VERSION ""

NS_ :

BS_:

BU_: CVC_C EPS WCBS FCAM_C ADCU_C DUMMY_ECU

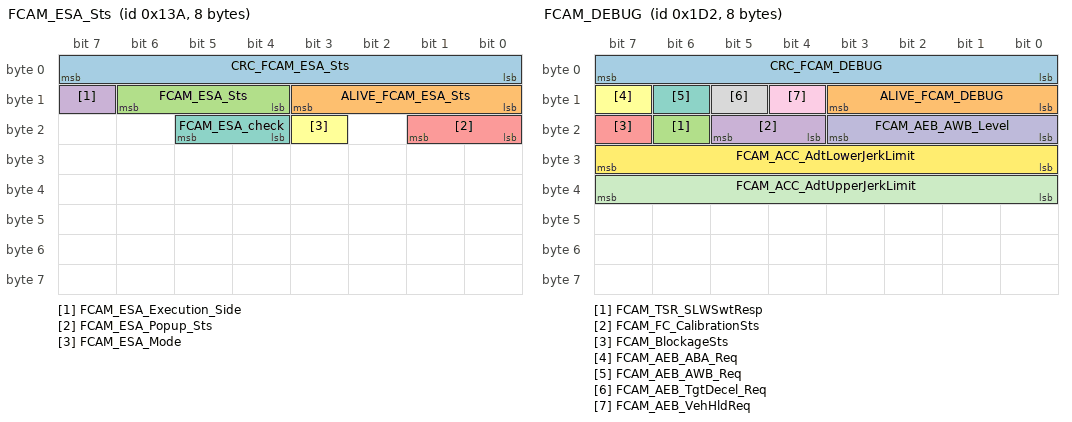
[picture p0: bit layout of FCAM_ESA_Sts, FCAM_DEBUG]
BO_ 314 FCAM_ESA_Sts: 8 FCAM_C
 SG_ CRC_FCAM_ESA_Sts : 7|8@0+ (1,0) [0|255] ""  CVC_C,EPS
 SG_ ALIVE_FCAM_ESA_Sts : 11|4@0+ (1,0) [0|15] ""  CVC_C,EPS
 SG_ FCAM_ESA_Sts : 14|3@0+ (1,0) [0|7] ""  CVC_C,EPS
 SG_ FCAM_ESA_Execution_Side : 15|1@0+ (1,0) [0|1] ""  CVC_C,EPS
 SG_ FCAM_ESA_Popup_Sts : 17|2@0+ (1,0) [0|3] ""  CVC_C,EPS
 SG_ FCAM_ESA_Mode : 19|1@0+ (1,0) [0|1] ""  CVC_C,EPS
 SG_ FCAM_ESA_check : 21|2@0+ (1,0) [0|3] ""  CVC_C,EPS

BO_ 466 FCAM_DEBUG: 8 FCAM_C
 SG_ CRC_FCAM_DEBUG : 7|8@0+ (1,0) [0|255] ""  CVC_C,WCBS,ADCU_C
 SG_ ALIVE_FCAM_DEBUG : 11|4@0+ (1,0) [0|15] ""  CVC_C,WCBS,ADCU_C
 SG_ FCAM_TSR_SLWSwtResp : 22|1@0+ (1,0) [0|1] ""  CVC_C,ADCU_C
 SG_ FCAM_FC_CalibrationSts : 21|2@0+ (1,0) [0|3] ""  CVC_C,ADCU_C
 SG_ FCAM_BlockageSts : 23|1@0+ (1,0) [0|1] ""  CVC_C,ADCU_C
 SG_ FCAM_AEB_ABA_Req : 15|1@0+ (1,0) [0|1] ""  CVC_C,WCBS,ADCU_C
 SG_ FCAM_AEB_AWB_Req : 14|1@0+ (1,0) [0|1] ""  CVC_C,WCBS,ADCU_C
 SG_ FCAM_AEB_TgtDecel_Req : 13|1@0+ (1,0) [0|1] ""  CVC_C,WCBS,ADCU_C
 SG_ FCAM_AEB_VehHldReq : 12|1@0+ (1,0) [0|1] ""  CVC_C,WCBS,ADCU_C
 SG_ FCAM_AEB_AWB_Level : 19|4@0+ (1,0) [0|15] ""  CVC_C,WCBS,ADCU_C
 SG_ FCAM_ACC_AdtUpperJerkLimit : 39|8@0+ (0.1,-12.7) [-12.7|12.7] "m/s3"  CVC_C,WCBS,ADCU_C
 SG_ FCAM_ACC_AdtLowerJerkLimit : 31|8@0+ (0.1,-12.7) [-12.7|12.7] "m/s3"  CVC_C,WCBS,ADCU_C

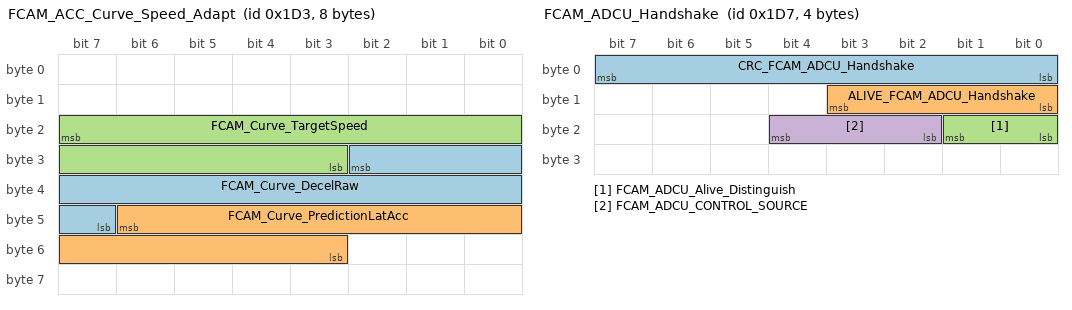
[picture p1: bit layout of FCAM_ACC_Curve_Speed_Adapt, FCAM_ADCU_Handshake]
BO_ 467 FCAM_ACC_Curve_Speed_Adapt: 8 FCAM_C
 SG_ FCAM_Curve_DecelRaw : 26|12@0+ (0.005,-6) [-6|6] "m/s2"  CVC_C
 SG_ FCAM_Curve_PredictionLatAcc : 46|12@0+ (0.005,-6) [-6|6] "m/s2"  CVC_C
 SG_ FCAM_Curve_TargetSpeed : 23|13@0+ (0.05625,0) [0|300] "km/h"  CVC_C

BO_ 471 FCAM_ADCU_Handshake: 4 FCAM_C
 SG_ CRC_FCAM_ADCU_Handshake : 7|8@0+ (1,0) [0|255] ""  ADCU_C
 SG_ ALIVE_FCAM_ADCU_Handshake : 11|4@0+ (1,0) [0|15] ""  ADCU_C
 SG_ FCAM_ADCU_Alive_Distinguish : 17|2@0+ (1,0) [0|2] ""  ADCU_C
 SG_ FCAM_ADCU_CONTROL_SOURCE : 20|3@0+ (1,0) [0|3] ""  ADCU_C

BO_ 813 FCAM_ACC_Status: 24 FCAM_C
 SG_ CRC_FCAM_ACC_Status : 7|8@0+ (1,0) [0|255] ""  CVC_C,WCBS
 SG_ ALIVE_FCAM_ACC_Status : 11|4@0+ (1,0) [0|15] ""  CVC_C,WCBS
 SG_ FCAM_ACC_Information : 14|2@0+ (1,0) [0|3] ""  WCBS
 SG_ FCAM_ACC_Main_Mode : 15|1@0+ (1,0) [0|1] ""  WCBS
 SG_ FCAM_ACC_AccelDecel_Cmd : 19|12@0+ (0.005,-6) [-6|6] "m/s2"  WCBS
 SG_ FCAM_ACC_StandstillReq : 20|1@0+ (1,0) [0|1] ""  WCBS
 SG_ FCAM_ACC_Mode : 23|3@0+ (1,0) [0|7] ""  CVC_C,WCBS
 SG_ FCAM_ACC_IDB_DecCmdAct : 39|3@0+ (1,0) [0|1] ""  WCBS
 SG_ Secure_ResetCnt_0x32D : 135|16@0+ (1,0) [0|65535] ""  CVC_C,WCBS
 SG_ Secure_MsgCnt_0x32D : 151|16@0+ (1,0) [0|65535] ""  CVC_C,WCBS
 SG_ Secure_MAC_0x32D : 167|32@0+ (1,0) [0|4294967295] ""  CVC_C,WCBS

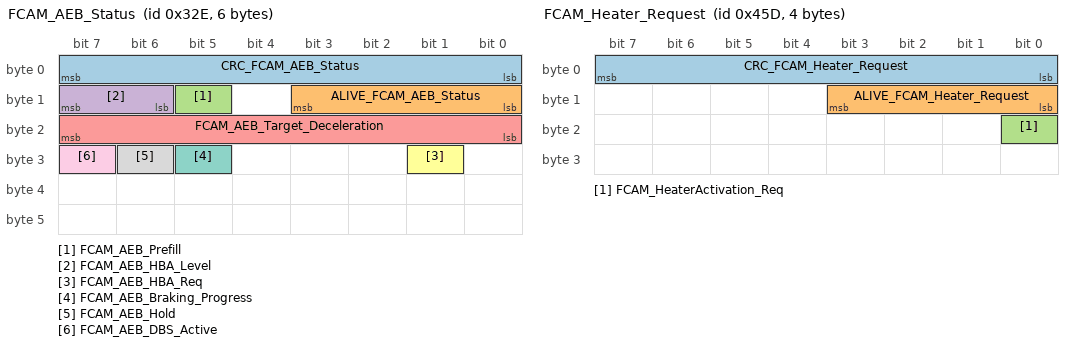
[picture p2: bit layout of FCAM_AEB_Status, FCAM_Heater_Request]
BO_ 814 FCAM_AEB_Status: 6 FCAM_C
 SG_ CRC_FCAM_AEB_Status : 7|8@0+ (1,0) [0|255] ""  CVC_C,WCBS
 SG_ ALIVE_FCAM_AEB_Status : 11|4@0+ (1,0) [0|15] ""  CVC_C,WCBS
 SG_ FCAM_AEB_Prefill : 13|1@0+ (1,0) [0|1] ""  CVC_C,WCBS
 SG_ FCAM_AEB_HBA_Level : 15|2@0+ (1,0) [0|3] ""  CVC_C,WCBS
 SG_ FCAM_AEB_Target_Deceleration : 23|8@0+ (0.1,-12.7) [-12.7|12.8] "m/s2"  CVC_C,WCBS
 SG_ FCAM_AEB_HBA_Req : 25|1@0+ (1,0) [0|1] ""  CVC_C,WCBS
 SG_ FCAM_AEB_Braking_Progress : 29|1@0+ (1,0) [0|1] ""  CVC_C,WCBS
 SG_ FCAM_AEB_Hold : 30|1@0+ (1,0) [0|1] ""  CVC_C,WCBS
 SG_ FCAM_AEB_DBS_Active : 31|1@0+ (1,0) [0|1] ""  CVC_C,WCBS

BO_ 851 FCAM_CMP_ACC: 8 FCAM_C
 SG_ CRC_FCAM_CMP_ACC : 7|8@0+ (1,0) [0|255] ""  WCBS
 SG_ ALIVE_FCAM_CMP_ACC : 11|4@0+ (1,0) [0|15] ""  WCBS
 SG_ FCAM_ACC_ObjDetec : 29|1@0+ (1,0) [0|1] ""  DUMMY_ECU
 SG_ FCAM_ISA_check : 13|2@0+ (1,0) [0|3] ""  DUMMY_ECU
 SG_ FCAM_ISA_Mode_SW_Feed : 15|2@0+ (1,0) [0|3] ""  DUMMY_ECU
 SG_ FCAM_TagSpeed_ICON_Feed : 18|3@0+ (1,0) [0|7] ""  WCBS
 SG_ FCAM_ISA_PopUp_Feed : 23|4@0+ (1,0) [0|15] ""  DUMMY_ECU
 SG_ FCAM_ISA_Btn_Feed : 24|1@0+ (1,0) [0|1] ""  DUMMY_ECU
 SG_ FCAM_ACC_DistSet_upper_Feed : 25|1@0+ (1,0) [0|1] ""  DUMMY_ECU
 SG_ FCAM_ACC_TimeGapSet : 28|3@0+ (1,0) [0|7] ""  DUMMY_ECU
 SG_ FCAM_ACC_State : 47|4@0+ (1,0) [0|15] ""  DUMMY_ECU
 SG_ FCAM_ACC_TagSpeed : 39|8@0+ (1,0) [0|255] "km/h"  WCBS
 SG_ FCAM_ACC_PopUp_Feed : 43|4@0+ (1,0) [0|15] ""  DUMMY_ECU
 SG_ FCAM_ACC_check : 31|2@0+ (1,0) [0|3] ""  DUMMY_ECU
 SG_ FCAM_ISA_ICON_Feed : 50|3@0+ (1,0) [0|7] ""  DUMMY_ECU
 SG_ FCAM_ACC_DistSet_lower_Feed : 51|1@0+ (1,0) [0|1] ""  DUMMY_ECU
 SG_ FCAM_ACC_SpdSet_upper_Feed : 52|1@0+ (1,0) [0|1] ""  DUMMY_ECU
 SG_ FCAM_ACC_SpdSet_lower_Feed : 53|1@0+ (1,0) [0|1] ""  DUMMY_ECU
 SG_ FCAM_ACC_On_Feed : 54|1@0+ (1,0) [0|1] ""  DUMMY_ECU
 SG_ FCAM_ACC_Set_Feed : 55|1@0+ (1,0) [0|1] ""  DUMMY_ECU
 SG_ FCAM_ACC_CnlBtn_Feed : 56|1@0+ (1,0) [0|1] ""  DUMMY_ECU
 SG_ FCAM_ACC_Res_Feed : 57|1@0+ (1,0) [0|1] ""  DUMMY_ECU
 SG_ FCAM_ACC_ICON_Feed : 60|3@0+ (1,0) [0|7] ""  WCBS
 SG_ FCAM_ISA_Status : 63|3@0+ (1,0) [0|7] ""  DUMMY_ECU
 SG_ FCAM_ACC_DriveOff : 19|1@0+ (1,0) [0|1] ""  DUMMY_ECU

BO_ 890 FCAM_EPS_LATE_CON: 24 FCAM_C
 SG_ CRC_FCAM_EPS_LATE_CON : 7|8@0+ (1,0) [0|255] ""  EPS
 SG_ ALIVE_FCAM_EPS_LATE_CON : 11|4@0+ (1,0) [0|15] ""  EPS
 SG_ FCAM_EPS_StrWhe_TOLAct : 25|2@0+ (1,0) [0|3] ""  EPS
 SG_ FCAM_EPS_StrWhe_AOLAct : 27|2@0+ (1,0) [0|3] ""  EPS
 SG_ FCAM_EPS_AOLReq : 39|16@0+ (0.0238,-780) [-780|779.7] "deg"  EPS
 SG_ FCAM_EPS_Torq_Fact_Req : 55|7@0+ (0.01,0) [0|1] ""  EPS
 SG_ FCAM_EPS_DrvTorq_SubFact_Req : 23|7@0+ (0.05,0) [0|1] ""  EPS
 SG_ Secure_ResetCnt_0x37A : 135|16@0+ (1,0) [0|65535] ""  EPS
 SG_ Secure_MsgCnt_0x37A : 151|16@0+ (1,0) [0|65535] ""  EPS
 SG_ Secure_MAC_0x37A : 167|32@0+ (1,0) [0|4294967295] ""  EPS

BO_ 1117 FCAM_Heater_Request: 4 FCAM_C
 SG_ CRC_FCAM_Heater_Request : 7|8@0+ (1,0) [0|255] ""  CVC_C
 SG_ ALIVE_FCAM_Heater_Request : 11|4@0+ (1,0) [0|15] ""  CVC_C
 SG_ FCAM_HeaterActivation_Req : 16|1@0+ (1,0) [0|1] ""  CVC_C

BO_ 853 FCAM_ADAS_CDSMaster: 12 FCAM_C
 SG_ FCAM_ADAS_CDSMaster_BasicCruise : 7|2@0+ (1,0) [0|3] ""  CVC_C
 SG_ FCAM_ADAS_CDSMaster_ALCA : 5|2@0+ (1,0) [0|3] ""  CVC_C,EPS
 SG_ FCAM_ADAS_CDSMaster_AESA : 3|2@0+ (1,0) [0|3] ""  CVC_C,EPS,WCBS
 SG_ FCAM_ADAS_CDSMaster_HWA : 1|2@0+ (1,0) [0|3] ""  CVC_C,EPS,WCBS
 SG_ FCAM_ADAS_CDSMaster_NOP : 15|2@0+ (1,0) [0|3] ""  CVC_C,EPS,WCBS
 SG_ FCAM_ADAS_CDSMaster_ISA : 13|2@0+ (1,0) [0|3] ""  CVC_C
 SG_ FCAM_ADAS_CDSMaster_TSR : 11|2@0+ (1,0) [0|3] ""  CVC_C
 SG_ FCAM_ADAS_CDSMaster_ACC : 9|2@0+ (1,0) [0|3] ""  CVC_C,WCBS
 SG_ FCAM_ADAS_CDSMaster_TLD : 23|2@0+ (1,0) [0|3] ""  CVC_C,EPS,WCBS
 SG_ FCAM_ADAS_CDSMaster_AACC : 21|2@0+ (1,0) [0|3] ""  CVC_C,EPS,WCBS
 SG_ FCAM_ADAS_CDSMaster_ALCM : 19|2@0+ (1,0) [0|3] ""  CVC_C,EPS,WCBS
 SG_ FCAM_ADAS_CDSMaster_AAESA : 17|2@0+ (1,0) [0|3] ""  CVC_C,EPS,WCBS
 SG_ FCAM_ADAS_CDSMaster_ELK : 31|2@0+ (1,0) [0|3] ""  CVC_C,EPS
 SG_ FCAM_ADAS_CDSMaster_LKA : 29|2@0+ (1,0) [0|3] ""  CVC_C,EPS
 SG_ FCAM_ADAS_CDSMaster_LDW : 27|2@0+ (1,0) [0|3] ""  CVC_C,WCBS
 SG_ FCAM_ADAS_CDSMaster_DNS : 25|2@0+ (1,0) [0|3] ""  CVC_C,EPS,WCBS
 SG_ FCAM_ADAS_CDSMaster_FCW : 39|2@0+ (1,0) [0|3] ""  CVC_C
 SG_ FCAM_ADAS_CDSMaster_RAEB : 37|2@0+ (1,0) [0|3] ""  CVC_C,WCBS
 SG_ FCAM_ADAS_CDSMaster_ESA : 35|2@0+ (1,0) [0|3] ""  CVC_C,EPS
 SG_ FCAM_ADAS_CDSMaster_FAEB : 33|2@0+ (1,0) [0|3] ""  CVC_C,WCBS
 SG_ FCAM_ADAS_CDSMaster_RPA : 47|2@0+ (1,0) [0|3] ""  CVC_C,EPS,WCBS
 SG_ FCAM_ADAS_CDSMaster_FPA : 45|2@0+ (1,0) [0|3] ""  CVC_C,EPS,WCBS
 SG_ FCAM_ADAS_CDSMaster_RVC : 43|2@0+ (1,0) [0|3] ""  CVC_C
 SG_ FCAM_ADAS_CDSMaster_SVM : 41|2@0+ (1,0) [0|3] ""  CVC_C
 SG_ FCAM_ADAS_CDSMaster_VParkingComf : 55|2@0+ (1,0) [0|3] ""  CVC_C,EPS,WCBS
 SG_ FCAM_ADAS_CDSMaster_VParkingSele : 53|2@0+ (1,0) [0|3] ""  CVC_C,EPS,WCBS
 SG_ FCAM_ADAS_CDSMaster_RP : 51|2@0+ (1,0) [0|3] ""  CVC_C,EPS,WCBS
 SG_ FCAM_ADAS_CDSMaster_SpaFAPA : 49|2@0+ (1,0) [0|3] ""  CVC_C,EPS,WCBS
 SG_ FCAM_ADAS_CDSMaster_ADB : 63|2@0+ (1,0) [0|3] ""  CVC_C
 SG_ FCAM_ADAS_CDSMaster_AHB : 61|2@0+ (1,0) [0|3] ""  CVC_C
 SG_ FCAM_ADAS_CDSMaster_VParkingAuto : 59|2@0+ (1,0) [0|3] ""  CVC_C,EPS,WCBS
 SG_ FCAM_ADAS_CDSMaster_VParkingSumm : 57|2@0+ (1,0) [0|3] ""  CVC_C,EPS,WCBS
 SG_ FCAM_ADAS_CDSMaster_AdasEDR : 71|2@0+ (1,0) [0|3] ""  CVC_C
 SG_ FCAM_ADAS_CDSMaster_DCM : 69|2@0+ (1,0) [0|3] ""  CVC_C
 SG_ FCAM_ADAS_CDSMaster_DMSFaceID : 67|2@0+ (1,0) [0|3] ""  CVC_C
 SG_ FCAM_ADAS_CDSMaster_DMS : 65|2@0+ (1,0) [0|3] ""  CVC_C
 SG_ FCAM_ADAS_CDSMaster_L2_L2PLUS : 77|2@0+ (1,0) [0|3] ""  CVC_C,EPS,WCBS
 SG_ FCAM_ADAS_CDSMaster_SentryMode : 75|2@0+ (1,0) [0|3] ""  CVC_C
 SG_ FCAM_ADAS_CDSMaster_ACPE : 73|2@0+ (1,0) [0|3] ""  CVC_C,WCBS

BO_ 1970 FCAM_Synchronization_Req: 8 FCAM_C
 SG_ FCAM_C_Req_RandomData : 7|24@0+ (1,0) [0|16777215] ""  CVC_C
 SG_ FCAM_C_Req_MAC : 31|40@0+ (1,0) [0|1099511627775] ""  CVC_C

BO_ 311 EAS_CDC_WorkState: 8 CVC_C
 SG_ CRC_EAS_CDC_WorkState : 7|8@0+ (1,0) [0|255] ""  FCAM_C,ADCU_C
 SG_ ALIVE_EAS_CDC_WorkState : 11|4@0+ (1,0) [0|15] ""  FCAM_C,ADCU_C
 SG_ EAS_StiffStsFL : 12|1@0+ (1,0) [0|1] "" Vector__XXX
 SG_ EAS_StiffStsFR : 13|1@0+ (1,0) [0|1] "" Vector__XXX
 SG_ EAS_StiffStsRL : 14|1@0+ (1,0) [0|1] "" Vector__XXX
 SG_ EAS_StiffStsRR : 15|1@0+ (1,0) [0|1] "" Vector__XXX
 SG_ EAS_WorkSts : 17|2@0+ (1,0) [0|3] ""  FCAM_C,ADCU_C
 SG_ CDC_WorkSts : 19|2@0+ (1,0) [0|3] ""  FCAM_C,ADCU_C
 SG_ EAS_CDC_SystemWorkMode : 21|2@0+ (1,0) [0|3] ""  FCAM_C,ADCU_C
 SG_ EAS_SuspensionMode : 23|2@0+ (1,0) [0|3] ""  FCAM_C,ADCU_C
 SG_ EAS_EasyAccessSts : 25|2@0+ (1,0) [0|3] ""  FCAM_C,ADCU_C
 SG_ CDC_DamperMode : 27|2@0+ (1,0) [0|3] ""  FCAM_C,ADCU_C
 SG_ EAS_ValveValue_FL : 30|3@0+ (1,0) [0|7] ""  FCAM_C,ADCU_C
 SG_ EAS_ValveValue_FR : 34|3@0+ (1,0) [0|7] ""  FCAM_C,ADCU_C
 SG_ EAS_ValveValue_RL : 38|3@0+ (1,0) [0|7] ""  FCAM_C,ADCU_C
 SG_ EAS_ValveValue_RR : 42|3@0+ (1,0) [0|7] ""  FCAM_C,ADCU_C
 SG_ EAS_EnableSts : 31|1@0+ (1,0) [0|1] ""  FCAM_C,ADCU_C
 SG_ CDC_ValveValue_FL : 35|1@0+ (1,0) [0|1] ""  FCAM_C,ADCU_C
 SG_ CDC_ValveValue_FR : 39|1@0+ (1,0) [0|1] ""  FCAM_C,ADCU_C
 SG_ CDC_ValveValue_RL : 43|1@0+ (1,0) [0|1] ""  FCAM_C,ADCU_C
 SG_ CDC_ValveValue_RR : 44|1@0+ (1,0) [0|1] ""  FCAM_C,ADCU_C
 SG_ EAS_MntnSts : 45|1@0+ (1,0) [0|1] ""  FCAM_C,ADCU_C
 SG_ EAS_EasyLoadingSetFb : 47|2@0+ (1,0) [0|3] ""  FCAM_C,ADCU_C
 SG_ EAS_LiftModFb : 49|2@0+ (1,0) [0|3] ""  FCAM_C,ADCU_C
 SG_ EAS_VehicleUpDownState : 51|2@0+ (1,0) [0|3] ""  FCAM_C,ADCU_C
 SG_ EAS_Overheat_Warning : 52|1@0+ (1,0) [0|1] ""  ADCU_C
 SG_ EAS_VehiclePositionState : 55|3@0+ (1,0) [0|7] ""  ADCU_C
 SG_ EAS_VehicleTargetPositionState : 58|3@0+ (1,0) [0|7] ""  ADCU_C

BO_ 555 ADCU_FCAM_ActuatorReq: 12 ADCU_C
 SG_ CRC_ADCU_FCAM_ActuatorReq : 7|8@0+ (1,0) [0|255] ""  FCAM_C
 SG_ ALIVE_ADCU_FCAM_ActuatorReq : 11|4@0+ (1,0) [0|15] ""  FCAM_C
 SG_ ADCU_ACC_AccelDecel_Cmd : 23|12@0+ (0.005,-6) [-6|6] "m/s2"  FCAM_C
 SG_ ADCU_ACC_IDB_DecCmdAct : 27|3@0+ (1,0) [0|1] ""  FCAM_C
 SG_ ADCU_ACC_StandstillReq : 24|1@0+ (1,0) [0|1] ""  FCAM_C
 SG_ ADCU_ACC_Information : 15|2@0+ (1,0) [0|3] ""  FCAM_C
 SG_ ADCU_ACC_DriveOff : 48|1@0+ (1,0) [0|1] ""  FCAM_C
 SG_ ADCU_EPS_AOLReq : 39|16@0+ (0.0238,-780) [-780|779.7] "deg"  FCAM_C
 SG_ ADCU_EPS_StrWhe_AOLAct : 13|2@0+ (1,0) [0|3] ""  FCAM_C
 SG_ ADCU_EPS_StrWhe_TOLAct : 63|2@0+ (1,0) [0|3] ""  FCAM_C
 SG_ ADCU_EPS_Torq_Fact_Req : 55|7@0+ (0.01,0) [0|1] ""  FCAM_C
 SG_ ADCU_LSS_Activation : 58|3@0+ (1,0) [0|7] ""  FCAM_C
 SG_ ADCU_LSS_Activation_2 : 61|3@0+ (1,0) [0|7] ""  FCAM_C
 SG_ ADCU_NOP_state : 71|4@0+ (1,0) [0|15] ""  FCAM_C

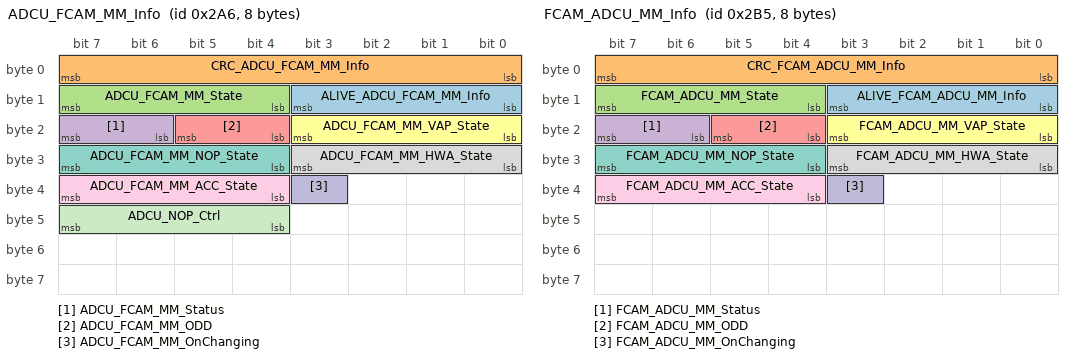
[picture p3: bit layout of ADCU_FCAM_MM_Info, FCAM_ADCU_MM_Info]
BO_ 678 ADCU_FCAM_MM_Info: 8 ADCU_C
 SG_ ALIVE_ADCU_FCAM_MM_Info : 11|4@0+ (1,0) [0|15] ""  FCAM_C
 SG_ CRC_ADCU_FCAM_MM_Info : 7|8@0+ (1,0) [0|255] ""  FCAM_C
 SG_ ADCU_FCAM_MM_State : 15|4@0+ (1,0) [0|15] ""  FCAM_C
 SG_ ADCU_FCAM_MM_Status : 23|2@0+ (1,0) [0|3] ""  FCAM_C
 SG_ ADCU_FCAM_MM_ODD : 21|2@0+ (1,0) [0|3] ""  FCAM_C
 SG_ ADCU_FCAM_MM_VAP_State : 19|4@0+ (1,0) [0|15] ""  FCAM_C
 SG_ ADCU_FCAM_MM_NOP_State : 31|4@0+ (1,0) [0|15] ""  FCAM_C
 SG_ ADCU_FCAM_MM_HWA_State : 27|4@0+ (1,0) [0|15] ""  FCAM_C
 SG_ ADCU_FCAM_MM_ACC_State : 39|4@0+ (1,0) [0|15] ""  FCAM_C
 SG_ ADCU_FCAM_MM_OnChanging : 35|1@0+ (1,0) [0|1] ""  FCAM_C
 SG_ ADCU_NOP_Ctrl : 47|4@0+ (1,0) [0|15] ""  FCAM_C

BO_ 693 FCAM_ADCU_MM_Info: 8 FCAM_C
 SG_ ALIVE_FCAM_ADCU_MM_Info : 11|4@0+ (1,0) [0|15] ""  ADCU_C
 SG_ CRC_FCAM_ADCU_MM_Info : 7|8@0+ (1,0) [0|255] ""  ADCU_C
 SG_ FCAM_ADCU_MM_State : 15|4@0+ (1,0) [0|15] ""  ADCU_C
 SG_ FCAM_ADCU_MM_Status : 23|2@0+ (1,0) [0|3] ""  ADCU_C
 SG_ FCAM_ADCU_MM_ODD : 21|2@0+ (1,0) [0|3] ""  ADCU_C
 SG_ FCAM_ADCU_MM_VAP_State : 19|4@0+ (1,0) [0|15] ""  ADCU_C
 SG_ FCAM_ADCU_MM_NOP_State : 31|4@0+ (1,0) [0|15] ""  ADCU_C
 SG_ FCAM_ADCU_MM_HWA_State : 27|4@0+ (1,0) [0|15] ""  ADCU_C
 SG_ FCAM_ADCU_MM_ACC_State : 39|4@0+ (1,0) [0|15] ""  ADCU_C
 SG_ FCAM_ADCU_MM_OnChanging : 35|1@0+ (1,0) [0|1] ""  ADCU_C

BO_ 821 ADCU_AEB_Status: 12 ADCU_C
 SG_ CRC_ADCU_AEB_Status : 7|8@0+ (1,0) [0|255] ""  WCBS
 SG_ ALIVE_ADCU_AEB_Status : 11|4@0+ (1,0) [0|15] ""  WCBS
 SG_ ADCU_AEB_Prefill : 13|1@0+ (1,0) [0|1] ""  WCBS
 SG_ ADCU_AEB_HBA_Level : 15|2@0+ (1,0) [0|3] ""  WCBS
 SG_ ADCU_AEB_Target_Deceleration : 23|8@0+ (0.1,-12.7) [-12.7|12.8] "m/s2"  WCBS
 SG_ ADCU_AEB_HBA_Req : 25|1@0+ (1,0) [0|1] ""  WCBS
 SG_ ADCU_AEB_Braking_Progress : 29|1@0+ (1,0) [0|1] ""  WCBS
 SG_ ADCU_AEB_Hold : 30|1@0+ (1,0) [0|1] ""  WCBS
 SG_ ADCU_AEB_DBS_Active : 31|1@0+ (1,0) [0|1] ""  WCBS

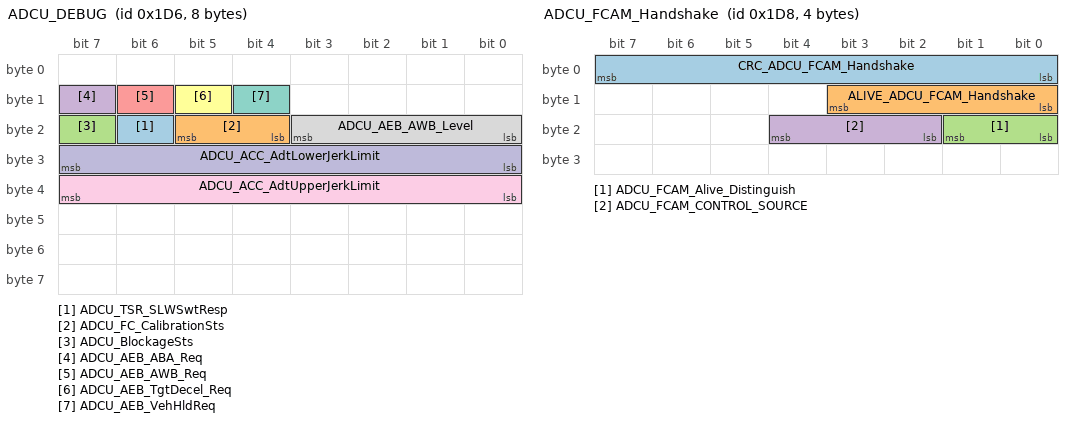
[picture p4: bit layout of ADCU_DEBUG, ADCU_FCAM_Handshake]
BO_ 470 ADCU_DEBUG: 8 ADCU_C
 SG_ ADCU_TSR_SLWSwtResp : 22|1@0+ (1,0) [0|1] ""  CVC_C,WCBS
 SG_ ADCU_FC_CalibrationSts : 21|2@0+ (1,0) [0|3] ""  CVC_C,WCBS
 SG_ ADCU_BlockageSts : 23|1@0+ (1,0) [0|1] ""  CVC_C,WCBS
 SG_ ADCU_AEB_ABA_Req : 15|1@0+ (1,0) [0|1] ""  CVC_C,WCBS
 SG_ ADCU_AEB_AWB_Req : 14|1@0+ (1,0) [0|1] ""  CVC_C,WCBS
 SG_ ADCU_AEB_TgtDecel_Req : 13|1@0+ (1,0) [0|1] ""  CVC_C,WCBS
 SG_ ADCU_AEB_VehHldReq : 12|1@0+ (1,0) [0|1] ""  CVC_C,WCBS
 SG_ ADCU_AEB_AWB_Level : 19|4@0+ (1,0) [0|15] ""  CVC_C,WCBS
 SG_ ADCU_ACC_AdtUpperJerkLimit : 39|8@0+ (0.1,-12.7) [-12.7|12.7] "m/s3"  CVC_C,WCBS
 SG_ ADCU_ACC_AdtLowerJerkLimit : 31|8@0+ (0.1,-12.7) [-12.7|12.7] "m/s3"  CVC_C,WCBS

BO_ 472 ADCU_FCAM_Handshake: 4 ADCU_C
 SG_ CRC_ADCU_FCAM_Handshake : 7|8@0+ (1,0) [0|255] ""  FCAM_C
 SG_ ALIVE_ADCU_FCAM_Handshake : 11|4@0+ (1,0) [0|15] ""  FCAM_C
 SG_ ADCU_FCAM_Alive_Distinguish : 17|2@0+ (1,0) [0|2] ""  FCAM_C
 SG_ ADCU_FCAM_CONTROL_SOURCE : 20|3@0+ (1,0) [0|3] ""  FCAM_C

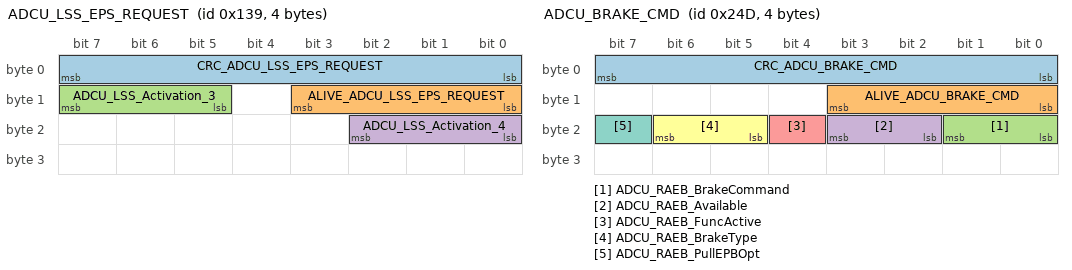
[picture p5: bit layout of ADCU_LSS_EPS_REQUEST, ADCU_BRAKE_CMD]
BO_ 313 ADCU_LSS_EPS_REQUEST: 4 ADCU_C
 SG_ CRC_ADCU_LSS_EPS_REQUEST : 7|8@0+ (1,0) [0|255] ""  EPS
 SG_ ALIVE_ADCU_LSS_EPS_REQUEST : 11|4@0+ (1,0) [0|15] ""  EPS
 SG_ ADCU_LSS_Activation_3 : 15|3@0+ (1,0) [0|7] ""  EPS
 SG_ ADCU_LSS_Activation_4 : 18|3@0+ (1,0) [0|7] ""  EPS

BO_ 589 ADCU_BRAKE_CMD: 4 ADCU_C
 SG_ CRC_ADCU_BRAKE_CMD : 7|8@0+ (1,0) [0|255] ""  WCBS
 SG_ ALIVE_ADCU_BRAKE_CMD : 11|4@0+ (1,0) [0|15] ""  WCBS
 SG_ ADCU_RAEB_BrakeCommand : 17|2@0+ (1,0) [0|3] ""  WCBS
 SG_ ADCU_RAEB_Available : 19|2@0+ (1,0) [0|3] ""  WCBS
 SG_ ADCU_RAEB_FuncActive : 20|1@0+ (1,0) [0|1] ""  WCBS
 SG_ ADCU_RAEB_BrakeType : 22|2@0+ (1,0) [0|3] ""  WCBS
 SG_ ADCU_RAEB_PullEPBOpt : 23|1@0+ (1,0) [0|1] ""  WCBS

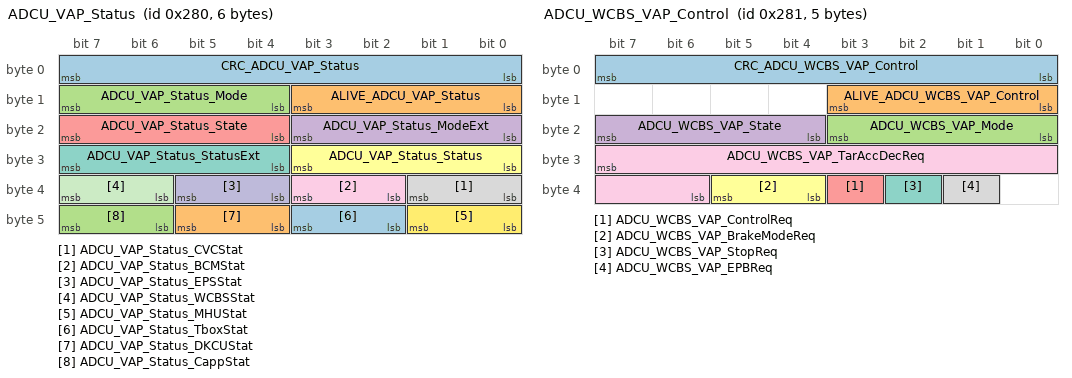
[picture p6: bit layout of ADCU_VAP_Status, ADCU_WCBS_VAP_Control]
BO_ 640 ADCU_VAP_Status: 6 ADCU_C
 SG_ CRC_ADCU_VAP_Status : 7|8@0+ (1,0) [0|255] ""  CVC_C,EPS,WCBS
 SG_ ALIVE_ADCU_VAP_Status : 11|4@0+ (1,0) [0|15] ""  CVC_C,EPS,WCBS
 SG_ ADCU_VAP_Status_Mode : 15|4@0+ (1,0) [0|15] ""  CVC_C,EPS,WCBS
 SG_ ADCU_VAP_Status_ModeExt : 19|4@0+ (1,0) [0|15] ""  CVC_C,EPS,WCBS
 SG_ ADCU_VAP_Status_State : 23|4@0+ (1,0) [0|15] ""  CVC_C,EPS,WCBS
 SG_ ADCU_VAP_Status_Status : 27|4@0+ (1,0) [0|15] ""  CVC_C,EPS,WCBS
 SG_ ADCU_VAP_Status_StatusExt : 31|4@0+ (1,0) [0|15] ""  CVC_C,EPS,WCBS
 SG_ ADCU_VAP_Status_CVCStat : 33|2@0+ (1,0) [0|3] ""  CVC_C,EPS,WCBS
 SG_ ADCU_VAP_Status_BCMStat : 35|2@0+ (1,0) [0|3] ""  CVC_C,EPS,WCBS
 SG_ ADCU_VAP_Status_EPSStat : 37|2@0+ (1,0) [0|3] ""  CVC_C,EPS,WCBS
 SG_ ADCU_VAP_Status_WCBSStat : 39|2@0+ (1,0) [0|3] ""  CVC_C,EPS,WCBS
 SG_ ADCU_VAP_Status_MHUStat : 41|2@0+ (1,0) [0|3] ""  CVC_C,EPS,WCBS
 SG_ ADCU_VAP_Status_TboxStat : 43|2@0+ (1,0) [0|3] ""  CVC_C,EPS,WCBS
 SG_ ADCU_VAP_Status_DKCUStat : 45|2@0+ (1,0) [0|3] ""  CVC_C,EPS,WCBS
 SG_ ADCU_VAP_Status_CappStat : 47|2@0+ (1,0) [0|3] ""  CVC_C,EPS,WCBS

BO_ 641 ADCU_WCBS_VAP_Control: 5 ADCU_C
 SG_ CRC_ADCU_WCBS_VAP_Control : 7|8@0+ (1,0) [0|255] ""  WCBS
 SG_ ALIVE_ADCU_WCBS_VAP_Control : 11|4@0+ (1,0) [0|15] ""  WCBS
 SG_ ADCU_WCBS_VAP_Mode : 19|4@0+ (1,0) [0|15] ""  WCBS
 SG_ ADCU_WCBS_VAP_State : 23|4@0+ (1,0) [0|15] ""  WCBS
 SG_ ADCU_WCBS_VAP_ControlReq : 35|1@0+ (1,0) [0|1] ""  WCBS
 SG_ ADCU_WCBS_VAP_BrakeModeReq : 37|2@0+ (1,0) [0|3] ""  WCBS
 SG_ ADCU_WCBS_VAP_StopReq : 34|1@0+ (1,0) [0|1] ""  WCBS
 SG_ ADCU_WCBS_VAP_EPBReq : 33|1@0+ (1,0) [0|1] ""  WCBS
 SG_ ADCU_WCBS_VAP_TarAccDecReq : 31|10@0+ (0.02,-10) [-10|3] "m/s2"  WCBS

BO_ 642 ADCU_CVC_VAP_Control: 6 ADCU_C
 SG_ CRC_ADCU_CVC_VAP_Control : 7|8@0+ (1,0) [0|255] ""  CVC_C
 SG_ ALIVE_ADCU_CVC_VAP_Control : 11|4@0+ (1,0) [0|15] ""  CVC_C
 SG_ ADCU_CVC_VAP_Mode : 19|4@0+ (1,0) [0|15] ""  CVC_C
 SG_ ADCU_CVC_VAP_State : 23|4@0+ (1,0) [0|15] ""  CVC_C
 SG_ ADCU_CVC_VAP_ControlReq : 24|1@0+ (1,0) [0|1] ""  CVC_C
 SG_ ADCU_CVC_VAP_GearReq : 25|1@0+ (1,0) [0|1] ""  CVC_C
 SG_ ADCU_BCM_VAP_ControlReq : 26|1@0+ (1,0) [0|1] ""  CVC_C
 SG_ ADCU_BCM_VAP_LightReq : 27|1@0+ (1,0) [0|1] ""  CVC_C
 SG_ ADCU_BCM_VAP_Lights : 29|2@0+ (1,0) [0|1] ""  CVC_C
 SG_ ADCU_BCM_VAP_IndicatorLightReq : 32|1@0+ (1,0) [0|1] ""  CVC_C
 SG_ ADCU_BCM_VAP_IndicatorLights : 31|2@0+ (1,0) [0|3] ""  CVC_C
 SG_ ADCU_BCM_VAP_MirrorReq : 33|1@0+ (1,0) [0|1] ""  CVC_C
 SG_ ADCU_BCM_VAP_Mirrors : 37|2@0+ (1,0) [0|3] ""  CVC_C
 SG_ ADCU_BCM_VAP_WindowReq : 34|1@0+ (1,0) [0|1] ""  CVC_C
 SG_ ADCU_BCM_VAP_Windows : 39|2@0+ (1,0) [0|3] ""  CVC_C
 SG_ ADCU_BCM_VAP_DoorReq : 35|1@0+ (1,0) [0|1] ""  CVC_C
 SG_ ADCU_BCM_VAP_Doors : 15|2@0+ (1,0) [0|3] ""  CVC_C
 SG_ ADCU_BCM_VAP_TrunkReq : 13|1@0+ (1,0) [0|1] ""  CVC_C
 SG_ ADCU_BCM_VAP_HornReq : 12|1@0+ (1,0) [0|1] ""  CVC_C
 SG_ ADCU_CVC_VAP_GearPosReq : 47|3@0+ (1,0) [0|7] ""  CVC_C

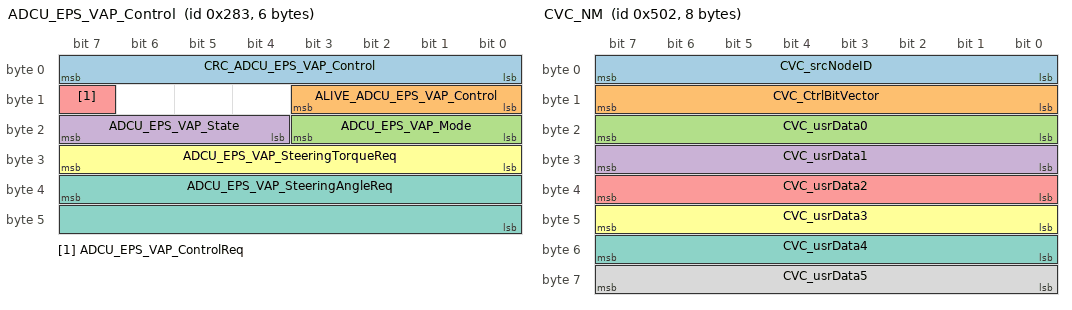
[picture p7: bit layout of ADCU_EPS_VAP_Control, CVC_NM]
BO_ 643 ADCU_EPS_VAP_Control: 6 ADCU_C
 SG_ CRC_ADCU_EPS_VAP_Control : 7|8@0+ (1,0) [0|255] ""  EPS
 SG_ ALIVE_ADCU_EPS_VAP_Control : 11|4@0+ (1,0) [0|15] ""  EPS
 SG_ ADCU_EPS_VAP_Mode : 19|4@0+ (1,0) [0|15] ""  EPS
 SG_ ADCU_EPS_VAP_State : 23|4@0+ (1,0) [0|15] ""  EPS
 SG_ ADCU_EPS_VAP_ControlReq : 15|1@0+ (1,0) [0|1] ""  EPS
 SG_ ADCU_EPS_VAP_SteeringTorqueReq : 31|8@0+ (0.1,-10) [-10|10] "Nm"  EPS
 SG_ ADCU_EPS_VAP_SteeringAngleReq : 39|16@0+ (0.0238,-780) [-780|779.7] "deg"  EPS

BO_ 1282 CVC_NM: 8 CVC_C
 SG_ CVC_srcNodeID : 7|8@0+ (1,0) [0|255] ""  EPS,WCBS,FCAM_C,ADCU_C
 SG_ CVC_CtrlBitVector : 15|8@0+ (1,0) [0|255] ""  EPS,WCBS,FCAM_C,ADCU_C
 SG_ CVC_usrData0 : 23|8@0+ (1,0) [0|255] ""  EPS,WCBS,FCAM_C,ADCU_C
 SG_ CVC_usrData1 : 31|8@0+ (1,0) [0|255] ""  EPS,WCBS,FCAM_C,ADCU_C
 SG_ CVC_usrData2 : 39|8@0+ (1,0) [0|255] ""  EPS,WCBS,FCAM_C,ADCU_C
 SG_ CVC_usrData3 : 47|8@0+ (1,0) [0|255] ""  EPS,WCBS,FCAM_C,ADCU_C
 SG_ CVC_usrData4 : 55|8@0+ (1,0) [0|255] ""  EPS,WCBS,FCAM_C,ADCU_C
 SG_ CVC_usrData5 : 63|8@0+ (1,0) [0|255] ""  EPS,WCBS,FCAM_C,ADCU_C

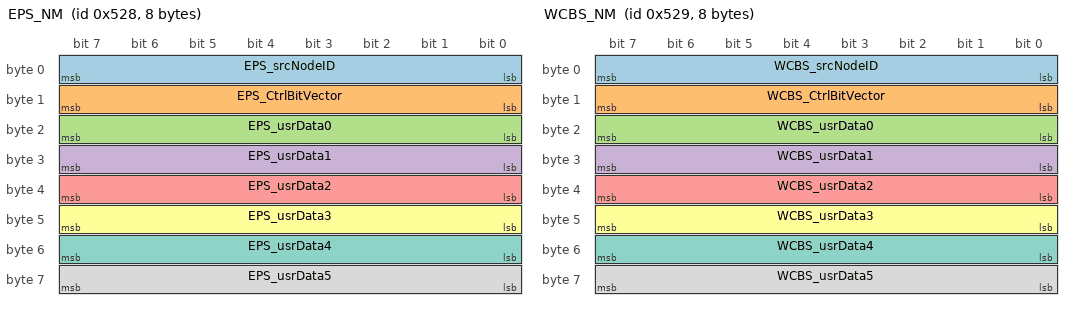
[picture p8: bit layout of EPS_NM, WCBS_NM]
BO_ 1320 EPS_NM: 8 EPS
 SG_ EPS_srcNodeID : 7|8@0+ (1,0) [0|255] ""  CVC_C,WCBS,FCAM_C,ADCU_C
 SG_ EPS_CtrlBitVector : 15|8@0+ (1,0) [0|255] ""  CVC_C,WCBS,FCAM_C,ADCU_C
 SG_ EPS_usrData0 : 23|8@0+ (1,0) [0|255] ""  CVC_C,WCBS,FCAM_C,ADCU_C
 SG_ EPS_usrData1 : 31|8@0+ (1,0) [0|255] ""  CVC_C,WCBS,FCAM_C,ADCU_C
 SG_ EPS_usrData2 : 39|8@0+ (1,0) [0|255] ""  CVC_C,WCBS,FCAM_C,ADCU_C
 SG_ EPS_usrData3 : 47|8@0+ (1,0) [0|255] ""  CVC_C,WCBS,FCAM_C,ADCU_C
 SG_ EPS_usrData4 : 55|8@0+ (1,0) [0|255] ""  CVC_C,WCBS,FCAM_C,ADCU_C
 SG_ EPS_usrData5 : 63|8@0+ (1,0) [0|255] ""  CVC_C,WCBS,FCAM_C,ADCU_C

BO_ 1321 WCBS_NM: 8 WCBS
 SG_ WCBS_srcNodeID : 7|8@0+ (1,0) [0|255] ""  CVC_C,EPS,FCAM_C,ADCU_C
 SG_ WCBS_CtrlBitVector : 15|8@0+ (1,0) [0|255] ""  CVC_C,EPS,FCAM_C,ADCU_C
 SG_ WCBS_usrData0 : 23|8@0+ (1,0) [0|255] ""  CVC_C,EPS,FCAM_C,ADCU_C
 SG_ WCBS_usrData1 : 31|8@0+ (1,0) [0|255] ""  CVC_C,EPS,FCAM_C,ADCU_C
 SG_ WCBS_usrData2 : 39|8@0+ (1,0) [0|255] ""  CVC_C,EPS,FCAM_C,ADCU_C
 SG_ WCBS_usrData3 : 47|8@0+ (1,0) [0|255] ""  CVC_C,EPS,FCAM_C,ADCU_C
 SG_ WCBS_usrData4 : 55|8@0+ (1,0) [0|255] ""  CVC_C,EPS,FCAM_C,ADCU_C
 SG_ WCBS_usrData5 : 63|8@0+ (1,0) [0|255] ""  CVC_C,EPS,FCAM_C,ADCU_C

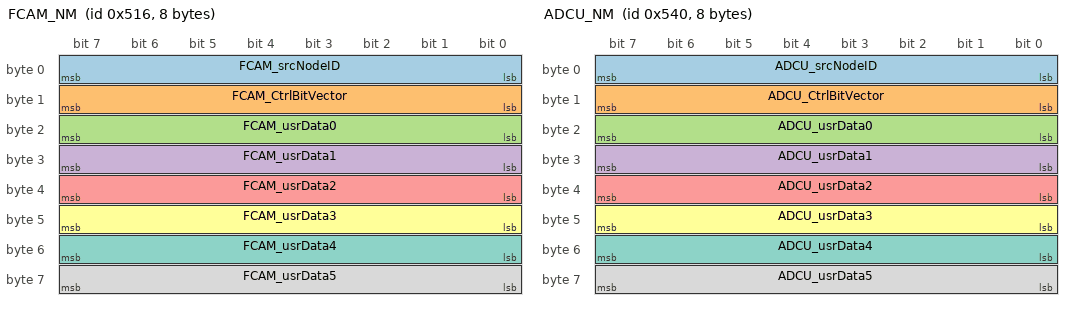
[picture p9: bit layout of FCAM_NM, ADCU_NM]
BO_ 1302 FCAM_NM: 8 FCAM_C
 SG_ FCAM_srcNodeID : 7|8@0+ (1,0) [0|255] ""  CVC_C,EPS,WCBS,ADCU_C
 SG_ FCAM_CtrlBitVector : 15|8@0+ (1,0) [0|255] ""  CVC_C,EPS,WCBS,ADCU_C
 SG_ FCAM_usrData0 : 23|8@0+ (1,0) [0|255] ""  CVC_C,EPS,WCBS,ADCU_C
 SG_ FCAM_usrData1 : 31|8@0+ (1,0) [0|255] ""  CVC_C,EPS,WCBS,ADCU_C
 SG_ FCAM_usrData2 : 39|8@0+ (1,0) [0|255] ""  CVC_C,EPS,WCBS,ADCU_C
 SG_ FCAM_usrData3 : 47|8@0+ (1,0) [0|255] ""  CVC_C,EPS,WCBS,ADCU_C
 SG_ FCAM_usrData4 : 55|8@0+ (1,0) [0|255] ""  CVC_C,EPS,WCBS,ADCU_C
 SG_ FCAM_usrData5 : 63|8@0+ (1,0) [0|255] ""  CVC_C,EPS,WCBS,ADCU_C

BO_ 1344 ADCU_NM: 8 ADCU_C
 SG_ ADCU_srcNodeID : 7|8@0+ (1,0) [0|255] ""  CVC_C,EPS,WCBS,FCAM_C
 SG_ ADCU_CtrlBitVector : 15|8@0+ (1,0) [0|255] ""  CVC_C,EPS,WCBS,FCAM_C
 SG_ ADCU_usrData0 : 23|8@0+ (1,0) [0|255] ""  CVC_C,EPS,WCBS,FCAM_C
 SG_ ADCU_usrData1 : 31|8@0+ (1,0) [0|255] ""  CVC_C,EPS,WCBS,FCAM_C
 SG_ ADCU_usrData2 : 39|8@0+ (1,0) [0|255] ""  CVC_C,EPS,WCBS,FCAM_C
 SG_ ADCU_usrData3 : 47|8@0+ (1,0) [0|255] ""  CVC_C,EPS,WCBS,FCAM_C
 SG_ ADCU_usrData4 : 55|8@0+ (1,0) [0|255] ""  CVC_C,EPS,WCBS,FCAM_C
 SG_ ADCU_usrData5 : 63|8@0+ (1,0) [0|255] ""  CVC_C,EPS,WCBS,FCAM_C

BO_ 1704 EPS_DiagReq: 64 CVC_C
 SG_ EPS_DiagReqData0 : 7|8@0+ (1,0) [0|255] ""  EPS
 SG_ EPS_DiagReqData1 : 15|8@0+ (1,0) [0|255] ""  EPS
 SG_ EPS_DiagReqData2 : 23|8@0+ (1,0) [0|255] ""  EPS
 SG_ EPS_DiagReqData3 : 31|8@0+ (1,0) [0|255] ""  EPS
 SG_ EPS_DiagReqData4 : 39|8@0+ (1,0) [0|255] ""  EPS
 SG_ EPS_DiagReqData5 : 47|8@0+ (1,0) [0|255] ""  EPS
 SG_ EPS_DiagReqData6 : 55|8@0+ (1,0) [0|255] ""  EPS
 SG_ EPS_DiagReqData7 : 63|8@0+ (1,0) [0|255] ""  EPS
 SG_ EPS_DiagReqData8 : 71|8@0+ (1,0) [0|255] ""  EPS
 SG_ EPS_DiagReqData9 : 79|8@0+ (1,0) [0|255] ""  EPS
 SG_ EPS_DiagReqData10 : 87|8@0+ (1,0) [0|255] ""  EPS
 SG_ EPS_DiagReqData11 : 95|8@0+ (1,0) [0|255] ""  EPS
 SG_ EPS_DiagReqData12 : 103|8@0+ (1,0) [0|255] ""  EPS
 SG_ EPS_DiagReqData13 : 111|8@0+ (1,0) [0|255] ""  EPS
 SG_ EPS_DiagReqData14 : 119|8@0+ (1,0) [0|255] ""  EPS
 SG_ EPS_DiagReqData15 : 127|8@0+ (1,0) [0|255] ""  EPS
 SG_ EPS_DiagReqData16 : 135|8@0+ (1,0) [0|255] ""  EPS
 SG_ EPS_DiagReqData17 : 143|8@0+ (1,0) [0|255] ""  EPS
 SG_ EPS_DiagReqData18 : 151|8@0+ (1,0) [0|255] ""  EPS
 SG_ EPS_DiagReqData19 : 159|8@0+ (1,0) [0|255] ""  EPS
 SG_ EPS_DiagReqData20 : 167|8@0+ (1,0) [0|255] ""  EPS
 SG_ EPS_DiagReqData21 : 175|8@0+ (1,0) [0|255] ""  EPS
 SG_ EPS_DiagReqData22 : 183|8@0+ (1,0) [0|255] ""  EPS
 SG_ EPS_DiagReqData23 : 191|8@0+ (1,0) [0|255] ""  EPS
 SG_ EPS_DiagReqData24 : 199|8@0+ (1,0) [0|255] ""  EPS
 SG_ EPS_DiagReqData25 : 207|8@0+ (1,0) [0|255] ""  EPS
 SG_ EPS_DiagReqData26 : 215|8@0+ (1,0) [0|255] ""  EPS
 SG_ EPS_DiagReqData27 : 223|8@0+ (1,0) [0|255] ""  EPS
 SG_ EPS_DiagReqData28 : 231|8@0+ (1,0) [0|255] ""  EPS
 SG_ EPS_DiagReqData29 : 239|8@0+ (1,0) [0|255] ""  EPS
 SG_ EPS_DiagReqData30 : 247|8@0+ (1,0) [0|255] ""  EPS
 SG_ EPS_DiagReqData31 : 255|8@0+ (1,0) [0|255] ""  EPS
 SG_ EPS_DiagReqData32 : 263|8@0+ (1,0) [0|255] ""  EPS
 SG_ EPS_DiagReqData33 : 271|8@0+ (1,0) [0|255] ""  EPS
 SG_ EPS_DiagReqData34 : 279|8@0+ (1,0) [0|255] ""  EPS
 SG_ EPS_DiagReqData35 : 287|8@0+ (1,0) [0|255] ""  EPS
 SG_ EPS_DiagReqData36 : 295|8@0+ (1,0) [0|255] ""  EPS
 SG_ EPS_DiagReqData37 : 303|8@0+ (1,0) [0|255] ""  EPS
 SG_ EPS_DiagReqData38 : 311|8@0+ (1,0) [0|255] ""  EPS
 SG_ EPS_DiagReqData39 : 319|8@0+ (1,0) [0|255] ""  EPS
 SG_ EPS_DiagReqData40 : 327|8@0+ (1,0) [0|255] ""  EPS
 SG_ EPS_DiagReqData41 : 335|8@0+ (1,0) [0|255] ""  EPS
 SG_ EPS_DiagReqData42 : 343|8@0+ (1,0) [0|255] ""  EPS
 SG_ EPS_DiagReqData43 : 351|8@0+ (1,0) [0|255] ""  EPS
 SG_ EPS_DiagReqData44 : 359|8@0+ (1,0) [0|255] ""  EPS
 SG_ EPS_DiagReqData45 : 367|8@0+ (1,0) [0|255] ""  EPS
 SG_ EPS_DiagReqData46 : 375|8@0+ (1,0) [0|255] ""  EPS
 SG_ EPS_DiagReqData47 : 383|8@0+ (1,0) [0|255] ""  EPS
 SG_ EPS_DiagReqData48 : 391|8@0+ (1,0) [0|255] ""  EPS
 SG_ EPS_DiagReqData49 : 399|8@0+ (1,0) [0|255] ""  EPS
 SG_ EPS_DiagReqData50 : 407|8@0+ (1,0) [0|255] ""  EPS
 SG_ EPS_DiagReqData51 : 415|8@0+ (1,0) [0|255] ""  EPS
 SG_ EPS_DiagReqData52 : 423|8@0+ (1,0) [0|255] ""  EPS
 SG_ EPS_DiagReqData53 : 431|8@0+ (1,0) [0|255] ""  EPS
 SG_ EPS_DiagReqData54 : 439|8@0+ (1,0) [0|255] ""  EPS
 SG_ EPS_DiagReqData55 : 447|8@0+ (1,0) [0|255] ""  EPS
 SG_ EPS_DiagReqData56 : 455|8@0+ (1,0) [0|255] ""  EPS
 SG_ EPS_DiagReqData57 : 463|8@0+ (1,0) [0|255] ""  EPS
 SG_ EPS_DiagReqData58 : 471|8@0+ (1,0) [0|255] ""  EPS
 SG_ EPS_DiagReqData59 : 479|8@0+ (1,0) [0|255] ""  EPS
 SG_ EPS_DiagReqData60 : 487|8@0+ (1,0) [0|255] ""  EPS
 SG_ EPS_DiagReqData61 : 495|8@0+ (1,0) [0|255] ""  EPS
 SG_ EPS_DiagReqData62 : 503|8@0+ (1,0) [0|255] ""  EPS
 SG_ EPS_DiagReqData63 : 511|8@0+ (1,0) [0|255] ""  EPS

BO_ 1576 EPS_DiagResp: 64 EPS
 SG_ EPS_DiagRespData0 : 7|8@0+ (1,0) [0|255] ""  CVC_C
 SG_ EPS_DiagRespData1 : 15|8@0+ (1,0) [0|255] ""  CVC_C
 SG_ EPS_DiagRespData2 : 23|8@0+ (1,0) [0|255] ""  CVC_C
 SG_ EPS_DiagRespData3 : 31|8@0+ (1,0) [0|255] ""  CVC_C
 SG_ EPS_DiagRespData4 : 39|8@0+ (1,0) [0|255] ""  CVC_C
 SG_ EPS_DiagRespData5 : 47|8@0+ (1,0) [0|255] ""  CVC_C
 SG_ EPS_DiagRespData6 : 55|8@0+ (1,0) [0|255] ""  CVC_C
 SG_ EPS_DiagRespData7 : 63|8@0+ (1,0) [0|255] ""  CVC_C
 SG_ EPS_DiagRespData8 : 71|8@0+ (1,0) [0|255] ""  CVC_C
 SG_ EPS_DiagRespData9 : 79|8@0+ (1,0) [0|255] ""  CVC_C
 SG_ EPS_DiagRespData10 : 87|8@0+ (1,0) [0|255] ""  CVC_C
 SG_ EPS_DiagRespData11 : 95|8@0+ (1,0) [0|255] ""  CVC_C
 SG_ EPS_DiagRespData12 : 103|8@0+ (1,0) [0|255] ""  CVC_C
 SG_ EPS_DiagRespData13 : 111|8@0+ (1,0) [0|255] ""  CVC_C
 SG_ EPS_DiagRespData14 : 119|8@0+ (1,0) [0|255] ""  CVC_C
 SG_ EPS_DiagRespData15 : 127|8@0+ (1,0) [0|255] ""  CVC_C
 SG_ EPS_DiagRespData16 : 135|8@0+ (1,0) [0|255] ""  CVC_C
 SG_ EPS_DiagRespData17 : 143|8@0+ (1,0) [0|255] ""  CVC_C
 SG_ EPS_DiagRespData18 : 151|8@0+ (1,0) [0|255] ""  CVC_C
 SG_ EPS_DiagRespData19 : 159|8@0+ (1,0) [0|255] ""  CVC_C
 SG_ EPS_DiagRespData20 : 167|8@0+ (1,0) [0|255] ""  CVC_C
 SG_ EPS_DiagRespData21 : 175|8@0+ (1,0) [0|255] ""  CVC_C
 SG_ EPS_DiagRespData22 : 183|8@0+ (1,0) [0|255] ""  CVC_C
 SG_ EPS_DiagRespData23 : 191|8@0+ (1,0) [0|255] ""  CVC_C
 SG_ EPS_DiagRespData24 : 199|8@0+ (1,0) [0|255] ""  CVC_C
 SG_ EPS_DiagRespData25 : 207|8@0+ (1,0) [0|255] ""  CVC_C
 SG_ EPS_DiagRespData26 : 215|8@0+ (1,0) [0|255] ""  CVC_C
 SG_ EPS_DiagRespData27 : 223|8@0+ (1,0) [0|255] ""  CVC_C
 SG_ EPS_DiagRespData28 : 231|8@0+ (1,0) [0|255] ""  CVC_C
 SG_ EPS_DiagRespData29 : 239|8@0+ (1,0) [0|255] ""  CVC_C
 SG_ EPS_DiagRespData30 : 247|8@0+ (1,0) [0|255] ""  CVC_C
 SG_ EPS_DiagRespData31 : 255|8@0+ (1,0) [0|255] ""  CVC_C
 SG_ EPS_DiagRespData32 : 263|8@0+ (1,0) [0|255] ""  CVC_C
 SG_ EPS_DiagRespData33 : 271|8@0+ (1,0) [0|255] ""  CVC_C
 SG_ EPS_DiagRespData34 : 279|8@0+ (1,0) [0|255] ""  CVC_C
 SG_ EPS_DiagRespData35 : 287|8@0+ (1,0) [0|255] ""  CVC_C
 SG_ EPS_DiagRespData36 : 295|8@0+ (1,0) [0|255] ""  CVC_C
 SG_ EPS_DiagRespData37 : 303|8@0+ (1,0) [0|255] ""  CVC_C
 SG_ EPS_DiagRespData38 : 311|8@0+ (1,0) [0|255] ""  CVC_C
 SG_ EPS_DiagRespData39 : 319|8@0+ (1,0) [0|255] ""  CVC_C
 SG_ EPS_DiagRespData40 : 327|8@0+ (1,0) [0|255] ""  CVC_C
 SG_ EPS_DiagRespData41 : 335|8@0+ (1,0) [0|255] ""  CVC_C
 SG_ EPS_DiagRespData42 : 343|8@0+ (1,0) [0|255] ""  CVC_C
 SG_ EPS_DiagRespData43 : 351|8@0+ (1,0) [0|255] ""  CVC_C
 SG_ EPS_DiagRespData44 : 359|8@0+ (1,0) [0|255] ""  CVC_C
 SG_ EPS_DiagRespData45 : 367|8@0+ (1,0) [0|255] ""  CVC_C
 SG_ EPS_DiagRespData46 : 375|8@0+ (1,0) [0|255] ""  CVC_C
 SG_ EPS_DiagRespData47 : 383|8@0+ (1,0) [0|255] ""  CVC_C
 SG_ EPS_DiagRespData48 : 391|8@0+ (1,0) [0|255] ""  CVC_C
 SG_ EPS_DiagRespData49 : 399|8@0+ (1,0) [0|255] ""  CVC_C
 SG_ EPS_DiagRespData50 : 407|8@0+ (1,0) [0|255] ""  CVC_C
 SG_ EPS_DiagRespData51 : 415|8@0+ (1,0) [0|255] ""  CVC_C
 SG_ EPS_DiagRespData52 : 423|8@0+ (1,0) [0|255] ""  CVC_C
 SG_ EPS_DiagRespData53 : 431|8@0+ (1,0) [0|255] ""  CVC_C
 SG_ EPS_DiagRespData54 : 439|8@0+ (1,0) [0|255] ""  CVC_C
 SG_ EPS_DiagRespData55 : 447|8@0+ (1,0) [0|255] ""  CVC_C
 SG_ EPS_DiagRespData56 : 455|8@0+ (1,0) [0|255] ""  CVC_C
 SG_ EPS_DiagRespData57 : 463|8@0+ (1,0) [0|255] ""  CVC_C
 SG_ EPS_DiagRespData58 : 471|8@0+ (1,0) [0|255] ""  CVC_C
 SG_ EPS_DiagRespData59 : 479|8@0+ (1,0) [0|255] ""  CVC_C
 SG_ EPS_DiagRespData60 : 487|8@0+ (1,0) [0|255] ""  CVC_C
 SG_ EPS_DiagRespData61 : 495|8@0+ (1,0) [0|255] ""  CVC_C
 SG_ EPS_DiagRespData62 : 503|8@0+ (1,0) [0|255] ""  CVC_C
 SG_ EPS_DiagRespData63 : 511|8@0+ (1,0) [0|255] ""  CVC_C

BO_ 1705 WCBS_DiagReq: 64 CVC_C
 SG_ WCBS_DiagReqData0 : 7|8@0+ (1,0) [0|255] ""  WCBS
 SG_ WCBS_DiagReqData1 : 15|8@0+ (1,0) [0|255] ""  WCBS
 SG_ WCBS_DiagReqData2 : 23|8@0+ (1,0) [0|255] ""  WCBS
 SG_ WCBS_DiagReqData3 : 31|8@0+ (1,0) [0|255] ""  WCBS
 SG_ WCBS_DiagReqData4 : 39|8@0+ (1,0) [0|255] ""  WCBS
 SG_ WCBS_DiagReqData5 : 47|8@0+ (1,0) [0|255] ""  WCBS
 SG_ WCBS_DiagReqData6 : 55|8@0+ (1,0) [0|255] ""  WCBS
 SG_ WCBS_DiagReqData7 : 63|8@0+ (1,0) [0|255] ""  WCBS
 SG_ WCBS_DiagReqData8 : 71|8@0+ (1,0) [0|255] ""  WCBS
 SG_ WCBS_DiagReqData9 : 79|8@0+ (1,0) [0|255] ""  WCBS
 SG_ WCBS_DiagReqData10 : 87|8@0+ (1,0) [0|255] ""  WCBS
 SG_ WCBS_DiagReqData11 : 95|8@0+ (1,0) [0|255] ""  WCBS
 SG_ WCBS_DiagReqData12 : 103|8@0+ (1,0) [0|255] ""  WCBS
 SG_ WCBS_DiagReqData13 : 111|8@0+ (1,0) [0|255] ""  WCBS
 SG_ WCBS_DiagReqData14 : 119|8@0+ (1,0) [0|255] ""  WCBS
 SG_ WCBS_DiagReqData15 : 127|8@0+ (1,0) [0|255] ""  WCBS
 SG_ WCBS_DiagReqData16 : 135|8@0+ (1,0) [0|255] ""  WCBS
 SG_ WCBS_DiagReqData17 : 143|8@0+ (1,0) [0|255] ""  WCBS
 SG_ WCBS_DiagReqData18 : 151|8@0+ (1,0) [0|255] ""  WCBS
 SG_ WCBS_DiagReqData19 : 159|8@0+ (1,0) [0|255] ""  WCBS
 SG_ WCBS_DiagReqData20 : 167|8@0+ (1,0) [0|255] ""  WCBS
 SG_ WCBS_DiagReqData21 : 175|8@0+ (1,0) [0|255] ""  WCBS
 SG_ WCBS_DiagReqData22 : 183|8@0+ (1,0) [0|255] ""  WCBS
 SG_ WCBS_DiagReqData23 : 191|8@0+ (1,0) [0|255] ""  WCBS
 SG_ WCBS_DiagReqData24 : 199|8@0+ (1,0) [0|255] ""  WCBS
 SG_ WCBS_DiagReqData25 : 207|8@0+ (1,0) [0|255] ""  WCBS
 SG_ WCBS_DiagReqData26 : 215|8@0+ (1,0) [0|255] ""  WCBS
 SG_ WCBS_DiagReqData27 : 223|8@0+ (1,0) [0|255] ""  WCBS
 SG_ WCBS_DiagReqData28 : 231|8@0+ (1,0) [0|255] ""  WCBS
 SG_ WCBS_DiagReqData29 : 239|8@0+ (1,0) [0|255] ""  WCBS
 SG_ WCBS_DiagReqData30 : 247|8@0+ (1,0) [0|255] ""  WCBS
 SG_ WCBS_DiagReqData31 : 255|8@0+ (1,0) [0|255] ""  WCBS
 SG_ WCBS_DiagReqData32 : 263|8@0+ (1,0) [0|255] ""  WCBS
 SG_ WCBS_DiagReqData33 : 271|8@0+ (1,0) [0|255] ""  WCBS
 SG_ WCBS_DiagReqData34 : 279|8@0+ (1,0) [0|255] ""  WCBS
 SG_ WCBS_DiagReqData35 : 287|8@0+ (1,0) [0|255] ""  WCBS
 SG_ WCBS_DiagReqData36 : 295|8@0+ (1,0) [0|255] ""  WCBS
 SG_ WCBS_DiagReqData37 : 303|8@0+ (1,0) [0|255] ""  WCBS
 SG_ WCBS_DiagReqData38 : 311|8@0+ (1,0) [0|255] ""  WCBS
 SG_ WCBS_DiagReqData39 : 319|8@0+ (1,0) [0|255] ""  WCBS
 SG_ WCBS_DiagReqData40 : 327|8@0+ (1,0) [0|255] ""  WCBS
 SG_ WCBS_DiagReqData41 : 335|8@0+ (1,0) [0|255] ""  WCBS
 SG_ WCBS_DiagReqData42 : 343|8@0+ (1,0) [0|255] ""  WCBS
 SG_ WCBS_DiagReqData43 : 351|8@0+ (1,0) [0|255] ""  WCBS
 SG_ WCBS_DiagReqData44 : 359|8@0+ (1,0) [0|255] ""  WCBS
 SG_ WCBS_DiagReqData45 : 367|8@0+ (1,0) [0|255] ""  WCBS
 SG_ WCBS_DiagReqData46 : 375|8@0+ (1,0) [0|255] ""  WCBS
 SG_ WCBS_DiagReqData47 : 383|8@0+ (1,0) [0|255] ""  WCBS
 SG_ WCBS_DiagReqData48 : 391|8@0+ (1,0) [0|255] ""  WCBS
 SG_ WCBS_DiagReqData49 : 399|8@0+ (1,0) [0|255] ""  WCBS
 SG_ WCBS_DiagReqData50 : 407|8@0+ (1,0) [0|255] ""  WCBS
 SG_ WCBS_DiagReqData51 : 415|8@0+ (1,0) [0|255] ""  WCBS
 SG_ WCBS_DiagReqData52 : 423|8@0+ (1,0) [0|255] ""  WCBS
 SG_ WCBS_DiagReqData53 : 431|8@0+ (1,0) [0|255] ""  WCBS
 SG_ WCBS_DiagReqData54 : 439|8@0+ (1,0) [0|255] ""  WCBS
 SG_ WCBS_DiagReqData55 : 447|8@0+ (1,0) [0|255] ""  WCBS
 SG_ WCBS_DiagReqData56 : 455|8@0+ (1,0) [0|255] ""  WCBS
 SG_ WCBS_DiagReqData57 : 463|8@0+ (1,0) [0|255] ""  WCBS
 SG_ WCBS_DiagReqData58 : 471|8@0+ (1,0) [0|255] ""  WCBS
 SG_ WCBS_DiagReqData59 : 479|8@0+ (1,0) [0|255] ""  WCBS
 SG_ WCBS_DiagReqData60 : 487|8@0+ (1,0) [0|255] ""  WCBS
 SG_ WCBS_DiagReqData61 : 495|8@0+ (1,0) [0|255] ""  WCBS
 SG_ WCBS_DiagReqData62 : 503|8@0+ (1,0) [0|255] ""  WCBS
 SG_ WCBS_DiagReqData63 : 511|8@0+ (1,0) [0|255] ""  WCBS

BO_ 1577 WCBS_DiagResp: 64 WCBS
 SG_ WCBS_DiagRespData0 : 7|8@0+ (1,0) [0|255] ""  CVC_C
 SG_ WCBS_DiagRespData1 : 15|8@0+ (1,0) [0|255] ""  CVC_C
 SG_ WCBS_DiagRespData2 : 23|8@0+ (1,0) [0|255] ""  CVC_C
 SG_ WCBS_DiagRespData3 : 31|8@0+ (1,0) [0|255] ""  CVC_C
 SG_ WCBS_DiagRespData4 : 39|8@0+ (1,0) [0|255] ""  CVC_C
 SG_ WCBS_DiagRespData5 : 47|8@0+ (1,0) [0|255] ""  CVC_C
 SG_ WCBS_DiagRespData6 : 55|8@0+ (1,0) [0|255] ""  CVC_C
 SG_ WCBS_DiagRespData7 : 63|8@0+ (1,0) [0|255] ""  CVC_C
 SG_ WCBS_DiagRespData8 : 71|8@0+ (1,0) [0|255] ""  CVC_C
 SG_ WCBS_DiagRespData9 : 79|8@0+ (1,0) [0|255] ""  CVC_C
 SG_ WCBS_DiagRespData10 : 87|8@0+ (1,0) [0|255] ""  CVC_C
 SG_ WCBS_DiagRespData11 : 95|8@0+ (1,0) [0|255] ""  CVC_C
 SG_ WCBS_DiagRespData12 : 103|8@0+ (1,0) [0|255] ""  CVC_C
 SG_ WCBS_DiagRespData13 : 111|8@0+ (1,0) [0|255] ""  CVC_C
 SG_ WCBS_DiagRespData14 : 119|8@0+ (1,0) [0|255] ""  CVC_C
 SG_ WCBS_DiagRespData15 : 127|8@0+ (1,0) [0|255] ""  CVC_C
 SG_ WCBS_DiagRespData16 : 135|8@0+ (1,0) [0|255] ""  CVC_C
 SG_ WCBS_DiagRespData17 : 143|8@0+ (1,0) [0|255] ""  CVC_C
 SG_ WCBS_DiagRespData18 : 151|8@0+ (1,0) [0|255] ""  CVC_C
 SG_ WCBS_DiagRespData19 : 159|8@0+ (1,0) [0|255] ""  CVC_C
 SG_ WCBS_DiagRespData20 : 167|8@0+ (1,0) [0|255] ""  CVC_C
 SG_ WCBS_DiagRespData21 : 175|8@0+ (1,0) [0|255] ""  CVC_C
 SG_ WCBS_DiagRespData22 : 183|8@0+ (1,0) [0|255] ""  CVC_C
 SG_ WCBS_DiagRespData23 : 191|8@0+ (1,0) [0|255] ""  CVC_C
 SG_ WCBS_DiagRespData24 : 199|8@0+ (1,0) [0|255] ""  CVC_C
 SG_ WCBS_DiagRespData25 : 207|8@0+ (1,0) [0|255] ""  CVC_C
 SG_ WCBS_DiagRespData26 : 215|8@0+ (1,0) [0|255] ""  CVC_C
 SG_ WCBS_DiagRespData27 : 223|8@0+ (1,0) [0|255] ""  CVC_C
 SG_ WCBS_DiagRespData28 : 231|8@0+ (1,0) [0|255] ""  CVC_C
 SG_ WCBS_DiagRespData29 : 239|8@0+ (1,0) [0|255] ""  CVC_C
 SG_ WCBS_DiagRespData30 : 247|8@0+ (1,0) [0|255] ""  CVC_C
 SG_ WCBS_DiagRespData31 : 255|8@0+ (1,0) [0|255] ""  CVC_C
 SG_ WCBS_DiagRespData32 : 263|8@0+ (1,0) [0|255] ""  CVC_C
 SG_ WCBS_DiagRespData33 : 271|8@0+ (1,0) [0|255] ""  CVC_C
 SG_ WCBS_DiagRespData34 : 279|8@0+ (1,0) [0|255] ""  CVC_C
 SG_ WCBS_DiagRespData35 : 287|8@0+ (1,0) [0|255] ""  CVC_C
 SG_ WCBS_DiagRespData36 : 295|8@0+ (1,0) [0|255] ""  CVC_C
 SG_ WCBS_DiagRespData37 : 303|8@0+ (1,0) [0|255] ""  CVC_C
 SG_ WCBS_DiagRespData38 : 311|8@0+ (1,0) [0|255] ""  CVC_C
 SG_ WCBS_DiagRespData39 : 319|8@0+ (1,0) [0|255] ""  CVC_C
 SG_ WCBS_DiagRespData40 : 327|8@0+ (1,0) [0|255] ""  CVC_C
 SG_ WCBS_DiagRespData41 : 335|8@0+ (1,0) [0|255] ""  CVC_C
 SG_ WCBS_DiagRespData42 : 343|8@0+ (1,0) [0|255] ""  CVC_C
 SG_ WCBS_DiagRespData43 : 351|8@0+ (1,0) [0|255] ""  CVC_C
 SG_ WCBS_DiagRespData44 : 359|8@0+ (1,0) [0|255] ""  CVC_C
 SG_ WCBS_DiagRespData45 : 367|8@0+ (1,0) [0|255] ""  CVC_C
 SG_ WCBS_DiagRespData46 : 375|8@0+ (1,0) [0|255] ""  CVC_C
 SG_ WCBS_DiagRespData47 : 383|8@0+ (1,0) [0|255] ""  CVC_C
 SG_ WCBS_DiagRespData48 : 391|8@0+ (1,0) [0|255] ""  CVC_C
 SG_ WCBS_DiagRespData49 : 399|8@0+ (1,0) [0|255] ""  CVC_C
 SG_ WCBS_DiagRespData50 : 407|8@0+ (1,0) [0|255] ""  CVC_C
 SG_ WCBS_DiagRespData51 : 415|8@0+ (1,0) [0|255] ""  CVC_C
 SG_ WCBS_DiagRespData52 : 423|8@0+ (1,0) [0|255] ""  CVC_C
 SG_ WCBS_DiagRespData53 : 431|8@0+ (1,0) [0|255] ""  CVC_C
 SG_ WCBS_DiagRespData54 : 439|8@0+ (1,0) [0|255] ""  CVC_C
 SG_ WCBS_DiagRespData55 : 447|8@0+ (1,0) [0|255] ""  CVC_C
 SG_ WCBS_DiagRespData56 : 455|8@0+ (1,0) [0|255] ""  CVC_C
 SG_ WCBS_DiagRespData57 : 463|8@0+ (1,0) [0|255] ""  CVC_C
 SG_ WCBS_DiagRespData58 : 471|8@0+ (1,0) [0|255] ""  CVC_C
 SG_ WCBS_DiagRespData59 : 479|8@0+ (1,0) [0|255] ""  CVC_C
 SG_ WCBS_DiagRespData60 : 487|8@0+ (1,0) [0|255] ""  CVC_C
 SG_ WCBS_DiagRespData61 : 495|8@0+ (1,0) [0|255] ""  CVC_C
 SG_ WCBS_DiagRespData62 : 503|8@0+ (1,0) [0|255] ""  CVC_C
 SG_ WCBS_DiagRespData63 : 511|8@0+ (1,0) [0|255] ""  CVC_C

BO_ 1686 FCAM_DiagReq: 64 CVC_C
 SG_ FCAM_DiagReqData0 : 7|8@0+ (1,0) [0|255] ""  FCAM_C
 SG_ FCAM_DiagReqData1 : 15|8@0+ (1,0) [0|255] ""  FCAM_C
 SG_ FCAM_DiagReqData2 : 23|8@0+ (1,0) [0|255] ""  FCAM_C
 SG_ FCAM_DiagReqData3 : 31|8@0+ (1,0) [0|255] ""  FCAM_C
 SG_ FCAM_DiagReqData4 : 39|8@0+ (1,0) [0|255] ""  FCAM_C
 SG_ FCAM_DiagReqData5 : 47|8@0+ (1,0) [0|255] ""  FCAM_C
 SG_ FCAM_DiagReqData6 : 55|8@0+ (1,0) [0|255] ""  FCAM_C
 SG_ FCAM_DiagReqData7 : 63|8@0+ (1,0) [0|255] ""  FCAM_C
 SG_ FCAM_DiagReqData8 : 71|8@0+ (1,0) [0|255] ""  FCAM_C
 SG_ FCAM_DiagReqData9 : 79|8@0+ (1,0) [0|255] ""  FCAM_C
 SG_ FCAM_DiagReqData10 : 87|8@0+ (1,0) [0|255] ""  FCAM_C
 SG_ FCAM_DiagReqData11 : 95|8@0+ (1,0) [0|255] ""  FCAM_C
 SG_ FCAM_DiagReqData12 : 103|8@0+ (1,0) [0|255] ""  FCAM_C
 SG_ FCAM_DiagReqData13 : 111|8@0+ (1,0) [0|255] ""  FCAM_C
 SG_ FCAM_DiagReqData14 : 119|8@0+ (1,0) [0|255] ""  FCAM_C
 SG_ FCAM_DiagReqData15 : 127|8@0+ (1,0) [0|255] ""  FCAM_C
 SG_ FCAM_DiagReqData16 : 135|8@0+ (1,0) [0|255] ""  FCAM_C
 SG_ FCAM_DiagReqData17 : 143|8@0+ (1,0) [0|255] ""  FCAM_C
 SG_ FCAM_DiagReqData18 : 151|8@0+ (1,0) [0|255] ""  FCAM_C
 SG_ FCAM_DiagReqData19 : 159|8@0+ (1,0) [0|255] ""  FCAM_C
 SG_ FCAM_DiagReqData20 : 167|8@0+ (1,0) [0|255] ""  FCAM_C
 SG_ FCAM_DiagReqData21 : 175|8@0+ (1,0) [0|255] ""  FCAM_C
 SG_ FCAM_DiagReqData22 : 183|8@0+ (1,0) [0|255] ""  FCAM_C
 SG_ FCAM_DiagReqData23 : 191|8@0+ (1,0) [0|255] ""  FCAM_C
 SG_ FCAM_DiagReqData24 : 199|8@0+ (1,0) [0|255] ""  FCAM_C
 SG_ FCAM_DiagReqData25 : 207|8@0+ (1,0) [0|255] ""  FCAM_C
 SG_ FCAM_DiagReqData26 : 215|8@0+ (1,0) [0|255] ""  FCAM_C
 SG_ FCAM_DiagReqData27 : 223|8@0+ (1,0) [0|255] ""  FCAM_C
 SG_ FCAM_DiagReqData28 : 231|8@0+ (1,0) [0|255] ""  FCAM_C
 SG_ FCAM_DiagReqData29 : 239|8@0+ (1,0) [0|255] ""  FCAM_C
 SG_ FCAM_DiagReqData30 : 247|8@0+ (1,0) [0|255] ""  FCAM_C
 SG_ FCAM_DiagReqData31 : 255|8@0+ (1,0) [0|255] ""  FCAM_C
 SG_ FCAM_DiagReqData32 : 263|8@0+ (1,0) [0|255] ""  FCAM_C
 SG_ FCAM_DiagReqData33 : 271|8@0+ (1,0) [0|255] ""  FCAM_C
 SG_ FCAM_DiagReqData34 : 279|8@0+ (1,0) [0|255] ""  FCAM_C
 SG_ FCAM_DiagReqData35 : 287|8@0+ (1,0) [0|255] ""  FCAM_C
 SG_ FCAM_DiagReqData36 : 295|8@0+ (1,0) [0|255] ""  FCAM_C
 SG_ FCAM_DiagReqData37 : 303|8@0+ (1,0) [0|255] ""  FCAM_C
 SG_ FCAM_DiagReqData38 : 311|8@0+ (1,0) [0|255] ""  FCAM_C
 SG_ FCAM_DiagReqData39 : 319|8@0+ (1,0) [0|255] ""  FCAM_C
 SG_ FCAM_DiagReqData40 : 327|8@0+ (1,0) [0|255] ""  FCAM_C
 SG_ FCAM_DiagReqData41 : 335|8@0+ (1,0) [0|255] ""  FCAM_C
 SG_ FCAM_DiagReqData42 : 343|8@0+ (1,0) [0|255] ""  FCAM_C
 SG_ FCAM_DiagReqData43 : 351|8@0+ (1,0) [0|255] ""  FCAM_C
 SG_ FCAM_DiagReqData44 : 359|8@0+ (1,0) [0|255] ""  FCAM_C
 SG_ FCAM_DiagReqData45 : 367|8@0+ (1,0) [0|255] ""  FCAM_C
 SG_ FCAM_DiagReqData46 : 375|8@0+ (1,0) [0|255] ""  FCAM_C
 SG_ FCAM_DiagReqData47 : 383|8@0+ (1,0) [0|255] ""  FCAM_C
 SG_ FCAM_DiagReqData48 : 391|8@0+ (1,0) [0|255] ""  FCAM_C
 SG_ FCAM_DiagReqData49 : 399|8@0+ (1,0) [0|255] ""  FCAM_C
 SG_ FCAM_DiagReqData50 : 407|8@0+ (1,0) [0|255] ""  FCAM_C
 SG_ FCAM_DiagReqData51 : 415|8@0+ (1,0) [0|255] ""  FCAM_C
 SG_ FCAM_DiagReqData52 : 423|8@0+ (1,0) [0|255] ""  FCAM_C
 SG_ FCAM_DiagReqData53 : 431|8@0+ (1,0) [0|255] ""  FCAM_C
 SG_ FCAM_DiagReqData54 : 439|8@0+ (1,0) [0|255] ""  FCAM_C
 SG_ FCAM_DiagReqData55 : 447|8@0+ (1,0) [0|255] ""  FCAM_C
 SG_ FCAM_DiagReqData56 : 455|8@0+ (1,0) [0|255] ""  FCAM_C
 SG_ FCAM_DiagReqData57 : 463|8@0+ (1,0) [0|255] ""  FCAM_C
 SG_ FCAM_DiagReqData58 : 471|8@0+ (1,0) [0|255] ""  FCAM_C
 SG_ FCAM_DiagReqData59 : 479|8@0+ (1,0) [0|255] ""  FCAM_C
 SG_ FCAM_DiagReqData60 : 487|8@0+ (1,0) [0|255] ""  FCAM_C
 SG_ FCAM_DiagReqData61 : 495|8@0+ (1,0) [0|255] ""  FCAM_C
 SG_ FCAM_DiagReqData62 : 503|8@0+ (1,0) [0|255] ""  FCAM_C
 SG_ FCAM_DiagReqData63 : 511|8@0+ (1,0) [0|255] ""  FCAM_C

BO_ 1558 FCAM_DiagResp: 64 FCAM_C
 SG_ FCAM_DiagRespData0 : 7|8@0+ (1,0) [0|255] ""  CVC_C
 SG_ FCAM_DiagRespData1 : 15|8@0+ (1,0) [0|255] ""  CVC_C
 SG_ FCAM_DiagRespData2 : 23|8@0+ (1,0) [0|255] ""  CVC_C
 SG_ FCAM_DiagRespData3 : 31|8@0+ (1,0) [0|255] ""  CVC_C
 SG_ FCAM_DiagRespData4 : 39|8@0+ (1,0) [0|255] ""  CVC_C
 SG_ FCAM_DiagRespData5 : 47|8@0+ (1,0) [0|255] ""  CVC_C
 SG_ FCAM_DiagRespData6 : 55|8@0+ (1,0) [0|255] ""  CVC_C
 SG_ FCAM_DiagRespData7 : 63|8@0+ (1,0) [0|255] ""  CVC_C
 SG_ FCAM_DiagRespData8 : 71|8@0+ (1,0) [0|255] ""  CVC_C
 SG_ FCAM_DiagRespData9 : 79|8@0+ (1,0) [0|255] ""  CVC_C
 SG_ FCAM_DiagRespData10 : 87|8@0+ (1,0) [0|255] ""  CVC_C
 SG_ FCAM_DiagRespData11 : 95|8@0+ (1,0) [0|255] ""  CVC_C
 SG_ FCAM_DiagRespData12 : 103|8@0+ (1,0) [0|255] ""  CVC_C
 SG_ FCAM_DiagRespData13 : 111|8@0+ (1,0) [0|255] ""  CVC_C
 SG_ FCAM_DiagRespData14 : 119|8@0+ (1,0) [0|255] ""  CVC_C
 SG_ FCAM_DiagRespData15 : 127|8@0+ (1,0) [0|255] ""  CVC_C
 SG_ FCAM_DiagRespData16 : 135|8@0+ (1,0) [0|255] ""  CVC_C
 SG_ FCAM_DiagRespData17 : 143|8@0+ (1,0) [0|255] ""  CVC_C
 SG_ FCAM_DiagRespData18 : 151|8@0+ (1,0) [0|255] ""  CVC_C
 SG_ FCAM_DiagRespData19 : 159|8@0+ (1,0) [0|255] ""  CVC_C
 SG_ FCAM_DiagRespData20 : 167|8@0+ (1,0) [0|255] ""  CVC_C
 SG_ FCAM_DiagRespData21 : 175|8@0+ (1,0) [0|255] ""  CVC_C
 SG_ FCAM_DiagRespData22 : 183|8@0+ (1,0) [0|255] ""  CVC_C
 SG_ FCAM_DiagRespData23 : 191|8@0+ (1,0) [0|255] ""  CVC_C
 SG_ FCAM_DiagRespData24 : 199|8@0+ (1,0) [0|255] ""  CVC_C
 SG_ FCAM_DiagRespData25 : 207|8@0+ (1,0) [0|255] ""  CVC_C
 SG_ FCAM_DiagRespData26 : 215|8@0+ (1,0) [0|255] ""  CVC_C
 SG_ FCAM_DiagRespData27 : 223|8@0+ (1,0) [0|255] ""  CVC_C
 SG_ FCAM_DiagRespData28 : 231|8@0+ (1,0) [0|255] ""  CVC_C
 SG_ FCAM_DiagRespData29 : 239|8@0+ (1,0) [0|255] ""  CVC_C
 SG_ FCAM_DiagRespData30 : 247|8@0+ (1,0) [0|255] ""  CVC_C
 SG_ FCAM_DiagRespData31 : 255|8@0+ (1,0) [0|255] ""  CVC_C
 SG_ FCAM_DiagRespData32 : 263|8@0+ (1,0) [0|255] ""  CVC_C
 SG_ FCAM_DiagRespData33 : 271|8@0+ (1,0) [0|255] ""  CVC_C
 SG_ FCAM_DiagRespData34 : 279|8@0+ (1,0) [0|255] ""  CVC_C
 SG_ FCAM_DiagRespData35 : 287|8@0+ (1,0) [0|255] ""  CVC_C
 SG_ FCAM_DiagRespData36 : 295|8@0+ (1,0) [0|255] ""  CVC_C
 SG_ FCAM_DiagRespData37 : 303|8@0+ (1,0) [0|255] ""  CVC_C
 SG_ FCAM_DiagRespData38 : 311|8@0+ (1,0) [0|255] ""  CVC_C
 SG_ FCAM_DiagRespData39 : 319|8@0+ (1,0) [0|255] ""  CVC_C
 SG_ FCAM_DiagRespData40 : 327|8@0+ (1,0) [0|255] ""  CVC_C
 SG_ FCAM_DiagRespData41 : 335|8@0+ (1,0) [0|255] ""  CVC_C
 SG_ FCAM_DiagRespData42 : 343|8@0+ (1,0) [0|255] ""  CVC_C
 SG_ FCAM_DiagRespData43 : 351|8@0+ (1,0) [0|255] ""  CVC_C
 SG_ FCAM_DiagRespData44 : 359|8@0+ (1,0) [0|255] ""  CVC_C
 SG_ FCAM_DiagRespData45 : 367|8@0+ (1,0) [0|255] ""  CVC_C
 SG_ FCAM_DiagRespData46 : 375|8@0+ (1,0) [0|255] ""  CVC_C
 SG_ FCAM_DiagRespData47 : 383|8@0+ (1,0) [0|255] ""  CVC_C
 SG_ FCAM_DiagRespData48 : 391|8@0+ (1,0) [0|255] ""  CVC_C
 SG_ FCAM_DiagRespData49 : 399|8@0+ (1,0) [0|255] ""  CVC_C
 SG_ FCAM_DiagRespData50 : 407|8@0+ (1,0) [0|255] ""  CVC_C
 SG_ FCAM_DiagRespData51 : 415|8@0+ (1,0) [0|255] ""  CVC_C
 SG_ FCAM_DiagRespData52 : 423|8@0+ (1,0) [0|255] ""  CVC_C
 SG_ FCAM_DiagRespData53 : 431|8@0+ (1,0) [0|255] ""  CVC_C
 SG_ FCAM_DiagRespData54 : 439|8@0+ (1,0) [0|255] ""  CVC_C
 SG_ FCAM_DiagRespData55 : 447|8@0+ (1,0) [0|255] ""  CVC_C
 SG_ FCAM_DiagRespData56 : 455|8@0+ (1,0) [0|255] ""  CVC_C
 SG_ FCAM_DiagRespData57 : 463|8@0+ (1,0) [0|255] ""  CVC_C
 SG_ FCAM_DiagRespData58 : 471|8@0+ (1,0) [0|255] ""  CVC_C
 SG_ FCAM_DiagRespData59 : 479|8@0+ (1,0) [0|255] ""  CVC_C
 SG_ FCAM_DiagRespData60 : 487|8@0+ (1,0) [0|255] ""  CVC_C
 SG_ FCAM_DiagRespData61 : 495|8@0+ (1,0) [0|255] ""  CVC_C
 SG_ FCAM_DiagRespData62 : 503|8@0+ (1,0) [0|255] ""  CVC_C
 SG_ FCAM_DiagRespData63 : 511|8@0+ (1,0) [0|255] ""  CVC_C

BO_ 1728 ADCU_DiagReq: 64 CVC_C
 SG_ ADCU_DiagReqData0 : 7|8@0+ (1,0) [0|255] ""  ADCU_C
 SG_ ADCU_DiagReqData1 : 15|8@0+ (1,0) [0|255] ""  ADCU_C
 SG_ ADCU_DiagReqData2 : 23|8@0+ (1,0) [0|255] ""  ADCU_C
 SG_ ADCU_DiagReqData3 : 31|8@0+ (1,0) [0|255] ""  ADCU_C
 SG_ ADCU_DiagReqData4 : 39|8@0+ (1,0) [0|255] ""  ADCU_C
 SG_ ADCU_DiagReqData5 : 47|8@0+ (1,0) [0|255] ""  ADCU_C
 SG_ ADCU_DiagReqData6 : 55|8@0+ (1,0) [0|255] ""  ADCU_C
 SG_ ADCU_DiagReqData7 : 63|8@0+ (1,0) [0|255] ""  ADCU_C
 SG_ ADCU_DiagReqData8 : 71|8@0+ (1,0) [0|255] ""  ADCU_C
 SG_ ADCU_DiagReqData9 : 79|8@0+ (1,0) [0|255] ""  ADCU_C
 SG_ ADCU_DiagReqData10 : 87|8@0+ (1,0) [0|255] ""  ADCU_C
 SG_ ADCU_DiagReqData11 : 95|8@0+ (1,0) [0|255] ""  ADCU_C
 SG_ ADCU_DiagReqData12 : 103|8@0+ (1,0) [0|255] ""  ADCU_C
 SG_ ADCU_DiagReqData13 : 111|8@0+ (1,0) [0|255] ""  ADCU_C
 SG_ ADCU_DiagReqData14 : 119|8@0+ (1,0) [0|255] ""  ADCU_C
 SG_ ADCU_DiagReqData15 : 127|8@0+ (1,0) [0|255] ""  ADCU_C
 SG_ ADCU_DiagReqData16 : 135|8@0+ (1,0) [0|255] ""  ADCU_C
 SG_ ADCU_DiagReqData17 : 143|8@0+ (1,0) [0|255] ""  ADCU_C
 SG_ ADCU_DiagReqData18 : 151|8@0+ (1,0) [0|255] ""  ADCU_C
 SG_ ADCU_DiagReqData19 : 159|8@0+ (1,0) [0|255] ""  ADCU_C
 SG_ ADCU_DiagReqData20 : 167|8@0+ (1,0) [0|255] ""  ADCU_C
 SG_ ADCU_DiagReqData21 : 175|8@0+ (1,0) [0|255] ""  ADCU_C
 SG_ ADCU_DiagReqData22 : 183|8@0+ (1,0) [0|255] ""  ADCU_C
 SG_ ADCU_DiagReqData23 : 191|8@0+ (1,0) [0|255] ""  ADCU_C
 SG_ ADCU_DiagReqData24 : 199|8@0+ (1,0) [0|255] ""  ADCU_C
 SG_ ADCU_DiagReqData25 : 207|8@0+ (1,0) [0|255] ""  ADCU_C
 SG_ ADCU_DiagReqData26 : 215|8@0+ (1,0) [0|255] ""  ADCU_C
 SG_ ADCU_DiagReqData27 : 223|8@0+ (1,0) [0|255] ""  ADCU_C
 SG_ ADCU_DiagReqData28 : 231|8@0+ (1,0) [0|255] ""  ADCU_C
 SG_ ADCU_DiagReqData29 : 239|8@0+ (1,0) [0|255] ""  ADCU_C
 SG_ ADCU_DiagReqData30 : 247|8@0+ (1,0) [0|255] ""  ADCU_C
 SG_ ADCU_DiagReqData31 : 255|8@0+ (1,0) [0|255] ""  ADCU_C
 SG_ ADCU_DiagReqData32 : 263|8@0+ (1,0) [0|255] ""  ADCU_C
 SG_ ADCU_DiagReqData33 : 271|8@0+ (1,0) [0|255] ""  ADCU_C
 SG_ ADCU_DiagReqData34 : 279|8@0+ (1,0) [0|255] ""  ADCU_C
 SG_ ADCU_DiagReqData35 : 287|8@0+ (1,0) [0|255] ""  ADCU_C
 SG_ ADCU_DiagReqData36 : 295|8@0+ (1,0) [0|255] ""  ADCU_C
 SG_ ADCU_DiagReqData37 : 303|8@0+ (1,0) [0|255] ""  ADCU_C
 SG_ ADCU_DiagReqData38 : 311|8@0+ (1,0) [0|255] ""  ADCU_C
 SG_ ADCU_DiagReqData39 : 319|8@0+ (1,0) [0|255] ""  ADCU_C
 SG_ ADCU_DiagReqData40 : 327|8@0+ (1,0) [0|255] ""  ADCU_C
 SG_ ADCU_DiagReqData41 : 335|8@0+ (1,0) [0|255] ""  ADCU_C
 SG_ ADCU_DiagReqData42 : 343|8@0+ (1,0) [0|255] ""  ADCU_C
 SG_ ADCU_DiagReqData43 : 351|8@0+ (1,0) [0|255] ""  ADCU_C
 SG_ ADCU_DiagReqData44 : 359|8@0+ (1,0) [0|255] ""  ADCU_C
 SG_ ADCU_DiagReqData45 : 367|8@0+ (1,0) [0|255] ""  ADCU_C
 SG_ ADCU_DiagReqData46 : 375|8@0+ (1,0) [0|255] ""  ADCU_C
 SG_ ADCU_DiagReqData47 : 383|8@0+ (1,0) [0|255] ""  ADCU_C
 SG_ ADCU_DiagReqData48 : 391|8@0+ (1,0) [0|255] ""  ADCU_C
 SG_ ADCU_DiagReqData49 : 399|8@0+ (1,0) [0|255] ""  ADCU_C
 SG_ ADCU_DiagReqData50 : 407|8@0+ (1,0) [0|255] ""  ADCU_C
 SG_ ADCU_DiagReqData51 : 415|8@0+ (1,0) [0|255] ""  ADCU_C
 SG_ ADCU_DiagReqData52 : 423|8@0+ (1,0) [0|255] ""  ADCU_C
 SG_ ADCU_DiagReqData53 : 431|8@0+ (1,0) [0|255] ""  ADCU_C
 SG_ ADCU_DiagReqData54 : 439|8@0+ (1,0) [0|255] ""  ADCU_C
 SG_ ADCU_DiagReqData55 : 447|8@0+ (1,0) [0|255] ""  ADCU_C
 SG_ ADCU_DiagReqData56 : 455|8@0+ (1,0) [0|255] ""  ADCU_C
 SG_ ADCU_DiagReqData57 : 463|8@0+ (1,0) [0|255] ""  ADCU_C
 SG_ ADCU_DiagReqData58 : 471|8@0+ (1,0) [0|255] ""  ADCU_C
 SG_ ADCU_DiagReqData59 : 479|8@0+ (1,0) [0|255] ""  ADCU_C
 SG_ ADCU_DiagReqData60 : 487|8@0+ (1,0) [0|255] ""  ADCU_C
 SG_ ADCU_DiagReqData61 : 495|8@0+ (1,0) [0|255] ""  ADCU_C
 SG_ ADCU_DiagReqData62 : 503|8@0+ (1,0) [0|255] ""  ADCU_C
 SG_ ADCU_DiagReqData63 : 511|8@0+ (1,0) [0|255] ""  ADCU_C

BO_ 1600 ADCU_DiagResp: 64 ADCU_C
 SG_ ADCU_DiagRespData0 : 7|8@0+ (1,0) [0|255] ""  CVC_C
 SG_ ADCU_DiagRespData1 : 15|8@0+ (1,0) [0|255] ""  CVC_C
 SG_ ADCU_DiagRespData2 : 23|8@0+ (1,0) [0|255] ""  CVC_C
 SG_ ADCU_DiagRespData3 : 31|8@0+ (1,0) [0|255] ""  CVC_C
 SG_ ADCU_DiagRespData4 : 39|8@0+ (1,0) [0|255] ""  CVC_C
 SG_ ADCU_DiagRespData5 : 47|8@0+ (1,0) [0|255] ""  CVC_C
 SG_ ADCU_DiagRespData6 : 55|8@0+ (1,0) [0|255] ""  CVC_C
 SG_ ADCU_DiagRespData7 : 63|8@0+ (1,0) [0|255] ""  CVC_C
 SG_ ADCU_DiagRespData8 : 71|8@0+ (1,0) [0|255] ""  CVC_C
 SG_ ADCU_DiagRespData9 : 79|8@0+ (1,0) [0|255] ""  CVC_C
 SG_ ADCU_DiagRespData10 : 87|8@0+ (1,0) [0|255] ""  CVC_C
 SG_ ADCU_DiagRespData11 : 95|8@0+ (1,0) [0|255] ""  CVC_C
 SG_ ADCU_DiagRespData12 : 103|8@0+ (1,0) [0|255] ""  CVC_C
 SG_ ADCU_DiagRespData13 : 111|8@0+ (1,0) [0|255] ""  CVC_C
 SG_ ADCU_DiagRespData14 : 119|8@0+ (1,0) [0|255] ""  CVC_C
 SG_ ADCU_DiagRespData15 : 127|8@0+ (1,0) [0|255] ""  CVC_C
 SG_ ADCU_DiagRespData16 : 135|8@0+ (1,0) [0|255] ""  CVC_C
 SG_ ADCU_DiagRespData17 : 143|8@0+ (1,0) [0|255] ""  CVC_C
 SG_ ADCU_DiagRespData18 : 151|8@0+ (1,0) [0|255] ""  CVC_C
 SG_ ADCU_DiagRespData19 : 159|8@0+ (1,0) [0|255] ""  CVC_C
 SG_ ADCU_DiagRespData20 : 167|8@0+ (1,0) [0|255] ""  CVC_C
 SG_ ADCU_DiagRespData21 : 175|8@0+ (1,0) [0|255] ""  CVC_C
 SG_ ADCU_DiagRespData22 : 183|8@0+ (1,0) [0|255] ""  CVC_C
 SG_ ADCU_DiagRespData23 : 191|8@0+ (1,0) [0|255] ""  CVC_C
 SG_ ADCU_DiagRespData24 : 199|8@0+ (1,0) [0|255] ""  CVC_C
 SG_ ADCU_DiagRespData25 : 207|8@0+ (1,0) [0|255] ""  CVC_C
 SG_ ADCU_DiagRespData26 : 215|8@0+ (1,0) [0|255] ""  CVC_C
 SG_ ADCU_DiagRespData27 : 223|8@0+ (1,0) [0|255] ""  CVC_C
 SG_ ADCU_DiagRespData28 : 231|8@0+ (1,0) [0|255] ""  CVC_C
 SG_ ADCU_DiagRespData29 : 239|8@0+ (1,0) [0|255] ""  CVC_C
 SG_ ADCU_DiagRespData30 : 247|8@0+ (1,0) [0|255] ""  CVC_C
 SG_ ADCU_DiagRespData31 : 255|8@0+ (1,0) [0|255] ""  CVC_C
 SG_ ADCU_DiagRespData32 : 263|8@0+ (1,0) [0|255] ""  CVC_C
 SG_ ADCU_DiagRespData33 : 271|8@0+ (1,0) [0|255] ""  CVC_C
 SG_ ADCU_DiagRespData34 : 279|8@0+ (1,0) [0|255] ""  CVC_C
 SG_ ADCU_DiagRespData35 : 287|8@0+ (1,0) [0|255] ""  CVC_C
 SG_ ADCU_DiagRespData36 : 295|8@0+ (1,0) [0|255] ""  CVC_C
 SG_ ADCU_DiagRespData37 : 303|8@0+ (1,0) [0|255] ""  CVC_C
 SG_ ADCU_DiagRespData38 : 311|8@0+ (1,0) [0|255] ""  CVC_C
 SG_ ADCU_DiagRespData39 : 319|8@0+ (1,0) [0|255] ""  CVC_C
 SG_ ADCU_DiagRespData40 : 327|8@0+ (1,0) [0|255] ""  CVC_C
 SG_ ADCU_DiagRespData41 : 335|8@0+ (1,0) [0|255] ""  CVC_C
 SG_ ADCU_DiagRespData42 : 343|8@0+ (1,0) [0|255] ""  CVC_C
 SG_ ADCU_DiagRespData43 : 351|8@0+ (1,0) [0|255] ""  CVC_C
 SG_ ADCU_DiagRespData44 : 359|8@0+ (1,0) [0|255] ""  CVC_C
 SG_ ADCU_DiagRespData45 : 367|8@0+ (1,0) [0|255] ""  CVC_C
 SG_ ADCU_DiagRespData46 : 375|8@0+ (1,0) [0|255] ""  CVC_C
 SG_ ADCU_DiagRespData47 : 383|8@0+ (1,0) [0|255] ""  CVC_C
 SG_ ADCU_DiagRespData48 : 391|8@0+ (1,0) [0|255] ""  CVC_C
 SG_ ADCU_DiagRespData49 : 399|8@0+ (1,0) [0|255] ""  CVC_C
 SG_ ADCU_DiagRespData50 : 407|8@0+ (1,0) [0|255] ""  CVC_C
 SG_ ADCU_DiagRespData51 : 415|8@0+ (1,0) [0|255] ""  CVC_C
 SG_ ADCU_DiagRespData52 : 423|8@0+ (1,0) [0|255] ""  CVC_C
 SG_ ADCU_DiagRespData53 : 431|8@0+ (1,0) [0|255] ""  CVC_C
 SG_ ADCU_DiagRespData54 : 439|8@0+ (1,0) [0|255] ""  CVC_C
 SG_ ADCU_DiagRespData55 : 447|8@0+ (1,0) [0|255] ""  CVC_C
 SG_ ADCU_DiagRespData56 : 455|8@0+ (1,0) [0|255] ""  CVC_C
 SG_ ADCU_DiagRespData57 : 463|8@0+ (1,0) [0|255] ""  CVC_C
 SG_ ADCU_DiagRespData58 : 471|8@0+ (1,0) [0|255] ""  CVC_C
 SG_ ADCU_DiagRespData59 : 479|8@0+ (1,0) [0|255] ""  CVC_C
 SG_ ADCU_DiagRespData60 : 487|8@0+ (1,0) [0|255] ""  CVC_C
 SG_ ADCU_DiagRespData61 : 495|8@0+ (1,0) [0|255] ""  CVC_C
 SG_ ADCU_DiagRespData62 : 503|8@0+ (1,0) [0|255] ""  CVC_C
 SG_ ADCU_DiagRespData63 : 511|8@0+ (1,0) [0|255] ""  CVC_C

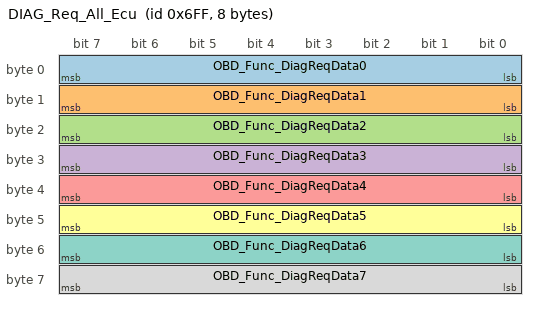
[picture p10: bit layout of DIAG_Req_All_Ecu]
BO_ 1791 DIAG_Req_All_Ecu: 8 CVC_C
 SG_ OBD_Func_DiagReqData0 : 7|8@0+ (1,0) [0|255] ""  EPS,WCBS,FCAM_C,ADCU_C
 SG_ OBD_Func_DiagReqData1 : 15|8@0+ (1,0) [0|255] ""  EPS,WCBS,FCAM_C,ADCU_C
 SG_ OBD_Func_DiagReqData2 : 23|8@0+ (1,0) [0|255] ""  EPS,WCBS,FCAM_C,ADCU_C
 SG_ OBD_Func_DiagReqData3 : 31|8@0+ (1,0) [0|255] ""  EPS,WCBS,FCAM_C,ADCU_C
 SG_ OBD_Func_DiagReqData4 : 39|8@0+ (1,0) [0|255] ""  EPS,WCBS,FCAM_C,ADCU_C
 SG_ OBD_Func_DiagReqData5 : 47|8@0+ (1,0) [0|255] ""  EPS,WCBS,FCAM_C,ADCU_C
 SG_ OBD_Func_DiagReqData6 : 55|8@0+ (1,0) [0|255] ""  EPS,WCBS,FCAM_C,ADCU_C
 SG_ OBD_Func_DiagReqData7 : 63|8@0+ (1,0) [0|255] ""  EPS,WCBS,FCAM_C,ADCU_C

BO_ 1872 WCBS_Calibration_Req_M: 64 DUMMY_ECU
 SG_ WCBS_Calibration_Req_M0 : 7|8@0+ (1,0) [0|255] ""  WCBS
 SG_ WCBS_Calibration_Req_M1 : 15|8@0+ (1,0) [0|255] ""  WCBS
 SG_ WCBS_Calibration_Req_M2 : 23|8@0+ (1,0) [0|255] ""  WCBS
 SG_ WCBS_Calibration_Req_M3 : 31|8@0+ (1,0) [0|255] ""  WCBS
 SG_ WCBS_Calibration_Req_M4 : 39|8@0+ (1,0) [0|255] ""  WCBS
 SG_ WCBS_Calibration_Req_M5 : 47|8@0+ (1,0) [0|255] ""  WCBS
 SG_ WCBS_Calibration_Req_M6 : 55|8@0+ (1,0) [0|255] ""  WCBS
 SG_ WCBS_Calibration_Req_M7 : 63|8@0+ (1,0) [0|255] ""  WCBS
 SG_ WCBS_Calibration_Req_M8 : 71|8@0+ (1,0) [0|255] ""  WCBS
 SG_ WCBS_Calibration_Req_M9 : 79|8@0+ (1,0) [0|255] ""  WCBS
 SG_ WCBS_Calibration_Req_M10 : 87|8@0+ (1,0) [0|255] ""  WCBS
 SG_ WCBS_Calibration_Req_M11 : 95|8@0+ (1,0) [0|255] ""  WCBS
 SG_ WCBS_Calibration_Req_M12 : 103|8@0+ (1,0) [0|255] ""  WCBS
 SG_ WCBS_Calibration_Req_M13 : 111|8@0+ (1,0) [0|255] ""  WCBS
 SG_ WCBS_Calibration_Req_M14 : 119|8@0+ (1,0) [0|255] ""  WCBS
 SG_ WCBS_Calibration_Req_M15 : 127|8@0+ (1,0) [0|255] ""  WCBS
 SG_ WCBS_Calibration_Req_M16 : 135|8@0+ (1,0) [0|255] ""  WCBS
 SG_ WCBS_Calibration_Req_M17 : 143|8@0+ (1,0) [0|255] ""  WCBS
 SG_ WCBS_Calibration_Req_M18 : 151|8@0+ (1,0) [0|255] ""  WCBS
 SG_ WCBS_Calibration_Req_M19 : 159|8@0+ (1,0) [0|255] ""  WCBS
 SG_ WCBS_Calibration_Req_M20 : 167|8@0+ (1,0) [0|255] ""  WCBS
 SG_ WCBS_Calibration_Req_M21 : 175|8@0+ (1,0) [0|255] ""  WCBS
 SG_ WCBS_Calibration_Req_M22 : 183|8@0+ (1,0) [0|255] ""  WCBS
 SG_ WCBS_Calibration_Req_M23 : 191|8@0+ (1,0) [0|255] ""  WCBS
 SG_ WCBS_Calibration_Req_M24 : 199|8@0+ (1,0) [0|255] ""  WCBS
 SG_ WCBS_Calibration_Req_M25 : 207|8@0+ (1,0) [0|255] ""  WCBS
 SG_ WCBS_Calibration_Req_M26 : 215|8@0+ (1,0) [0|255] ""  WCBS
 SG_ WCBS_Calibration_Req_M27 : 223|8@0+ (1,0) [0|255] ""  WCBS
 SG_ WCBS_Calibration_Req_M28 : 231|8@0+ (1,0) [0|255] ""  WCBS
 SG_ WCBS_Calibration_Req_M29 : 239|8@0+ (1,0) [0|255] ""  WCBS
 SG_ WCBS_Calibration_Req_M30 : 247|8@0+ (1,0) [0|255] ""  WCBS
 SG_ WCBS_Calibration_Req_M31 : 255|8@0+ (1,0) [0|255] ""  WCBS
 SG_ WCBS_Calibration_Req_M32 : 263|8@0+ (1,0) [0|255] ""  WCBS
 SG_ WCBS_Calibration_Req_M33 : 271|8@0+ (1,0) [0|255] ""  WCBS
 SG_ WCBS_Calibration_Req_M34 : 279|8@0+ (1,0) [0|255] ""  WCBS
 SG_ WCBS_Calibration_Req_M35 : 287|8@0+ (1,0) [0|255] ""  WCBS
 SG_ WCBS_Calibration_Req_M36 : 295|8@0+ (1,0) [0|255] ""  WCBS
 SG_ WCBS_Calibration_Req_M37 : 303|8@0+ (1,0) [0|255] ""  WCBS
 SG_ WCBS_Calibration_Req_M38 : 311|8@0+ (1,0) [0|255] ""  WCBS
 SG_ WCBS_Calibration_Req_M39 : 319|8@0+ (1,0) [0|255] ""  WCBS
 SG_ WCBS_Calibration_Req_M40 : 327|8@0+ (1,0) [0|255] ""  WCBS
 SG_ WCBS_Calibration_Req_M41 : 335|8@0+ (1,0) [0|255] ""  WCBS
 SG_ WCBS_Calibration_Req_M42 : 343|8@0+ (1,0) [0|255] ""  WCBS
 SG_ WCBS_Calibration_Req_M43 : 351|8@0+ (1,0) [0|255] ""  WCBS
 SG_ WCBS_Calibration_Req_M44 : 359|8@0+ (1,0) [0|255] ""  WCBS
 SG_ WCBS_Calibration_Req_M45 : 367|8@0+ (1,0) [0|255] ""  WCBS
 SG_ WCBS_Calibration_Req_M46 : 375|8@0+ (1,0) [0|255] ""  WCBS
 SG_ WCBS_Calibration_Req_M47 : 383|8@0+ (1,0) [0|255] ""  WCBS
 SG_ WCBS_Calibration_Req_M48 : 391|8@0+ (1,0) [0|255] ""  WCBS
 SG_ WCBS_Calibration_Req_M49 : 399|8@0+ (1,0) [0|255] ""  WCBS
 SG_ WCBS_Calibration_Req_M50 : 407|8@0+ (1,0) [0|255] ""  WCBS
 SG_ WCBS_Calibration_Req_M51 : 415|8@0+ (1,0) [0|255] ""  WCBS
 SG_ WCBS_Calibration_Req_M52 : 423|8@0+ (1,0) [0|255] ""  WCBS
 SG_ WCBS_Calibration_Req_M53 : 431|8@0+ (1,0) [0|255] ""  WCBS
 SG_ WCBS_Calibration_Req_M54 : 439|8@0+ (1,0) [0|255] ""  WCBS
 SG_ WCBS_Calibration_Req_M55 : 447|8@0+ (1,0) [0|255] ""  WCBS
 SG_ WCBS_Calibration_Req_M56 : 455|8@0+ (1,0) [0|255] ""  WCBS
 SG_ WCBS_Calibration_Req_M57 : 463|8@0+ (1,0) [0|255] ""  WCBS
 SG_ WCBS_Calibration_Req_M58 : 471|8@0+ (1,0) [0|255] ""  WCBS
 SG_ WCBS_Calibration_Req_M59 : 479|8@0+ (1,0) [0|255] ""  WCBS
 SG_ WCBS_Calibration_Req_M60 : 487|8@0+ (1,0) [0|255] ""  WCBS
 SG_ WCBS_Calibration_Req_M61 : 495|8@0+ (1,0) [0|255] ""  WCBS
 SG_ WCBS_Calibration_Req_M62 : 503|8@0+ (1,0) [0|255] ""  WCBS
 SG_ WCBS_Calibration_Req_M63 : 511|8@0+ (1,0) [0|255] ""  WCBS

BO_ 1888 WCBS_Calibration_Resp_M: 64 WCBS
 SG_ WCBS_Calibration_Resp_M0 : 7|8@0+ (1,0) [0|255] ""  DUMMY_ECU
 SG_ WCBS_Calibration_Resp_M1 : 15|8@0+ (1,0) [0|255] ""  DUMMY_ECU
 SG_ WCBS_Calibration_Resp_M2 : 23|8@0+ (1,0) [0|255] ""  DUMMY_ECU
 SG_ WCBS_Calibration_Resp_M3 : 31|8@0+ (1,0) [0|255] ""  DUMMY_ECU
 SG_ WCBS_Calibration_Resp_M4 : 39|8@0+ (1,0) [0|255] ""  DUMMY_ECU
 SG_ WCBS_Calibration_Resp_M5 : 47|8@0+ (1,0) [0|255] ""  DUMMY_ECU
 SG_ WCBS_Calibration_Resp_M6 : 55|8@0+ (1,0) [0|255] ""  DUMMY_ECU
 SG_ WCBS_Calibration_Resp_M7 : 63|8@0+ (1,0) [0|255] ""  DUMMY_ECU
 SG_ WCBS_Calibration_Resp_M8 : 71|8@0+ (1,0) [0|255] ""  DUMMY_ECU
 SG_ WCBS_Calibration_Resp_M9 : 79|8@0+ (1,0) [0|255] ""  DUMMY_ECU
 SG_ WCBS_Calibration_Resp_M10 : 87|8@0+ (1,0) [0|255] ""  DUMMY_ECU
 SG_ WCBS_Calibration_Resp_M11 : 95|8@0+ (1,0) [0|255] ""  DUMMY_ECU
 SG_ WCBS_Calibration_Resp_M12 : 103|8@0+ (1,0) [0|255] ""  DUMMY_ECU
 SG_ WCBS_Calibration_Resp_M13 : 111|8@0+ (1,0) [0|255] ""  DUMMY_ECU
 SG_ WCBS_Calibration_Resp_M14 : 119|8@0+ (1,0) [0|255] ""  DUMMY_ECU
 SG_ WCBS_Calibration_Resp_M15 : 127|8@0+ (1,0) [0|255] ""  DUMMY_ECU
 SG_ WCBS_Calibration_Resp_M16 : 135|8@0+ (1,0) [0|255] ""  DUMMY_ECU
 SG_ WCBS_Calibration_Resp_M17 : 143|8@0+ (1,0) [0|255] ""  DUMMY_ECU
 SG_ WCBS_Calibration_Resp_M18 : 151|8@0+ (1,0) [0|255] ""  DUMMY_ECU
 SG_ WCBS_Calibration_Resp_M19 : 159|8@0+ (1,0) [0|255] ""  DUMMY_ECU
 SG_ WCBS_Calibration_Resp_M20 : 167|8@0+ (1,0) [0|255] ""  DUMMY_ECU
 SG_ WCBS_Calibration_Resp_M21 : 175|8@0+ (1,0) [0|255] ""  DUMMY_ECU
 SG_ WCBS_Calibration_Resp_M22 : 183|8@0+ (1,0) [0|255] ""  DUMMY_ECU
 SG_ WCBS_Calibration_Resp_M23 : 191|8@0+ (1,0) [0|255] ""  DUMMY_ECU
 SG_ WCBS_Calibration_Resp_M24 : 199|8@0+ (1,0) [0|255] ""  DUMMY_ECU
 SG_ WCBS_Calibration_Resp_M25 : 207|8@0+ (1,0) [0|255] ""  DUMMY_ECU
 SG_ WCBS_Calibration_Resp_M26 : 215|8@0+ (1,0) [0|255] ""  DUMMY_ECU
 SG_ WCBS_Calibration_Resp_M27 : 223|8@0+ (1,0) [0|255] ""  DUMMY_ECU
 SG_ WCBS_Calibration_Resp_M28 : 231|8@0+ (1,0) [0|255] ""  DUMMY_ECU
 SG_ WCBS_Calibration_Resp_M29 : 239|8@0+ (1,0) [0|255] ""  DUMMY_ECU
 SG_ WCBS_Calibration_Resp_M30 : 247|8@0+ (1,0) [0|255] ""  DUMMY_ECU
 SG_ WCBS_Calibration_Resp_M31 : 255|8@0+ (1,0) [0|255] ""  DUMMY_ECU
 SG_ WCBS_Calibration_Resp_M32 : 263|8@0+ (1,0) [0|255] ""  DUMMY_ECU
 SG_ WCBS_Calibration_Resp_M33 : 271|8@0+ (1,0) [0|255] ""  DUMMY_ECU
 SG_ WCBS_Calibration_Resp_M34 : 279|8@0+ (1,0) [0|255] ""  DUMMY_ECU
 SG_ WCBS_Calibration_Resp_M35 : 287|8@0+ (1,0) [0|255] ""  DUMMY_ECU
 SG_ WCBS_Calibration_Resp_M36 : 295|8@0+ (1,0) [0|255] ""  DUMMY_ECU
 SG_ WCBS_Calibration_Resp_M37 : 303|8@0+ (1,0) [0|255] ""  DUMMY_ECU
 SG_ WCBS_Calibration_Resp_M38 : 311|8@0+ (1,0) [0|255] ""  DUMMY_ECU
 SG_ WCBS_Calibration_Resp_M39 : 319|8@0+ (1,0) [0|255] ""  DUMMY_ECU
 SG_ WCBS_Calibration_Resp_M40 : 327|8@0+ (1,0) [0|255] ""  DUMMY_ECU
 SG_ WCBS_Calibration_Resp_M41 : 335|8@0+ (1,0) [0|255] ""  DUMMY_ECU
 SG_ WCBS_Calibration_Resp_M42 : 343|8@0+ (1,0) [0|255] ""  DUMMY_ECU
 SG_ WCBS_Calibration_Resp_M43 : 351|8@0+ (1,0) [0|255] ""  DUMMY_ECU
 SG_ WCBS_Calibration_Resp_M44 : 359|8@0+ (1,0) [0|255] ""  DUMMY_ECU
 SG_ WCBS_Calibration_Resp_M45 : 367|8@0+ (1,0) [0|255] ""  DUMMY_ECU
 SG_ WCBS_Calibration_Resp_M46 : 375|8@0+ (1,0) [0|255] ""  DUMMY_ECU
 SG_ WCBS_Calibration_Resp_M47 : 383|8@0+ (1,0) [0|255] ""  DUMMY_ECU
 SG_ WCBS_Calibration_Resp_M48 : 391|8@0+ (1,0) [0|255] ""  DUMMY_ECU
 SG_ WCBS_Calibration_Resp_M49 : 399|8@0+ (1,0) [0|255] ""  DUMMY_ECU
 SG_ WCBS_Calibration_Resp_M50 : 407|8@0+ (1,0) [0|255] ""  DUMMY_ECU
 SG_ WCBS_Calibration_Resp_M51 : 415|8@0+ (1,0) [0|255] ""  DUMMY_ECU
 SG_ WCBS_Calibration_Resp_M52 : 423|8@0+ (1,0) [0|255] ""  DUMMY_ECU
 SG_ WCBS_Calibration_Resp_M53 : 431|8@0+ (1,0) [0|255] ""  DUMMY_ECU
 SG_ WCBS_Calibration_Resp_M54 : 439|8@0+ (1,0) [0|255] ""  DUMMY_ECU
 SG_ WCBS_Calibration_Resp_M55 : 447|8@0+ (1,0) [0|255] ""  DUMMY_ECU
 SG_ WCBS_Calibration_Resp_M56 : 455|8@0+ (1,0) [0|255] ""  DUMMY_ECU
 SG_ WCBS_Calibration_Resp_M57 : 463|8@0+ (1,0) [0|255] ""  DUMMY_ECU
 SG_ WCBS_Calibration_Resp_M58 : 471|8@0+ (1,0) [0|255] ""  DUMMY_ECU
 SG_ WCBS_Calibration_Resp_M59 : 479|8@0+ (1,0) [0|255] ""  DUMMY_ECU
 SG_ WCBS_Calibration_Resp_M60 : 487|8@0+ (1,0) [0|255] ""  DUMMY_ECU
 SG_ WCBS_Calibration_Resp_M61 : 495|8@0+ (1,0) [0|255] ""  DUMMY_ECU
 SG_ WCBS_Calibration_Resp_M62 : 503|8@0+ (1,0) [0|255] ""  DUMMY_ECU
 SG_ WCBS_Calibration_Resp_M63 : 511|8@0+ (1,0) [0|255] ""  DUMMY_ECU

BO_ 1873 WCBS_Calibration_Req_A: 64 DUMMY_ECU
 SG_ WCBS_Calibration_Req_A0 : 7|8@0+ (1,0) [0|255] ""  WCBS
 SG_ WCBS_Calibration_Req_A1 : 15|8@0+ (1,0) [0|255] ""  WCBS
 SG_ WCBS_Calibration_Req_A2 : 23|8@0+ (1,0) [0|255] ""  WCBS
 SG_ WCBS_Calibration_Req_A3 : 31|8@0+ (1,0) [0|255] ""  WCBS
 SG_ WCBS_Calibration_Req_A4 : 39|8@0+ (1,0) [0|255] ""  WCBS
 SG_ WCBS_Calibration_Req_A5 : 47|8@0+ (1,0) [0|255] ""  WCBS
 SG_ WCBS_Calibration_Req_A6 : 55|8@0+ (1,0) [0|255] ""  WCBS
 SG_ WCBS_Calibration_Req_A7 : 63|8@0+ (1,0) [0|255] ""  WCBS
 SG_ WCBS_Calibration_Req_A8 : 71|8@0+ (1,0) [0|255] ""  WCBS
 SG_ WCBS_Calibration_Req_A9 : 79|8@0+ (1,0) [0|255] ""  WCBS
 SG_ WCBS_Calibration_Req_A10 : 87|8@0+ (1,0) [0|255] ""  WCBS
 SG_ WCBS_Calibration_Req_A11 : 95|8@0+ (1,0) [0|255] ""  WCBS
 SG_ WCBS_Calibration_Req_A12 : 103|8@0+ (1,0) [0|255] ""  WCBS
 SG_ WCBS_Calibration_Req_A13 : 111|8@0+ (1,0) [0|255] ""  WCBS
 SG_ WCBS_Calibration_Req_A14 : 119|8@0+ (1,0) [0|255] ""  WCBS
 SG_ WCBS_Calibration_Req_A15 : 127|8@0+ (1,0) [0|255] ""  WCBS
 SG_ WCBS_Calibration_Req_A16 : 135|8@0+ (1,0) [0|255] ""  WCBS
 SG_ WCBS_Calibration_Req_A17 : 143|8@0+ (1,0) [0|255] ""  WCBS
 SG_ WCBS_Calibration_Req_A18 : 151|8@0+ (1,0) [0|255] ""  WCBS
 SG_ WCBS_Calibration_Req_A19 : 159|8@0+ (1,0) [0|255] ""  WCBS
 SG_ WCBS_Calibration_Req_A20 : 167|8@0+ (1,0) [0|255] ""  WCBS
 SG_ WCBS_Calibration_Req_A21 : 175|8@0+ (1,0) [0|255] ""  WCBS
 SG_ WCBS_Calibration_Req_A22 : 183|8@0+ (1,0) [0|255] ""  WCBS
 SG_ WCBS_Calibration_Req_A23 : 191|8@0+ (1,0) [0|255] ""  WCBS
 SG_ WCBS_Calibration_Req_A24 : 199|8@0+ (1,0) [0|255] ""  WCBS
 SG_ WCBS_Calibration_Req_A25 : 207|8@0+ (1,0) [0|255] ""  WCBS
 SG_ WCBS_Calibration_Req_A26 : 215|8@0+ (1,0) [0|255] ""  WCBS
 SG_ WCBS_Calibration_Req_A27 : 223|8@0+ (1,0) [0|255] ""  WCBS
 SG_ WCBS_Calibration_Req_A28 : 231|8@0+ (1,0) [0|255] ""  WCBS
 SG_ WCBS_Calibration_Req_A29 : 239|8@0+ (1,0) [0|255] ""  WCBS
 SG_ WCBS_Calibration_Req_A30 : 247|8@0+ (1,0) [0|255] ""  WCBS
 SG_ WCBS_Calibration_Req_A31 : 255|8@0+ (1,0) [0|255] ""  WCBS
 SG_ WCBS_Calibration_Req_A32 : 263|8@0+ (1,0) [0|255] ""  WCBS
 SG_ WCBS_Calibration_Req_A33 : 271|8@0+ (1,0) [0|255] ""  WCBS
 SG_ WCBS_Calibration_Req_A34 : 279|8@0+ (1,0) [0|255] ""  WCBS
 SG_ WCBS_Calibration_Req_A35 : 287|8@0+ (1,0) [0|255] ""  WCBS
 SG_ WCBS_Calibration_Req_A36 : 295|8@0+ (1,0) [0|255] ""  WCBS
 SG_ WCBS_Calibration_Req_A37 : 303|8@0+ (1,0) [0|255] ""  WCBS
 SG_ WCBS_Calibration_Req_A38 : 311|8@0+ (1,0) [0|255] ""  WCBS
 SG_ WCBS_Calibration_Req_A39 : 319|8@0+ (1,0) [0|255] ""  WCBS
 SG_ WCBS_Calibration_Req_A40 : 327|8@0+ (1,0) [0|255] ""  WCBS
 SG_ WCBS_Calibration_Req_A41 : 335|8@0+ (1,0) [0|255] ""  WCBS
 SG_ WCBS_Calibration_Req_A42 : 343|8@0+ (1,0) [0|255] ""  WCBS
 SG_ WCBS_Calibration_Req_A43 : 351|8@0+ (1,0) [0|255] ""  WCBS
 SG_ WCBS_Calibration_Req_A44 : 359|8@0+ (1,0) [0|255] ""  WCBS
 SG_ WCBS_Calibration_Req_A45 : 367|8@0+ (1,0) [0|255] ""  WCBS
 SG_ WCBS_Calibration_Req_A46 : 375|8@0+ (1,0) [0|255] ""  WCBS
 SG_ WCBS_Calibration_Req_A47 : 383|8@0+ (1,0) [0|255] ""  WCBS
 SG_ WCBS_Calibration_Req_A48 : 391|8@0+ (1,0) [0|255] ""  WCBS
 SG_ WCBS_Calibration_Req_A49 : 399|8@0+ (1,0) [0|255] ""  WCBS
 SG_ WCBS_Calibration_Req_A50 : 407|8@0+ (1,0) [0|255] ""  WCBS
 SG_ WCBS_Calibration_Req_A51 : 415|8@0+ (1,0) [0|255] ""  WCBS
 SG_ WCBS_Calibration_Req_A52 : 423|8@0+ (1,0) [0|255] ""  WCBS
 SG_ WCBS_Calibration_Req_A53 : 431|8@0+ (1,0) [0|255] ""  WCBS
 SG_ WCBS_Calibration_Req_A54 : 439|8@0+ (1,0) [0|255] ""  WCBS
 SG_ WCBS_Calibration_Req_A55 : 447|8@0+ (1,0) [0|255] ""  WCBS
 SG_ WCBS_Calibration_Req_A56 : 455|8@0+ (1,0) [0|255] ""  WCBS
 SG_ WCBS_Calibration_Req_A57 : 463|8@0+ (1,0) [0|255] ""  WCBS
 SG_ WCBS_Calibration_Req_A58 : 471|8@0+ (1,0) [0|255] ""  WCBS
 SG_ WCBS_Calibration_Req_A59 : 479|8@0+ (1,0) [0|255] ""  WCBS
 SG_ WCBS_Calibration_Req_A60 : 487|8@0+ (1,0) [0|255] ""  WCBS
 SG_ WCBS_Calibration_Req_A61 : 495|8@0+ (1,0) [0|255] ""  WCBS
 SG_ WCBS_Calibration_Req_A62 : 503|8@0+ (1,0) [0|255] ""  WCBS
 SG_ WCBS_Calibration_Req_A63 : 511|8@0+ (1,0) [0|255] ""  WCBS

BO_ 1889 WCBS_Calibration_Resp_A: 64 WCBS
 SG_ WCBS_Calibration_Resp_A0 : 7|8@0+ (1,0) [0|255] ""  DUMMY_ECU
 SG_ WCBS_Calibration_Resp_A1 : 15|8@0+ (1,0) [0|255] ""  DUMMY_ECU
 SG_ WCBS_Calibration_Resp_A2 : 23|8@0+ (1,0) [0|255] ""  DUMMY_ECU
 SG_ WCBS_Calibration_Resp_A3 : 31|8@0+ (1,0) [0|255] ""  DUMMY_ECU
 SG_ WCBS_Calibration_Resp_A4 : 39|8@0+ (1,0) [0|255] ""  DUMMY_ECU
 SG_ WCBS_Calibration_Resp_A5 : 47|8@0+ (1,0) [0|255] ""  DUMMY_ECU
 SG_ WCBS_Calibration_Resp_A6 : 55|8@0+ (1,0) [0|255] ""  DUMMY_ECU
 SG_ WCBS_Calibration_Resp_A7 : 63|8@0+ (1,0) [0|255] ""  DUMMY_ECU
 SG_ WCBS_Calibration_Resp_A8 : 71|8@0+ (1,0) [0|255] ""  DUMMY_ECU
 SG_ WCBS_Calibration_Resp_A9 : 79|8@0+ (1,0) [0|255] ""  DUMMY_ECU
 SG_ WCBS_Calibration_Resp_A10 : 87|8@0+ (1,0) [0|255] ""  DUMMY_ECU
 SG_ WCBS_Calibration_Resp_A11 : 95|8@0+ (1,0) [0|255] ""  DUMMY_ECU
 SG_ WCBS_Calibration_Resp_A12 : 103|8@0+ (1,0) [0|255] ""  DUMMY_ECU
 SG_ WCBS_Calibration_Resp_A13 : 111|8@0+ (1,0) [0|255] ""  DUMMY_ECU
 SG_ WCBS_Calibration_Resp_A14 : 119|8@0+ (1,0) [0|255] ""  DUMMY_ECU
 SG_ WCBS_Calibration_Resp_A15 : 127|8@0+ (1,0) [0|255] ""  DUMMY_ECU
 SG_ WCBS_Calibration_Resp_A16 : 135|8@0+ (1,0) [0|255] ""  DUMMY_ECU
 SG_ WCBS_Calibration_Resp_A17 : 143|8@0+ (1,0) [0|255] ""  DUMMY_ECU
 SG_ WCBS_Calibration_Resp_A18 : 151|8@0+ (1,0) [0|255] ""  DUMMY_ECU
 SG_ WCBS_Calibration_Resp_A19 : 159|8@0+ (1,0) [0|255] ""  DUMMY_ECU
 SG_ WCBS_Calibration_Resp_A20 : 167|8@0+ (1,0) [0|255] ""  DUMMY_ECU
 SG_ WCBS_Calibration_Resp_A21 : 175|8@0+ (1,0) [0|255] ""  DUMMY_ECU
 SG_ WCBS_Calibration_Resp_A22 : 183|8@0+ (1,0) [0|255] ""  DUMMY_ECU
 SG_ WCBS_Calibration_Resp_A23 : 191|8@0+ (1,0) [0|255] ""  DUMMY_ECU
 SG_ WCBS_Calibration_Resp_A24 : 199|8@0+ (1,0) [0|255] ""  DUMMY_ECU
 SG_ WCBS_Calibration_Resp_A25 : 207|8@0+ (1,0) [0|255] ""  DUMMY_ECU
 SG_ WCBS_Calibration_Resp_A26 : 215|8@0+ (1,0) [0|255] ""  DUMMY_ECU
 SG_ WCBS_Calibration_Resp_A27 : 223|8@0+ (1,0) [0|255] ""  DUMMY_ECU
 SG_ WCBS_Calibration_Resp_A28 : 231|8@0+ (1,0) [0|255] ""  DUMMY_ECU
 SG_ WCBS_Calibration_Resp_A29 : 239|8@0+ (1,0) [0|255] ""  DUMMY_ECU
 SG_ WCBS_Calibration_Resp_A30 : 247|8@0+ (1,0) [0|255] ""  DUMMY_ECU
 SG_ WCBS_Calibration_Resp_A31 : 255|8@0+ (1,0) [0|255] ""  DUMMY_ECU
 SG_ WCBS_Calibration_Resp_A32 : 263|8@0+ (1,0) [0|255] ""  DUMMY_ECU
 SG_ WCBS_Calibration_Resp_A33 : 271|8@0+ (1,0) [0|255] ""  DUMMY_ECU
 SG_ WCBS_Calibration_Resp_A34 : 279|8@0+ (1,0) [0|255] ""  DUMMY_ECU
 SG_ WCBS_Calibration_Resp_A35 : 287|8@0+ (1,0) [0|255] ""  DUMMY_ECU
 SG_ WCBS_Calibration_Resp_A36 : 295|8@0+ (1,0) [0|255] ""  DUMMY_ECU
 SG_ WCBS_Calibration_Resp_A37 : 303|8@0+ (1,0) [0|255] ""  DUMMY_ECU
 SG_ WCBS_Calibration_Resp_A38 : 311|8@0+ (1,0) [0|255] ""  DUMMY_ECU
 SG_ WCBS_Calibration_Resp_A39 : 319|8@0+ (1,0) [0|255] ""  DUMMY_ECU
 SG_ WCBS_Calibration_Resp_A40 : 327|8@0+ (1,0) [0|255] ""  DUMMY_ECU
 SG_ WCBS_Calibration_Resp_A41 : 335|8@0+ (1,0) [0|255] ""  DUMMY_ECU
 SG_ WCBS_Calibration_Resp_A42 : 343|8@0+ (1,0) [0|255] ""  DUMMY_ECU
 SG_ WCBS_Calibration_Resp_A43 : 351|8@0+ (1,0) [0|255] ""  DUMMY_ECU
 SG_ WCBS_Calibration_Resp_A44 : 359|8@0+ (1,0) [0|255] ""  DUMMY_ECU
 SG_ WCBS_Calibration_Resp_A45 : 367|8@0+ (1,0) [0|255] ""  DUMMY_ECU
 SG_ WCBS_Calibration_Resp_A46 : 375|8@0+ (1,0) [0|255] ""  DUMMY_ECU
 SG_ WCBS_Calibration_Resp_A47 : 383|8@0+ (1,0) [0|255] ""  DUMMY_ECU
 SG_ WCBS_Calibration_Resp_A48 : 391|8@0+ (1,0) [0|255] ""  DUMMY_ECU
 SG_ WCBS_Calibration_Resp_A49 : 399|8@0+ (1,0) [0|255] ""  DUMMY_ECU
 SG_ WCBS_Calibration_Resp_A50 : 407|8@0+ (1,0) [0|255] ""  DUMMY_ECU
 SG_ WCBS_Calibration_Resp_A51 : 415|8@0+ (1,0) [0|255] ""  DUMMY_ECU
 SG_ WCBS_Calibration_Resp_A52 : 423|8@0+ (1,0) [0|255] ""  DUMMY_ECU
 SG_ WCBS_Calibration_Resp_A53 : 431|8@0+ (1,0) [0|255] ""  DUMMY_ECU
 SG_ WCBS_Calibration_Resp_A54 : 439|8@0+ (1,0) [0|255] ""  DUMMY_ECU
 SG_ WCBS_Calibration_Resp_A55 : 447|8@0+ (1,0) [0|255] ""  DUMMY_ECU
 SG_ WCBS_Calibration_Resp_A56 : 455|8@0+ (1,0) [0|255] ""  DUMMY_ECU
 SG_ WCBS_Calibration_Resp_A57 : 463|8@0+ (1,0) [0|255] ""  DUMMY_ECU
 SG_ WCBS_Calibration_Resp_A58 : 471|8@0+ (1,0) [0|255] ""  DUMMY_ECU
 SG_ WCBS_Calibration_Resp_A59 : 479|8@0+ (1,0) [0|255] ""  DUMMY_ECU
 SG_ WCBS_Calibration_Resp_A60 : 487|8@0+ (1,0) [0|255] ""  DUMMY_ECU
 SG_ WCBS_Calibration_Resp_A61 : 495|8@0+ (1,0) [0|255] ""  DUMMY_ECU
 SG_ WCBS_Calibration_Resp_A62 : 503|8@0+ (1,0) [0|255] ""  DUMMY_ECU
 SG_ WCBS_Calibration_Resp_A63 : 511|8@0+ (1,0) [0|255] ""  DUMMY_ECU

CM_ SG_ 314 FCAM_ESA_Sts "The signal indicates the status of ESA function Off  passive, standby,active etc.";
CM_ SG_ 314 FCAM_ESA_Mode "ESA Setting";
CM_ SG_ 314 FCAM_ESA_check "ESA check";
CM_ SG_ 466 CRC_FCAM_DEBUG "Checksum";
CM_ SG_ 466 ALIVE_FCAM_DEBUG "Alive Counter";
CM_ SG_ 466 FCAM_TSR_SLWSwtResp "TSR alarm function switch feedback";
CM_ SG_ 466 FCAM_FC_CalibrationSts "Front camera calibration status";
CM_ SG_ 466 FCAM_BlockageSts "Front camera occlusion status";
CM_ SG_ 466 FCAM_AEB_ABA_Req "ADAS requests ABA";
CM_ SG_ 466 FCAM_AEB_AWB_Req "Request short brake warning from WCBS";
CM_ SG_ 466 FCAM_AEB_TgtDecel_Req "AEB deceleration request";
CM_ SG_ 466 FCAM_AEB_VehHldReq "AEB requests WCBS to hold the vehicle";
CM_ SG_ 466 FCAM_AEB_AWB_Level "Requirements for different levels of braking";
CM_ SG_ 466 FCAM_ACC_AdtUpperJerkLimit "Upper jerk limit of acceleration";
CM_ SG_ 466 FCAM_ACC_AdtLowerJerkLimit "Lower jerk limit of acceleration";
CM_ SG_ 467 FCAM_Curve_DecelRaw "Raw deceleration requested in  curvature before limiter";
CM_ SG_ 467 FCAM_Curve_PredictionLatAcc "Predicted lateral acceleration under curvature";
CM_ SG_ 467 FCAM_Curve_TargetSpeed "Required target speed in curve";
CM_ SG_ 471 CRC_FCAM_ADCU_Handshake "Checksum";
CM_ SG_ 471 ALIVE_FCAM_ADCU_Handshake "Alive Counter";
CM_ SG_ 471 FCAM_ADCU_Alive_Distinguish "FCAM acknowledge to ADCU that FCAM is Alive";
CM_ SG_ 471 FCAM_ADCU_CONTROL_SOURCE "FCAM to ADCU handshake to know if FCAM is controlling or ADCU";
CM_ BO_ 813 "FCAM_ACC_Status";
CM_ SG_ 813 CRC_FCAM_ACC_Status "Checksum";
CM_ SG_ 813 ALIVE_FCAM_ACC_Status "Alive Counter";
CM_ SG_ 813 FCAM_ACC_Information "ACC Fail Information in FCAM side";
CM_ SG_ 813 FCAM_ACC_Main_Mode "Main switch status of ACC";
CM_ SG_ 813 FCAM_ACC_AccelDecel_Cmd "Target Acceleration/Deceleration of ACC";
CM_ SG_ 813 FCAM_ACC_StandstillReq "Standstill request flag (it is only for ACC)";
CM_ SG_ 813 FCAM_ACC_Mode "ACC control state";
CM_ SG_ 813 FCAM_ACC_IDB_DecCmdAct "Flag which indicates that the deceleration command from FCAM is valid or not";
CM_ BO_ 814 "FCAM_AEB_Status";
CM_ SG_ 814 CRC_FCAM_AEB_Status "Checksum";
CM_ SG_ 814 ALIVE_FCAM_AEB_Status "Alive Counter";
CM_ SG_ 814 FCAM_AEB_Prefill "Request to activate Pre-fill function";
CM_ SG_ 814 FCAM_AEB_HBA_Level "Request to activate HBA (Hydraulic Boost Assist) function.";
CM_ SG_ 814 FCAM_AEB_Target_Deceleration "Deceleration command value of Pre, Full-Brake function";
CM_ SG_ 814 FCAM_AEB_HBA_Req "Request to activate HBA (Hydraulic Boost Assist) function.";
CM_ SG_ 814 FCAM_AEB_Braking_Progress "Request to activate Brake";
CM_ SG_ 814 FCAM_AEB_Hold "Request flag for vehicle stop";
CM_ SG_ 814 FCAM_AEB_DBS_Active "Indicate the DBS function activation";
CM_ BO_ 851 "ADAS Adaptive Cruise Control";
CM_ SG_ 851 CRC_FCAM_CMP_ACC "Checksum";
CM_ SG_ 851 ALIVE_FCAM_CMP_ACC "Alive Counter";
CM_ SG_ 851 FCAM_ACC_ObjDetec "Lead Object Detected or not";
CM_ SG_ 851 FCAM_ISA_check "Inteligent Speed adaptation Check";
CM_ SG_ 851 FCAM_ISA_Mode_SW_Feed "Feedback of ISA On off(From Steering wheel button)";
CM_ SG_ 851 FCAM_TagSpeed_ICON_Feed "ICON Feedback Request for Target Speed Feedback Display";
CM_ SG_ 851 FCAM_ISA_PopUp_Feed "PopUP Messaging for ISA function";
CM_ SG_ 851 FCAM_ISA_Btn_Feed "Feedback of ISA On Off Button";
CM_ SG_ 851 FCAM_ACC_DistSet_upper_Feed "Feedback of Object Vehicle Gap Distance Adjustment (Increase Button)";
CM_ SG_ 851 FCAM_ACC_TimeGapSet "Adaptive Cruise Control time gap setting";
CM_ SG_ 851 FCAM_ACC_State "The signal indicates the status of the Adaptive Cruise Control function";
CM_ SG_ 851 FCAM_ACC_TagSpeed "Adaptive Cruise Control speed setting";
CM_ SG_ 851 FCAM_ACC_PopUp_Feed "PopUP Messaging for ACC function";
CM_ SG_ 851 FCAM_ACC_check "Adaptive Cruise Control Check";
CM_ SG_ 851 FCAM_ISA_ICON_Feed "ICON Feedback Request for ISA function";
CM_ SG_ 851 FCAM_ACC_DistSet_lower_Feed "Feedback of Object Vehicle Gap Distance Adjustment ( Reduction Button)";
CM_ SG_ 851 FCAM_ACC_SpdSet_upper_Feed "Feedback of Subject Vehicle Speed Setting (Increase Button)";
CM_ SG_ 851 FCAM_ACC_SpdSet_lower_Feed "Feedback of Subject Vehicle Speed Setting ( Reduction Button)";
CM_ SG_ 851 FCAM_ACC_On_Feed "Feedback of ACC On Off Button";
CM_ SG_ 851 FCAM_ACC_Set_Feed "Feedback of ACC Set Button";
CM_ SG_ 851 FCAM_ACC_CnlBtn_Feed "Feedback of ACC Cancel Button";
CM_ SG_ 851 FCAM_ACC_Res_Feed "Feedback of ACC Resume Button";
CM_ SG_ 851 FCAM_ACC_ICON_Feed "ICON Feedback Request for ACC function";
CM_ SG_ 851 FCAM_ISA_Status "The signal indicates the status of the ISA function";
CM_ SG_ 851 FCAM_ACC_DriveOff "DriveOff request flag";
CM_ BO_ 890 "Steering Angle Request for FCAM lateral control features";
CM_ SG_ 890 CRC_FCAM_EPS_LATE_CON "Checksum";
CM_ SG_ 890 ALIVE_FCAM_EPS_LATE_CON "Alive Counter";
CM_ SG_ 890 FCAM_EPS_StrWhe_TOLAct "Active TOL request for torque overlay control";
CM_ SG_ 890 FCAM_EPS_StrWhe_AOLAct "Active AOL request for Angle overlay control";
CM_ SG_ 890 FCAM_EPS_AOLReq "Steering Angle Request for FCAM lateral control features";
CM_ SG_ 890 FCAM_EPS_Torq_Fact_Req "Adjust the torque factor of the power steering assist";
CM_ SG_ 890 FCAM_EPS_DrvTorq_SubFact_Req "Driver torque coefficient request.";
CM_ SG_ 1117 CRC_FCAM_Heater_Request "Checksum";
CM_ SG_ 1117 ALIVE_FCAM_Heater_Request "Alive Counter";
CM_ SG_ 1117 FCAM_HeaterActivation_Req "FCAM Request Windshield Heating";
CM_ SG_ 853 FCAM_ADAS_CDSMaster_BasicCruise "Basic Cruise Control & Speed limiter (L0) CDS";
CM_ SG_ 853 FCAM_ADAS_CDSMaster_ALCA "ALCA - Auto Lane Changing Assist   (L2) CDS";
CM_ SG_ 853 FCAM_ADAS_CDSMaster_AESA "AESA - Automatic Emergency Stop Assist  (L2) CDS";
CM_ SG_ 853 FCAM_ADAS_CDSMaster_HWA "HWA / TJA - Highway Driving Assist  / Traffic Jam Assist CDS";
CM_ SG_ 853 FCAM_ADAS_CDSMaster_NOP "NOP - Navigation on Pilot (Highway) (L2+) CDS";
CM_ SG_ 853 FCAM_ADAS_CDSMaster_ISA "ISA - Intelligent Speed Adjustment (L1) CDS";
CM_ SG_ 853 FCAM_ADAS_CDSMaster_TSR "TSR - Traffic Sign Recognition  (L0) CDS";
CM_ SG_ 853 FCAM_ADAS_CDSMaster_ACC "ACC - Adaptive Cruise Control  (L1) CDS";
CM_ SG_ 853 FCAM_ADAS_CDSMaster_TLD "TLD - Traffic Light Detection (L0) CDS";
CM_ SG_ 853 FCAM_ADAS_CDSMaster_AACC "AACC - Advaced Adaptive Cruise Control  (L1) CDS";
CM_ SG_ 853 FCAM_ADAS_CDSMaster_ALCM "ALCM - Advanced Lane Change Maneuver  (L2+) CDS";
CM_ SG_ 853 FCAM_ADAS_CDSMaster_AAESA "AAESA - Advaced Automatic Emergency Stop Assist  (L2+)  CDS";
CM_ SG_ 853 FCAM_ADAS_CDSMaster_ELK "ELK - Emergency Lane Keep Assist (L1) CDS";
CM_ SG_ 853 FCAM_ADAS_CDSMaster_LKA "LKA - Lane Keep Assist  (L0) CDS";
CM_ SG_ 853 FCAM_ADAS_CDSMaster_LDW "LDW - Lane Departure Warning  (L0) CDS";
CM_ SG_ 853 FCAM_ADAS_CDSMaster_DNS "DNS - Departure Notification System (L0) CDS";
CM_ SG_ 853 FCAM_ADAS_CDSMaster_FCW "FCW - Forward Collision Warning (L0) CDS";
CM_ SG_ 853 FCAM_ADAS_CDSMaster_RAEB "RAEB - Rear Automatic Emergency Brake  (L0) CDS";
CM_ SG_ 853 FCAM_ADAS_CDSMaster_ESA "ESA - Evasive Steering Assist  (L0) CDS";
CM_ SG_ 853 FCAM_ADAS_CDSMaster_FAEB "FAEB - Front Automatic Emergency Brake  (L0) CDS";
CM_ SG_ 853 FCAM_ADAS_CDSMaster_RPA "RPA - Rear Parking Assist  (L0) CDS";
CM_ SG_ 853 FCAM_ADAS_CDSMaster_FPA "FPA - Front Parking Assist (L0) CDS";
CM_ SG_ 853 FCAM_ADAS_CDSMaster_RVC "RVC - Rear View Camera (L0) CDS";
CM_ SG_ 853 FCAM_ADAS_CDSMaster_SVM "SVM - Surround View Monitoring (L0)  CDS";
CM_ SG_ 853 FCAM_ADAS_CDSMaster_VParkingComf "V-Parking Comfort (L2++)  CDS";
CM_ SG_ 853 FCAM_ADAS_CDSMaster_VParkingSele "V-Parking Select (L2+)  CDS";
CM_ SG_ 853 FCAM_ADAS_CDSMaster_RP "RP - Remote Parking Assist  (L2)  CDS";
CM_ SG_ 853 FCAM_ADAS_CDSMaster_SpaFAPA "SPA / FAPA - Smart Parking Assist  / Fully Automated Parking Assist (L2)  CDS";
CM_ SG_ 853 FCAM_ADAS_CDSMaster_ADB "ADB - Adaptive Driving Beam (L0) CDS";
CM_ SG_ 853 FCAM_ADAS_CDSMaster_AHB "AHB - Automatic High Beam  (L0 ) CDS";
CM_ SG_ 853 FCAM_ADAS_CDSMaster_VParkingAuto "V-Parking Auto Reverse (L2++) CDS";
CM_ SG_ 853 FCAM_ADAS_CDSMaster_VParkingSumm "V-Parking Comfort (L2++)  CDS";
CM_ SG_ 853 FCAM_ADAS_CDSMaster_AdasEDR "ADAS Event Data Recoder CDS";
CM_ SG_ 853 FCAM_ADAS_CDSMaster_DCM "DCM - Dash Cam Mode Recoder CDS";
CM_ SG_ 853 FCAM_ADAS_CDSMaster_DMSFaceID "Using DMS camera as FaceID, health tracking CDS";
CM_ SG_ 853 FCAM_ADAS_CDSMaster_DMS "DMS  - Driver Monitoring System (DDAW / ADDW) CDS";
CM_ SG_ 853 FCAM_ADAS_CDSMaster_L2_L2PLUS "Vehicle with or without ADCU";
CM_ SG_ 853 FCAM_ADAS_CDSMaster_SentryMode "Sentry Mode CDS";
CM_ SG_ 853 FCAM_ADAS_CDSMaster_ACPE "Acceleration control for Pedal Error (ACPE) CDS";
CM_ SG_ 311 CRC_EAS_CDC_WorkState "Checksum";
CM_ SG_ 311 ALIVE_EAS_CDC_WorkState "Alive Counter";
CM_ SG_ 311 EAS_StiffStsFL "Stiffness state FL";
CM_ SG_ 311 EAS_StiffStsFR "Stiffness state FR";
CM_ SG_ 311 EAS_StiffStsRL "Stiffness state RL";
CM_ SG_ 311 EAS_StiffStsRR "Stiffness state RR";
CM_ SG_ 311 EAS_WorkSts "EAS Work state";
CM_ SG_ 311 CDC_WorkSts "CDC Work state";
CM_ SG_ 311 EAS_CDC_SystemWorkMode "EAS CDC system work mode";
CM_ SG_ 311 EAS_SuspensionMode "EAS Suspension Work mode";
CM_ SG_ 311 EAS_EasyAccessSts "EAS Easy Access state";
CM_ SG_ 311 CDC_DamperMode "CDC Work mode";
CM_ SG_ 311 EAS_ValveValue_FL "Left front air spring valve status";
CM_ SG_ 311 EAS_ValveValue_FR "Right front air spring valve status";
CM_ SG_ 311 EAS_ValveValue_RL "Left rear air spring valve status";
CM_ SG_ 311 EAS_ValveValue_RR "Right rear air spring valve status";
CM_ SG_ 311 EAS_EnableSts "EAS enable disable state";
CM_ SG_ 311 CDC_ValveValue_FL "Left front CDC valve status";
CM_ SG_ 311 CDC_ValveValue_FR "Right front CDC valve status";
CM_ SG_ 311 CDC_ValveValue_RL "Left rear CDC valve status";
CM_ SG_ 311 CDC_ValveValue_RR "Right rear CDC valve status";
CM_ SG_ 311 EAS_MntnSts "Air spring maintenance mode status";
CM_ SG_ 311 EAS_EasyLoadingSetFb "Easy load mode feedback";
CM_ SG_ 311 EAS_LiftModFb "Automatic lift/jack mode feedback";
CM_ SG_ 311 EAS_VehicleUpDownState "Vehicle up and down status";
CM_ SG_ 311 EAS_Overheat_Warning "Overheating protection prompt for gas supply pump";
CM_ SG_ 311 EAS_VehiclePositionState "Vehicle Position State";
CM_ SG_ 311 EAS_VehicleTargetPositionState "Vehicle Target Position State";
CM_ SG_ 555 CRC_ADCU_FCAM_ActuatorReq "Checksum";
CM_ SG_ 555 ALIVE_ADCU_FCAM_ActuatorReq "Alive Counter";
CM_ SG_ 555 ADCU_ACC_AccelDecel_Cmd "ADCU acceleration and deceleration commands in ACC mode";
CM_ SG_ 555 ADCU_ACC_IDB_DecCmdAct "Feedback on the actual execution of the ACC system";
CM_ SG_ 555 ADCU_ACC_StandstillReq "ADCU sends a parking request to the braking system in ACC mode";
CM_ SG_ 555 ADCU_ACC_Information "ADCU's ACC information";
CM_ SG_ 555 ADCU_ACC_DriveOff "Start command for ACC system";
CM_ SG_ 555 ADCU_EPS_AOLReq "ADCU sends steering active override limit command to EPS";
CM_ SG_ 555 ADCU_EPS_StrWhe_AOLAct "Actual active override limit sent by ADCU to EPS";
CM_ SG_ 555 ADCU_EPS_StrWhe_TOLAct "The actual torque of the steering wheel sent by ADCU to EPS exceeds the control limit";
CM_ SG_ 555 ADCU_EPS_Torq_Fact_Req "ADCU sends steering torque coefficient command to EPS";
CM_ SG_ 555 ADCU_LSS_Activation "LSS Activation source";
CM_ SG_ 555 ADCU_LSS_Activation_2 "Supplementory Lateral control mode signal";
CM_ SG_ 678 ADCU_NOP_Ctrl "NOP Controller OP";
CM_ BO_ 821 "For redundancy when ADCU controlling AEB when FCAM fail, or switching logic not work, and ADCU sending out AEB flag ";
CM_ SG_ 821 CRC_ADCU_AEB_Status "Checksum";
CM_ SG_ 821 ALIVE_ADCU_AEB_Status "Alive Counter";
CM_ SG_ 821 ADCU_AEB_Prefill "Request to activate Pre-fill function";
CM_ SG_ 821 ADCU_AEB_HBA_Level "Request to activate HBA (Hydraulic Boost Assist) function.";
CM_ SG_ 821 ADCU_AEB_Target_Deceleration "Deceleration command value of Pre, Full-Brake function";
CM_ SG_ 821 ADCU_AEB_HBA_Req "Request to activate HBA (Hydraulic Boost Assist) function.";
CM_ SG_ 821 ADCU_AEB_Braking_Progress "Request to activate Brake";
CM_ SG_ 821 ADCU_AEB_Hold "Request flag for vehicle stop";
CM_ SG_ 821 ADCU_AEB_DBS_Active "Indicate the DBS function activation";
CM_ SG_ 470 ADCU_TSR_SLWSwtResp "TSR alarm function switch feedback";
CM_ SG_ 470 ADCU_FC_CalibrationSts "Front camera calibration status";
CM_ SG_ 470 ADCU_BlockageSts "Front camera occlusion status";
CM_ SG_ 470 ADCU_AEB_ABA_Req "ADAS requests ABA";
CM_ SG_ 470 ADCU_AEB_AWB_Req "Request short brake warning from WCBS";
CM_ SG_ 470 ADCU_AEB_TgtDecel_Req "AEB deceleration request";
CM_ SG_ 470 ADCU_AEB_VehHldReq "AEB requests WCBS to hold the vehicle";
CM_ SG_ 470 ADCU_AEB_AWB_Level "Requirements for different levels of braking";
CM_ SG_ 470 ADCU_ACC_AdtUpperJerkLimit "Upper jerk limit of acceleration";
CM_ SG_ 470 ADCU_ACC_AdtLowerJerkLimit "Lower jerk limit of acceleration";
CM_ SG_ 472 CRC_ADCU_FCAM_Handshake "Checksum";
CM_ SG_ 472 ALIVE_ADCU_FCAM_Handshake "Alive Counter";
CM_ SG_ 472 ADCU_FCAM_Alive_Distinguish "ADCU acknowledge to FCAM that ADCU is Alive";
CM_ SG_ 472 ADCU_FCAM_CONTROL_SOURCE "ADCU to FCAM handshake to know if FCAM is controlling or ADCU";
CM_ SG_ 313 CRC_ADCU_LSS_EPS_REQUEST "Checksum";
CM_ SG_ 313 ALIVE_ADCU_LSS_EPS_REQUEST "Alive Counter";
CM_ SG_ 313 ADCU_LSS_Activation_3 "ADCU LSS Activation source";
CM_ SG_ 313 ADCU_LSS_Activation_4 "ADCU Supplementory Lateral control mode signal";
CM_ SG_ 589 CRC_ADCU_BRAKE_CMD "Checksum";
CM_ SG_ 589 ALIVE_ADCU_BRAKE_CMD "Alive Counter";
CM_ SG_ 589 ADCU_RAEB_BrakeCommand "RAEB brake command to Brake module";
CM_ SG_ 589 ADCU_RAEB_Available "RAEB Function avaiblity";
CM_ SG_ 589 ADCU_RAEB_FuncActive "RAEB function activation status";
CM_ SG_ 589 ADCU_RAEB_BrakeType "Low Speed Brake type";
CM_ SG_ 589 ADCU_RAEB_PullEPBOpt "Pull EPB option for Post RAEB";
CM_ SG_ 642 ADCU_CVC_VAP_GearPosReq "Parking System Gear Position Request";
CM_ SG_ 1282 CVC_srcNodeID "Network Management Signal";
CM_ SG_ 1282 CVC_CtrlBitVector "Network Management Signal";
CM_ SG_ 1282 CVC_usrData0 "Network Management Signal";
CM_ SG_ 1282 CVC_usrData1 "Network Management Signal";
CM_ SG_ 1282 CVC_usrData2 "Network Management Signal";
CM_ SG_ 1282 CVC_usrData3 "Network Management Signal";
CM_ SG_ 1282 CVC_usrData4 "Network Management Signal";
CM_ SG_ 1282 CVC_usrData5 "Network Management Signal";
CM_ SG_ 1320 EPS_srcNodeID "Network Management Signal";
CM_ SG_ 1320 EPS_CtrlBitVector "Network Management Signal";
CM_ SG_ 1320 EPS_usrData0 "Network Management Signal";
CM_ SG_ 1320 EPS_usrData1 "Network Management Signal";
CM_ SG_ 1320 EPS_usrData2 "Network Management Signal";
CM_ SG_ 1320 EPS_usrData3 "Network Management Signal";
CM_ SG_ 1320 EPS_usrData4 "Network Management Signal";
CM_ SG_ 1320 EPS_usrData5 "Network Management Signal";
CM_ SG_ 1302 FCAM_srcNodeID "Network Management Signal";
CM_ SG_ 1302 FCAM_CtrlBitVector "Network Management Signal";
CM_ SG_ 1302 FCAM_usrData0 "Network Management Signal";
CM_ SG_ 1302 FCAM_usrData1 "Network Management Signal";
CM_ SG_ 1302 FCAM_usrData2 "Network Management Signal";
CM_ SG_ 1302 FCAM_usrData3 "Network Management Signal";
CM_ SG_ 1302 FCAM_usrData4 "Network Management Signal";
CM_ SG_ 1302 FCAM_usrData5 "Network Management Signal";
CM_ SG_ 1344 ADCU_srcNodeID "Network Management Signal";
CM_ SG_ 1344 ADCU_CtrlBitVector "Network Management Signal";
CM_ SG_ 1344 ADCU_usrData0 "Network Management Signal";
CM_ SG_ 1344 ADCU_usrData1 "Network Management Signal";
CM_ SG_ 1344 ADCU_usrData2 "Network Management Signal";
CM_ SG_ 1344 ADCU_usrData3 "Network Management Signal";
CM_ SG_ 1344 ADCU_usrData4 "Network Management Signal";
CM_ SG_ 1344 ADCU_usrData5 "Network Management Signal";
CM_ SG_ 1704 EPS_DiagReqData0 "Diagnostic signal Data request";
CM_ SG_ 1704 EPS_DiagReqData1 "Diagnostic signal Data request";
CM_ SG_ 1704 EPS_DiagReqData2 "Diagnostic signal Data request";
CM_ SG_ 1704 EPS_DiagReqData3 "Diagnostic signal Data request";
CM_ SG_ 1704 EPS_DiagReqData4 "Diagnostic signal Data request";
CM_ SG_ 1704 EPS_DiagReqData5 "Diagnostic signal Data request";
CM_ SG_ 1704 EPS_DiagReqData6 "Remote Diagnostic signal Data request";
CM_ SG_ 1704 EPS_DiagReqData7 "Remote Diagnostic signal Data request";
CM_ SG_ 1576 EPS_DiagRespData0 "Diagnostic signal Data response";
CM_ SG_ 1576 EPS_DiagRespData1 "Remote Diagnostic signal Data response";
CM_ SG_ 1576 EPS_DiagRespData2 "Diagnostic signal Data response";
CM_ SG_ 1576 EPS_DiagRespData3 "Diagnostic signal Data response";
CM_ SG_ 1576 EPS_DiagRespData4 "Diagnostic signal Data response";
CM_ SG_ 1576 EPS_DiagRespData5 "Diagnostic signal Data response";
CM_ SG_ 1576 EPS_DiagRespData6 "Remote Diagnostic signal Data response";
CM_ SG_ 1576 EPS_DiagRespData7 "Diagnostic signal Data response";
CM_ SG_ 1705 WCBS_DiagReqData0 "Diagnostic signal Data request";
CM_ SG_ 1705 WCBS_DiagReqData1 "Diagnostic signal Data request";
CM_ SG_ 1705 WCBS_DiagReqData2 "Diagnostic signal Data request";
CM_ SG_ 1705 WCBS_DiagReqData3 "Diagnostic signal Data request";
CM_ SG_ 1705 WCBS_DiagReqData4 "Diagnostic signal Data request";
CM_ SG_ 1705 WCBS_DiagReqData5 "Diagnostic signal Data request";
CM_ SG_ 1705 WCBS_DiagReqData6 "Remote Diagnostic signal Data request";
CM_ SG_ 1705 WCBS_DiagReqData7 "Remote Diagnostic signal Data request";
CM_ SG_ 1577 WCBS_DiagRespData0 "Diagnostic signal Data response";
CM_ SG_ 1577 WCBS_DiagRespData1 "Remote Diagnostic signal Data response";
CM_ SG_ 1577 WCBS_DiagRespData2 "Diagnostic signal Data response";
CM_ SG_ 1577 WCBS_DiagRespData3 "Diagnostic signal Data response";
CM_ SG_ 1577 WCBS_DiagRespData4 "Diagnostic signal Data response";
CM_ SG_ 1577 WCBS_DiagRespData5 "Diagnostic signal Data response";
CM_ SG_ 1577 WCBS_DiagRespData6 "Remote Diagnostic signal Data response";
CM_ SG_ 1577 WCBS_DiagRespData7 "Diagnostic signal Data response";
CM_ SG_ 1686 FCAM_DiagReqData0 "Diagnostic signal Data request";
CM_ SG_ 1686 FCAM_DiagReqData1 "Diagnostic signal Data request";
CM_ SG_ 1686 FCAM_DiagReqData2 "Diagnostic signal Data request";
CM_ SG_ 1686 FCAM_DiagReqData3 "Diagnostic signal Data request";
CM_ SG_ 1686 FCAM_DiagReqData4 "Diagnostic signal Data request";
CM_ SG_ 1686 FCAM_DiagReqData5 "Diagnostic signal Data request";
CM_ SG_ 1686 FCAM_DiagReqData6 "Diagnostic signal Data request";
CM_ SG_ 1686 FCAM_DiagReqData7 "Diagnostic signal Data request";
CM_ SG_ 1558 FCAM_DiagRespData0 "Diagnostic signal Data response";
CM_ SG_ 1558 FCAM_DiagRespData1 "Diagnostic signal Data response";
CM_ SG_ 1558 FCAM_DiagRespData2 "Diagnostic signal Data response";
CM_ SG_ 1558 FCAM_DiagRespData3 "Diagnostic signal Data response";
CM_ SG_ 1558 FCAM_DiagRespData4 "Diagnostic signal Data response";
CM_ SG_ 1558 FCAM_DiagRespData5 "Diagnostic signal Data response";
CM_ SG_ 1558 FCAM_DiagRespData6 "Diagnostic signal Data response";
CM_ SG_ 1558 FCAM_DiagRespData7 "Diagnostic signal Data response";
CM_ SG_ 1728 ADCU_DiagReqData0 "Diagnostic signal Data request";
CM_ SG_ 1728 ADCU_DiagReqData1 "Diagnostic signal Data request";
CM_ SG_ 1728 ADCU_DiagReqData2 "Diagnostic signal Data request";
CM_ SG_ 1728 ADCU_DiagReqData3 "Diagnostic signal Data request";
CM_ SG_ 1728 ADCU_DiagReqData4 "Diagnostic signal Data request";
CM_ SG_ 1728 ADCU_DiagReqData5 "Diagnostic signal Data request";
CM_ SG_ 1728 ADCU_DiagReqData6 "Diagnostic signal Data request";
CM_ SG_ 1728 ADCU_DiagReqData7 "Diagnostic signal Data request";
CM_ SG_ 1600 ADCU_DiagRespData0 "Diagnostic signal Data response";
CM_ SG_ 1600 ADCU_DiagRespData1 "Diagnostic signal Data response";
CM_ SG_ 1600 ADCU_DiagRespData2 "Diagnostic signal Data response";
CM_ SG_ 1600 ADCU_DiagRespData3 "Diagnostic signal Data response";
CM_ SG_ 1600 ADCU_DiagRespData4 "Diagnostic signal Data response";
CM_ SG_ 1600 ADCU_DiagRespData5 "Diagnostic signal Data response";
CM_ SG_ 1600 ADCU_DiagRespData6 "Diagnostic signal Data response";
CM_ SG_ 1600 ADCU_DiagRespData7 "Diagnostic signal Data response";
CM_ SG_ 1791 OBD_Func_DiagReqData0 "Diagnostic message all ECUs";
CM_ SG_ 1791 OBD_Func_DiagReqData1 "Diagnostic message all ECUs";
CM_ SG_ 1791 OBD_Func_DiagReqData2 "Diagnostic message all ECUs";
CM_ SG_ 1791 OBD_Func_DiagReqData3 "Diagnostic message all ECUs";
CM_ SG_ 1791 OBD_Func_DiagReqData4 "Diagnostic message all ECUs";
CM_ SG_ 1791 OBD_Func_DiagReqData5 "Diagnostic message all ECUs";
CM_ SG_ 1791 OBD_Func_DiagReqData6 "Diagnostic message all ECUs";
CM_ SG_ 1791 OBD_Func_DiagReqData7 "Diagnostic message all ECUs";
BA_DEF_ BO_  "DiagRequest" ENUM  "No","Yes";
BA_DEF_ BO_  "DiagResponse" ENUM  "No","Yes";
BA_DEF_ BO_  "DiagState" ENUM  "No","Yes";
BA_DEF_ BO_  "GenMsgCycleTime" INT 0 65535;
BA_DEF_ BO_  "GenMsgCycleTimeFast" INT 0 65535;
BA_DEF_ BO_  "GenMsgDelayTime" INT 0 65535;
BA_DEF_ BO_  "GenMsgILSupport" ENUM  "No","Yes";
BA_DEF_ BO_  "GenMsgNrOfRepetition" INT 0 65535;
BA_DEF_ BO_  "GenMsgSendType" ENUM  "Cyclic","NoMsgSendType","NotUsed","NotUsed","NotUsed","NotUsed","NotUsed","IfActive","NoMsgSendType","NotUsed";
BA_DEF_ BO_  "NmAsrMessage" ENUM  "No","Yes";
BA_DEF_ BO_  "NmMessage" ENUM  "No","Yes";
BA_DEF_ SG_  "GenSigSendType" ENUM  "Cyclic","NoSigSendType","OnWriteWithRepetition","OnChange","OnChangeWithRepetition","IfActive","IfActiveWithRepetition","OnWrite","NotUsed","NotUsed","NotUsed","NotUsed","NotUsed";
BA_DEF_ SG_  "GenSigStartValue" INT 0 2147483647;
BA_DEF_ SG_  "GenSigTimeoutTime_ALL" INT 0 65535;
BA_DEF_ SG_  "InvalidValue" STRING ;
BA_DEF_ SG_  "GenSigInactiveValue" INT 0 2147483647;
BA_DEF_ BO_  "VFrameFormat" ENUM  "StandardCAN","ExtendedCAN","reserved","J1939PG","reserved","reserved","reserved","reserved","reserved","reserved","reserved","reserved","reserved","reserved","StandardCAN_FD","ExtendedCAN_FD";
BA_DEF_ BO_  "CANFD_BRS" ENUM  "0","1";
BA_DEF_ SG_  "SystemSignalLongSymbol" STRING ;
BA_DEF_DEF_  "DiagRequest" "No";
BA_DEF_DEF_  "DiagResponse" "No";
BA_DEF_DEF_  "DiagState" "No";
BA_DEF_DEF_  "GenMsgCycleTime" 0;
BA_DEF_DEF_  "GenMsgCycleTimeFast" 0;
BA_DEF_DEF_  "GenMsgDelayTime" 0;
BA_DEF_DEF_  "GenMsgILSupport" "Yes";
BA_DEF_DEF_  "GenMsgNrOfRepetition" 0;
BA_DEF_DEF_  "GenMsgSendType" "Cyclic";
BA_DEF_DEF_  "NmAsrMessage" "No";
BA_DEF_DEF_  "NmMessage" "No";
BA_DEF_DEF_  "GenSigSendType" "Cyclic";
BA_DEF_DEF_  "GenSigStartValue" 0;
BA_DEF_DEF_  "GenSigTimeoutTime_ALL" 0;
BA_DEF_DEF_  "InvalidValue" "";
BA_DEF_DEF_  "GenSigInactiveValue" 0;
BA_DEF_DEF_  "VFrameFormat" "StandardCAN_FD";
BA_DEF_DEF_  "CANFD_BRS" "1";
BA_DEF_DEF_  "SystemSignalLongSymbol" "";
BA_ "GenMsgCycleTime" BO_ 314 20;
BA_ "GenMsgCycleTime" BO_ 466 20;
BA_ "GenMsgCycleTime" BO_ 467 100;
BA_ "GenMsgCycleTime" BO_ 471 20;
BA_ "GenMsgCycleTime" BO_ 813 20;
BA_ "GenMsgCycleTime" BO_ 814 20;
BA_ "GenMsgNrOfRepetition" BO_ 851 3;
BA_ "GenMsgCycleTimeFast" BO_ 851 15;
BA_ "GenMsgCycleTime" BO_ 851 50;
BA_ "GenMsgCycleTime" BO_ 890 10;
BA_ "GenMsgCycleTime" BO_ 1117 100;
BA_ "GenMsgNrOfRepetition" BO_ 853 2;
BA_ "GenMsgCycleTime" BO_ 853 100;
BA_ "GenMsgSendType" BO_ 1970 1;
BA_ "GenMsgNrOfRepetition" BO_ 1970 2;
BA_ "GenMsgCycleTimeFast" BO_ 1970 50;
BA_ "GenMsgCycleTime" BO_ 311 20;
BA_ "GenMsgCycleTime" BO_ 555 10;
BA_ "GenMsgCycleTime" BO_ 678 20;
BA_ "GenMsgCycleTime" BO_ 693 20;
BA_ "GenMsgCycleTime" BO_ 821 20;
BA_ "GenMsgCycleTime" BO_ 470 20;
BA_ "GenMsgCycleTime" BO_ 472 20;
BA_ "GenMsgCycleTime" BO_ 313 20;
BA_ "GenMsgCycleTime" BO_ 589 20;
BA_ "GenMsgCycleTime" BO_ 640 50;
BA_ "GenMsgCycleTime" BO_ 641 20;
BA_ "GenMsgCycleTime" BO_ 642 20;
BA_ "GenMsgCycleTime" BO_ 643 20;
BA_ "GenMsgILSupport" BO_ 1282 0;
BA_ "GenMsgCycleTime" BO_ 1282 640;
BA_ "VFrameFormat" BO_ 1282 0;
BA_ "NmAsrMessage" BO_ 1282 1;
BA_ "NmMessage" BO_ 1282 1;
BA_ "GenMsgILSupport" BO_ 1320 0;
BA_ "GenMsgCycleTime" BO_ 1320 640;
BA_ "VFrameFormat" BO_ 1320 0;
BA_ "NmAsrMessage" BO_ 1320 1;
BA_ "NmMessage" BO_ 1320 1;
BA_ "GenMsgILSupport" BO_ 1321 0;
BA_ "GenMsgCycleTime" BO_ 1321 640;
BA_ "VFrameFormat" BO_ 1321 0;
BA_ "NmAsrMessage" BO_ 1321 1;
BA_ "NmMessage" BO_ 1321 1;
BA_ "GenMsgILSupport" BO_ 1302 0;
BA_ "GenMsgCycleTime" BO_ 1302 640;
BA_ "VFrameFormat" BO_ 1302 0;
BA_ "NmAsrMessage" BO_ 1302 1;
BA_ "NmMessage" BO_ 1302 1;
BA_ "GenMsgILSupport" BO_ 1344 0;
BA_ "GenMsgCycleTime" BO_ 1344 640;
BA_ "VFrameFormat" BO_ 1344 0;
BA_ "NmAsrMessage" BO_ 1344 1;
BA_ "NmMessage" BO_ 1344 1;
BA_ "GenMsgSendType" BO_ 1704 1;
BA_ "DiagRequest" BO_ 1704 1;
BA_ "DiagState" BO_ 1704 1;
BA_ "GenMsgILSupport" BO_ 1704 0;
BA_ "GenMsgSendType" BO_ 1576 1;
BA_ "DiagResponse" BO_ 1576 1;
BA_ "DiagState" BO_ 1576 1;
BA_ "GenMsgILSupport" BO_ 1576 0;
BA_ "GenMsgSendType" BO_ 1705 1;
BA_ "DiagRequest" BO_ 1705 1;
BA_ "DiagState" BO_ 1705 1;
BA_ "GenMsgILSupport" BO_ 1705 0;
BA_ "GenMsgSendType" BO_ 1577 1;
BA_ "DiagResponse" BO_ 1577 1;
BA_ "DiagState" BO_ 1577 1;
BA_ "GenMsgILSupport" BO_ 1577 0;
BA_ "GenMsgSendType" BO_ 1686 1;
BA_ "DiagRequest" BO_ 1686 1;
BA_ "DiagState" BO_ 1686 1;
BA_ "GenMsgILSupport" BO_ 1686 0;
BA_ "GenMsgSendType" BO_ 1558 1;
BA_ "DiagResponse" BO_ 1558 1;
BA_ "DiagState" BO_ 1558 1;
BA_ "GenMsgILSupport" BO_ 1558 0;
BA_ "GenMsgSendType" BO_ 1728 1;
BA_ "DiagRequest" BO_ 1728 1;
BA_ "DiagState" BO_ 1728 1;
BA_ "GenMsgILSupport" BO_ 1728 0;
BA_ "GenMsgSendType" BO_ 1600 1;
BA_ "DiagResponse" BO_ 1600 1;
BA_ "DiagState" BO_ 1600 1;
BA_ "GenMsgILSupport" BO_ 1600 0;
BA_ "GenMsgSendType" BO_ 1791 1;
BA_ "DiagState" BO_ 1791 1;
BA_ "GenMsgILSupport" BO_ 1791 0;
BA_ "DiagRequest" BO_ 1791 1;
BA_ "GenMsgSendType" BO_ 1872 1;
BA_ "GenMsgSendType" BO_ 1888 1;
BA_ "GenMsgSendType" BO_ 1873 1;
BA_ "GenMsgSendType" BO_ 1889 1;
BA_ "InvalidValue" SG_ 314 ALIVE_FCAM_ESA_Sts "Fh";
BA_ "GenSigTimeoutTime_ALL" SG_ 314 FCAM_ESA_Sts 100;
BA_ "GenSigTimeoutTime_ALL" SG_ 314 FCAM_ESA_Execution_Side 100;
BA_ "GenSigTimeoutTime_ALL" SG_ 314 FCAM_ESA_Popup_Sts 100;
BA_ "GenSigTimeoutTime_ALL" SG_ 314 FCAM_ESA_Mode 100;
BA_ "GenSigTimeoutTime_ALL" SG_ 314 FCAM_ESA_check 500;
BA_ "GenSigStartValue" SG_ 314 FCAM_ESA_check 3;
BA_ "GenSigTimeoutTime_ALL" SG_ 466 CRC_FCAM_DEBUG 250;
BA_ "GenSigTimeoutTime_ALL" SG_ 466 ALIVE_FCAM_DEBUG 250;
BA_ "InvalidValue" SG_ 466 ALIVE_FCAM_DEBUG "Fh";
BA_ "InvalidValue" SG_ 466 FCAM_ACC_AdtUpperJerkLimit "0h";
BA_ "InvalidValue" SG_ 466 FCAM_ACC_AdtLowerJerkLimit "0h";
BA_ "GenSigStartValue" SG_ 467 FCAM_Curve_DecelRaw 1200;
BA_ "InvalidValue" SG_ 467 FCAM_Curve_DecelRaw "0h";
BA_ "GenSigStartValue" SG_ 467 FCAM_Curve_PredictionLatAcc 1200;
BA_ "InvalidValue" SG_ 467 FCAM_Curve_PredictionLatAcc "0h";
BA_ "InvalidValue" SG_ 467 FCAM_Curve_TargetSpeed "0h";
BA_ "GenSigTimeoutTime_ALL" SG_ 471 CRC_FCAM_ADCU_Handshake 100;
BA_ "GenSigTimeoutTime_ALL" SG_ 471 ALIVE_FCAM_ADCU_Handshake 100;
BA_ "InvalidValue" SG_ 471 ALIVE_FCAM_ADCU_Handshake "Fh";
BA_ "GenSigTimeoutTime_ALL" SG_ 471 FCAM_ADCU_Alive_Distinguish 100;
BA_ "GenSigTimeoutTime_ALL" SG_ 471 FCAM_ADCU_CONTROL_SOURCE 100;
BA_ "GenSigTimeoutTime_ALL" SG_ 813 CRC_FCAM_ACC_Status 200;
BA_ "GenSigTimeoutTime_ALL" SG_ 813 ALIVE_FCAM_ACC_Status 200;
BA_ "InvalidValue" SG_ 813 ALIVE_FCAM_ACC_Status "Fh";
BA_ "GenSigTimeoutTime_ALL" SG_ 813 FCAM_ACC_Information 200;
BA_ "GenSigTimeoutTime_ALL" SG_ 813 FCAM_ACC_Main_Mode 200;
BA_ "GenSigTimeoutTime_ALL" SG_ 813 FCAM_ACC_AccelDecel_Cmd 200;
BA_ "GenSigStartValue" SG_ 813 FCAM_ACC_AccelDecel_Cmd 1200;
BA_ "InvalidValue" SG_ 813 FCAM_ACC_AccelDecel_Cmd "0h";
BA_ "GenSigTimeoutTime_ALL" SG_ 813 FCAM_ACC_StandstillReq 200;
BA_ "GenSigTimeoutTime_ALL" SG_ 813 FCAM_ACC_Mode 200;
BA_ "InvalidValue" SG_ 813 FCAM_ACC_Mode "7h";
BA_ "GenSigTimeoutTime_ALL" SG_ 813 FCAM_ACC_IDB_DecCmdAct 200;
BA_ "InvalidValue" SG_ 813 FCAM_ACC_IDB_DecCmdAct "7h";
BA_ "GenSigTimeoutTime_ALL" SG_ 814 CRC_FCAM_AEB_Status 200;
BA_ "GenSigTimeoutTime_ALL" SG_ 814 ALIVE_FCAM_AEB_Status 200;
BA_ "InvalidValue" SG_ 814 ALIVE_FCAM_AEB_Status "Fh";
BA_ "GenSigTimeoutTime_ALL" SG_ 814 FCAM_AEB_Prefill 200;
BA_ "GenSigTimeoutTime_ALL" SG_ 814 FCAM_AEB_HBA_Level 200;
BA_ "GenSigTimeoutTime_ALL" SG_ 814 FCAM_AEB_Target_Deceleration 200;
BA_ "InvalidValue" SG_ 814 FCAM_AEB_Target_Deceleration "0h";
BA_ "GenSigTimeoutTime_ALL" SG_ 814 FCAM_AEB_HBA_Req 200;
BA_ "GenSigTimeoutTime_ALL" SG_ 814 FCAM_AEB_Braking_Progress 200;
BA_ "GenSigTimeoutTime_ALL" SG_ 814 FCAM_AEB_Hold 200;
BA_ "GenSigTimeoutTime_ALL" SG_ 814 FCAM_AEB_DBS_Active 200;
BA_ "GenSigTimeoutTime_ALL" SG_ 851 CRC_FCAM_CMP_ACC 500;
BA_ "GenSigTimeoutTime_ALL" SG_ 851 ALIVE_FCAM_CMP_ACC 500;
BA_ "InvalidValue" SG_ 851 ALIVE_FCAM_CMP_ACC "Fh";
BA_ "GenSigSendType" SG_ 851 FCAM_ACC_ObjDetec 2;
BA_ "GenSigTimeoutTime_ALL" SG_ 851 FCAM_ACC_ObjDetec 500;
BA_ "GenSigSendType" SG_ 851 FCAM_ISA_check 2;
BA_ "GenSigTimeoutTime_ALL" SG_ 851 FCAM_ISA_check 500;
BA_ "InvalidValue" SG_ 851 FCAM_ISA_check "3h";
BA_ "GenSigSendType" SG_ 851 FCAM_ISA_Mode_SW_Feed 2;
BA_ "GenSigTimeoutTime_ALL" SG_ 851 FCAM_ISA_Mode_SW_Feed 500;
BA_ "GenSigSendType" SG_ 851 FCAM_TagSpeed_ICON_Feed 2;
BA_ "GenSigTimeoutTime_ALL" SG_ 851 FCAM_TagSpeed_ICON_Feed 500;
BA_ "InvalidValue" SG_ 851 FCAM_TagSpeed_ICON_Feed "7h";
BA_ "GenSigSendType" SG_ 851 FCAM_ISA_PopUp_Feed 2;
BA_ "GenSigTimeoutTime_ALL" SG_ 851 FCAM_ISA_PopUp_Feed 500;
BA_ "InvalidValue" SG_ 851 FCAM_ISA_PopUp_Feed "Fh";
BA_ "GenSigSendType" SG_ 851 FCAM_ISA_Btn_Feed 2;
BA_ "GenSigTimeoutTime_ALL" SG_ 851 FCAM_ISA_Btn_Feed 500;
BA_ "GenSigSendType" SG_ 851 FCAM_ACC_DistSet_upper_Feed 2;
BA_ "GenSigTimeoutTime_ALL" SG_ 851 FCAM_ACC_DistSet_upper_Feed 500;
BA_ "GenSigSendType" SG_ 851 FCAM_ACC_TimeGapSet 2;
BA_ "GenSigTimeoutTime_ALL" SG_ 851 FCAM_ACC_TimeGapSet 500;
BA_ "InvalidValue" SG_ 851 FCAM_ACC_TimeGapSet "7h";
BA_ "GenSigSendType" SG_ 851 FCAM_ACC_State 2;
BA_ "GenSigTimeoutTime_ALL" SG_ 851 FCAM_ACC_State 500;
BA_ "GenSigSendType" SG_ 851 FCAM_ACC_TagSpeed 2;
BA_ "GenSigTimeoutTime_ALL" SG_ 851 FCAM_ACC_TagSpeed 500;
BA_ "InvalidValue" SG_ 851 FCAM_ACC_TagSpeed "FFh";
BA_ "GenSigSendType" SG_ 851 FCAM_ACC_PopUp_Feed 2;
BA_ "GenSigTimeoutTime_ALL" SG_ 851 FCAM_ACC_PopUp_Feed 500;
BA_ "InvalidValue" SG_ 851 FCAM_ACC_PopUp_Feed "Fh";
BA_ "GenSigSendType" SG_ 851 FCAM_ACC_check 2;
BA_ "GenSigTimeoutTime_ALL" SG_ 851 FCAM_ACC_check 500;
BA_ "InvalidValue" SG_ 851 FCAM_ACC_check "3h";
BA_ "GenSigSendType" SG_ 851 FCAM_ISA_ICON_Feed 2;
BA_ "GenSigTimeoutTime_ALL" SG_ 851 FCAM_ISA_ICON_Feed 500;
BA_ "GenSigSendType" SG_ 851 FCAM_ACC_DistSet_lower_Feed 2;
BA_ "GenSigTimeoutTime_ALL" SG_ 851 FCAM_ACC_DistSet_lower_Feed 500;
BA_ "GenSigSendType" SG_ 851 FCAM_ACC_SpdSet_upper_Feed 2;
BA_ "GenSigTimeoutTime_ALL" SG_ 851 FCAM_ACC_SpdSet_upper_Feed 500;
BA_ "GenSigSendType" SG_ 851 FCAM_ACC_SpdSet_lower_Feed 2;
BA_ "GenSigTimeoutTime_ALL" SG_ 851 FCAM_ACC_SpdSet_lower_Feed 500;
BA_ "GenSigSendType" SG_ 851 FCAM_ACC_On_Feed 2;
BA_ "GenSigTimeoutTime_ALL" SG_ 851 FCAM_ACC_On_Feed 500;
BA_ "GenSigSendType" SG_ 851 FCAM_ACC_Set_Feed 2;
BA_ "GenSigTimeoutTime_ALL" SG_ 851 FCAM_ACC_Set_Feed 500;
BA_ "GenSigSendType" SG_ 851 FCAM_ACC_CnlBtn_Feed 2;
BA_ "GenSigTimeoutTime_ALL" SG_ 851 FCAM_ACC_CnlBtn_Feed 500;
BA_ "GenSigSendType" SG_ 851 FCAM_ACC_Res_Feed 2;
BA_ "GenSigTimeoutTime_ALL" SG_ 851 FCAM_ACC_Res_Feed 500;
BA_ "GenSigSendType" SG_ 851 FCAM_ACC_ICON_Feed 2;
BA_ "GenSigTimeoutTime_ALL" SG_ 851 FCAM_ACC_ICON_Feed 500;
BA_ "InvalidValue" SG_ 851 FCAM_ACC_ICON_Feed "7h";
BA_ "GenSigSendType" SG_ 851 FCAM_ISA_Status 2;
BA_ "GenSigTimeoutTime_ALL" SG_ 851 FCAM_ISA_Status 500;
BA_ "InvalidValue" SG_ 851 FCAM_ISA_Status "7h";
BA_ "GenSigSendType" SG_ 851 FCAM_ACC_DriveOff 2;
BA_ "GenSigTimeoutTime_ALL" SG_ 851 FCAM_ACC_DriveOff 500;
BA_ "GenSigTimeoutTime_ALL" SG_ 890 CRC_FCAM_EPS_LATE_CON 100;
BA_ "GenSigTimeoutTime_ALL" SG_ 890 ALIVE_FCAM_EPS_LATE_CON 100;
BA_ "InvalidValue" SG_ 890 ALIVE_FCAM_EPS_LATE_CON "Fh";
BA_ "GenSigTimeoutTime_ALL" SG_ 890 FCAM_EPS_StrWhe_TOLAct 100;
BA_ "GenSigTimeoutTime_ALL" SG_ 890 FCAM_EPS_StrWhe_AOLAct 100;
BA_ "GenSigTimeoutTime_ALL" SG_ 890 FCAM_EPS_AOLReq 100;
BA_ "InvalidValue" SG_ 890 FCAM_EPS_AOLReq "0h";
BA_ "GenSigTimeoutTime_ALL" SG_ 890 FCAM_EPS_Torq_Fact_Req 100;
BA_ "InvalidValue" SG_ 890 FCAM_EPS_Torq_Fact_Req "0h";
BA_ "GenSigTimeoutTime_ALL" SG_ 890 FCAM_EPS_DrvTorq_SubFact_Req 100;
BA_ "InvalidValue" SG_ 890 FCAM_EPS_DrvTorq_SubFact_Req "0h";
BA_ "GenSigTimeoutTime_ALL" SG_ 1117 CRC_FCAM_Heater_Request 1000;
BA_ "GenSigTimeoutTime_ALL" SG_ 1117 ALIVE_FCAM_Heater_Request 1000;
BA_ "InvalidValue" SG_ 1117 ALIVE_FCAM_Heater_Request "Fh";
BA_ "GenSigTimeoutTime_ALL" SG_ 1117 FCAM_HeaterActivation_Req 1000;
BA_ "InvalidValue" SG_ 1117 FCAM_HeaterActivation_Req "0h";
BA_ "GenSigSendType" SG_ 853 FCAM_ADAS_CDSMaster_BasicCruise 2;
BA_ "GenSigTimeoutTime_ALL" SG_ 853 FCAM_ADAS_CDSMaster_BasicCruise 1000;
BA_ "InvalidValue" SG_ 853 FCAM_ADAS_CDSMaster_BasicCruise "3h";
BA_ "GenSigSendType" SG_ 853 FCAM_ADAS_CDSMaster_ALCA 2;
BA_ "GenSigTimeoutTime_ALL" SG_ 853 FCAM_ADAS_CDSMaster_ALCA 1000;
BA_ "InvalidValue" SG_ 853 FCAM_ADAS_CDSMaster_ALCA "3h";
BA_ "GenSigSendType" SG_ 853 FCAM_ADAS_CDSMaster_AESA 2;
BA_ "GenSigTimeoutTime_ALL" SG_ 853 FCAM_ADAS_CDSMaster_AESA 1000;
BA_ "InvalidValue" SG_ 853 FCAM_ADAS_CDSMaster_AESA "3h";
BA_ "GenSigSendType" SG_ 853 FCAM_ADAS_CDSMaster_HWA 2;
BA_ "GenSigTimeoutTime_ALL" SG_ 853 FCAM_ADAS_CDSMaster_HWA 1000;
BA_ "InvalidValue" SG_ 853 FCAM_ADAS_CDSMaster_HWA "3h";
BA_ "GenSigSendType" SG_ 853 FCAM_ADAS_CDSMaster_NOP 2;
BA_ "GenSigTimeoutTime_ALL" SG_ 853 FCAM_ADAS_CDSMaster_NOP 1000;
BA_ "InvalidValue" SG_ 853 FCAM_ADAS_CDSMaster_NOP "3h";
BA_ "GenSigSendType" SG_ 853 FCAM_ADAS_CDSMaster_ISA 2;
BA_ "GenSigTimeoutTime_ALL" SG_ 853 FCAM_ADAS_CDSMaster_ISA 1000;
BA_ "InvalidValue" SG_ 853 FCAM_ADAS_CDSMaster_ISA "3h";
BA_ "GenSigSendType" SG_ 853 FCAM_ADAS_CDSMaster_TSR 2;
BA_ "GenSigTimeoutTime_ALL" SG_ 853 FCAM_ADAS_CDSMaster_TSR 1000;
BA_ "InvalidValue" SG_ 853 FCAM_ADAS_CDSMaster_TSR "3h";
BA_ "GenSigSendType" SG_ 853 FCAM_ADAS_CDSMaster_ACC 2;
BA_ "GenSigTimeoutTime_ALL" SG_ 853 FCAM_ADAS_CDSMaster_ACC 1000;
BA_ "InvalidValue" SG_ 853 FCAM_ADAS_CDSMaster_ACC "3h";
BA_ "GenSigSendType" SG_ 853 FCAM_ADAS_CDSMaster_TLD 2;
BA_ "GenSigTimeoutTime_ALL" SG_ 853 FCAM_ADAS_CDSMaster_TLD 1000;
BA_ "InvalidValue" SG_ 853 FCAM_ADAS_CDSMaster_TLD "3h";
BA_ "GenSigSendType" SG_ 853 FCAM_ADAS_CDSMaster_AACC 2;
BA_ "GenSigTimeoutTime_ALL" SG_ 853 FCAM_ADAS_CDSMaster_AACC 1000;
BA_ "InvalidValue" SG_ 853 FCAM_ADAS_CDSMaster_AACC "3h";
BA_ "GenSigSendType" SG_ 853 FCAM_ADAS_CDSMaster_ALCM 2;
BA_ "GenSigTimeoutTime_ALL" SG_ 853 FCAM_ADAS_CDSMaster_ALCM 1000;
BA_ "InvalidValue" SG_ 853 FCAM_ADAS_CDSMaster_ALCM "3h";
BA_ "GenSigSendType" SG_ 853 FCAM_ADAS_CDSMaster_AAESA 2;
BA_ "GenSigTimeoutTime_ALL" SG_ 853 FCAM_ADAS_CDSMaster_AAESA 1000;
BA_ "InvalidValue" SG_ 853 FCAM_ADAS_CDSMaster_AAESA "3h";
BA_ "GenSigSendType" SG_ 853 FCAM_ADAS_CDSMaster_ELK 2;
BA_ "GenSigTimeoutTime_ALL" SG_ 853 FCAM_ADAS_CDSMaster_ELK 1000;
BA_ "InvalidValue" SG_ 853 FCAM_ADAS_CDSMaster_ELK "3h";
BA_ "GenSigSendType" SG_ 853 FCAM_ADAS_CDSMaster_LKA 2;
BA_ "GenSigTimeoutTime_ALL" SG_ 853 FCAM_ADAS_CDSMaster_LKA 1000;
BA_ "InvalidValue" SG_ 853 FCAM_ADAS_CDSMaster_LKA "3h";
BA_ "GenSigSendType" SG_ 853 FCAM_ADAS_CDSMaster_LDW 2;
BA_ "GenSigTimeoutTime_ALL" SG_ 853 FCAM_ADAS_CDSMaster_LDW 1000;
BA_ "InvalidValue" SG_ 853 FCAM_ADAS_CDSMaster_LDW "3h";
BA_ "GenSigSendType" SG_ 853 FCAM_ADAS_CDSMaster_DNS 2;
BA_ "GenSigTimeoutTime_ALL" SG_ 853 FCAM_ADAS_CDSMaster_DNS 1000;
BA_ "InvalidValue" SG_ 853 FCAM_ADAS_CDSMaster_DNS "3h";
BA_ "GenSigSendType" SG_ 853 FCAM_ADAS_CDSMaster_FCW 2;
BA_ "GenSigTimeoutTime_ALL" SG_ 853 FCAM_ADAS_CDSMaster_FCW 1000;
BA_ "InvalidValue" SG_ 853 FCAM_ADAS_CDSMaster_FCW "3h";
BA_ "GenSigSendType" SG_ 853 FCAM_ADAS_CDSMaster_RAEB 2;
BA_ "GenSigTimeoutTime_ALL" SG_ 853 FCAM_ADAS_CDSMaster_RAEB 1000;
BA_ "InvalidValue" SG_ 853 FCAM_ADAS_CDSMaster_RAEB "3h";
BA_ "GenSigSendType" SG_ 853 FCAM_ADAS_CDSMaster_ESA 2;
BA_ "GenSigTimeoutTime_ALL" SG_ 853 FCAM_ADAS_CDSMaster_ESA 1000;
BA_ "InvalidValue" SG_ 853 FCAM_ADAS_CDSMaster_ESA "3h";
BA_ "GenSigSendType" SG_ 853 FCAM_ADAS_CDSMaster_FAEB 2;
BA_ "GenSigTimeoutTime_ALL" SG_ 853 FCAM_ADAS_CDSMaster_FAEB 1000;
BA_ "InvalidValue" SG_ 853 FCAM_ADAS_CDSMaster_FAEB "3h";
BA_ "GenSigSendType" SG_ 853 FCAM_ADAS_CDSMaster_RPA 2;
BA_ "GenSigTimeoutTime_ALL" SG_ 853 FCAM_ADAS_CDSMaster_RPA 1000;
BA_ "InvalidValue" SG_ 853 FCAM_ADAS_CDSMaster_RPA "3h";
BA_ "GenSigSendType" SG_ 853 FCAM_ADAS_CDSMaster_FPA 2;
BA_ "GenSigTimeoutTime_ALL" SG_ 853 FCAM_ADAS_CDSMaster_FPA 1000;
BA_ "InvalidValue" SG_ 853 FCAM_ADAS_CDSMaster_FPA "3h";
BA_ "GenSigSendType" SG_ 853 FCAM_ADAS_CDSMaster_RVC 2;
BA_ "GenSigTimeoutTime_ALL" SG_ 853 FCAM_ADAS_CDSMaster_RVC 1000;
BA_ "InvalidValue" SG_ 853 FCAM_ADAS_CDSMaster_RVC "3h";
BA_ "GenSigSendType" SG_ 853 FCAM_ADAS_CDSMaster_SVM 2;
BA_ "GenSigTimeoutTime_ALL" SG_ 853 FCAM_ADAS_CDSMaster_SVM 1000;
BA_ "InvalidValue" SG_ 853 FCAM_ADAS_CDSMaster_SVM "3h";
BA_ "GenSigSendType" SG_ 853 FCAM_ADAS_CDSMaster_VParkingComf 2;
BA_ "GenSigTimeoutTime_ALL" SG_ 853 FCAM_ADAS_CDSMaster_VParkingComf 1000;
BA_ "InvalidValue" SG_ 853 FCAM_ADAS_CDSMaster_VParkingComf "3h";
BA_ "SystemSignalLongSymbol" SG_ 853 FCAM_ADAS_CDSMaster_VParkingComf "FCAM_ADAS_CDSMaster_VParkingComfort";
BA_ "GenSigSendType" SG_ 853 FCAM_ADAS_CDSMaster_VParkingSele 2;
BA_ "GenSigTimeoutTime_ALL" SG_ 853 FCAM_ADAS_CDSMaster_VParkingSele 1000;
BA_ "InvalidValue" SG_ 853 FCAM_ADAS_CDSMaster_VParkingSele "3h";
BA_ "SystemSignalLongSymbol" SG_ 853 FCAM_ADAS_CDSMaster_VParkingSele "FCAM_ADAS_CDSMaster_VParkingSelect";
BA_ "GenSigSendType" SG_ 853 FCAM_ADAS_CDSMaster_RP 2;
BA_ "GenSigTimeoutTime_ALL" SG_ 853 FCAM_ADAS_CDSMaster_RP 1000;
BA_ "InvalidValue" SG_ 853 FCAM_ADAS_CDSMaster_RP "3h";
BA_ "GenSigSendType" SG_ 853 FCAM_ADAS_CDSMaster_SpaFAPA 2;
BA_ "GenSigTimeoutTime_ALL" SG_ 853 FCAM_ADAS_CDSMaster_SpaFAPA 1000;
BA_ "InvalidValue" SG_ 853 FCAM_ADAS_CDSMaster_SpaFAPA "3h";
BA_ "GenSigSendType" SG_ 853 FCAM_ADAS_CDSMaster_ADB 2;
BA_ "GenSigTimeoutTime_ALL" SG_ 853 FCAM_ADAS_CDSMaster_ADB 1000;
BA_ "InvalidValue" SG_ 853 FCAM_ADAS_CDSMaster_ADB "3h";
BA_ "GenSigSendType" SG_ 853 FCAM_ADAS_CDSMaster_AHB 2;
BA_ "GenSigTimeoutTime_ALL" SG_ 853 FCAM_ADAS_CDSMaster_AHB 1000;
BA_ "InvalidValue" SG_ 853 FCAM_ADAS_CDSMaster_AHB "3h";
BA_ "GenSigSendType" SG_ 853 FCAM_ADAS_CDSMaster_VParkingAuto 2;
BA_ "GenSigTimeoutTime_ALL" SG_ 853 FCAM_ADAS_CDSMaster_VParkingAuto 1000;
BA_ "InvalidValue" SG_ 853 FCAM_ADAS_CDSMaster_VParkingAuto "3h";
BA_ "SystemSignalLongSymbol" SG_ 853 FCAM_ADAS_CDSMaster_VParkingAuto "FCAM_ADAS_CDSMaster_VParkingAutoReverse";
BA_ "GenSigSendType" SG_ 853 FCAM_ADAS_CDSMaster_VParkingSumm 2;
BA_ "GenSigTimeoutTime_ALL" SG_ 853 FCAM_ADAS_CDSMaster_VParkingSumm 1000;
BA_ "InvalidValue" SG_ 853 FCAM_ADAS_CDSMaster_VParkingSumm "3h";
BA_ "SystemSignalLongSymbol" SG_ 853 FCAM_ADAS_CDSMaster_VParkingSumm "FCAM_ADAS_CDSMaster_VParkingSummon";
BA_ "GenSigSendType" SG_ 853 FCAM_ADAS_CDSMaster_AdasEDR 2;
BA_ "GenSigTimeoutTime_ALL" SG_ 853 FCAM_ADAS_CDSMaster_AdasEDR 1000;
BA_ "InvalidValue" SG_ 853 FCAM_ADAS_CDSMaster_AdasEDR "3h";
BA_ "GenSigSendType" SG_ 853 FCAM_ADAS_CDSMaster_DCM 2;
BA_ "GenSigTimeoutTime_ALL" SG_ 853 FCAM_ADAS_CDSMaster_DCM 1000;
BA_ "InvalidValue" SG_ 853 FCAM_ADAS_CDSMaster_DCM "3h";
BA_ "GenSigSendType" SG_ 853 FCAM_ADAS_CDSMaster_DMSFaceID 2;
BA_ "GenSigTimeoutTime_ALL" SG_ 853 FCAM_ADAS_CDSMaster_DMSFaceID 1000;
BA_ "InvalidValue" SG_ 853 FCAM_ADAS_CDSMaster_DMSFaceID "3h";
BA_ "GenSigSendType" SG_ 853 FCAM_ADAS_CDSMaster_DMS 2;
BA_ "GenSigTimeoutTime_ALL" SG_ 853 FCAM_ADAS_CDSMaster_DMS 1000;
BA_ "InvalidValue" SG_ 853 FCAM_ADAS_CDSMaster_DMS "3h";
BA_ "GenSigSendType" SG_ 853 FCAM_ADAS_CDSMaster_L2_L2PLUS 2;
BA_ "GenSigTimeoutTime_ALL" SG_ 853 FCAM_ADAS_CDSMaster_L2_L2PLUS 1000;
BA_ "InvalidValue" SG_ 853 FCAM_ADAS_CDSMaster_L2_L2PLUS "3h";
BA_ "GenSigSendType" SG_ 853 FCAM_ADAS_CDSMaster_SentryMode 2;
BA_ "GenSigTimeoutTime_ALL" SG_ 853 FCAM_ADAS_CDSMaster_SentryMode 1000;
BA_ "InvalidValue" SG_ 853 FCAM_ADAS_CDSMaster_SentryMode "3h";
BA_ "GenSigSendType" SG_ 853 FCAM_ADAS_CDSMaster_ACPE 2;
BA_ "GenSigTimeoutTime_ALL" SG_ 853 FCAM_ADAS_CDSMaster_ACPE 1000;
BA_ "InvalidValue" SG_ 853 FCAM_ADAS_CDSMaster_ACPE "3h";
BA_ "GenSigSendType" SG_ 1970 FCAM_C_Req_RandomData 2;
BA_ "GenSigSendType" SG_ 1970 FCAM_C_Req_MAC 2;
BA_ "InvalidValue" SG_ 311 ALIVE_EAS_CDC_WorkState "Fh";
BA_ "GenSigStartValue" SG_ 311 EAS_SuspensionMode 1;
BA_ "InvalidValue" SG_ 311 EAS_ValveValue_FL "7h";
BA_ "InvalidValue" SG_ 311 EAS_ValveValue_FR "7h";
BA_ "InvalidValue" SG_ 311 EAS_ValveValue_RL "7h";
BA_ "InvalidValue" SG_ 311 EAS_ValveValue_RR "7h";
BA_ "InvalidValue" SG_ 311 EAS_LiftModFb "3h";
BA_ "GenSigTimeoutTime_ALL" SG_ 555 CRC_ADCU_FCAM_ActuatorReq 50;
BA_ "GenSigTimeoutTime_ALL" SG_ 555 ALIVE_ADCU_FCAM_ActuatorReq 50;
BA_ "InvalidValue" SG_ 555 ALIVE_ADCU_FCAM_ActuatorReq "Fh";
BA_ "GenSigTimeoutTime_ALL" SG_ 555 ADCU_ACC_AccelDecel_Cmd 50;
BA_ "GenSigTimeoutTime_ALL" SG_ 555 ADCU_ACC_IDB_DecCmdAct 50;
BA_ "GenSigTimeoutTime_ALL" SG_ 555 ADCU_ACC_StandstillReq 50;
BA_ "GenSigTimeoutTime_ALL" SG_ 555 ADCU_ACC_Information 50;
BA_ "GenSigTimeoutTime_ALL" SG_ 555 ADCU_ACC_DriveOff 50;
BA_ "GenSigTimeoutTime_ALL" SG_ 555 ADCU_EPS_AOLReq 50;
BA_ "GenSigTimeoutTime_ALL" SG_ 555 ADCU_EPS_StrWhe_AOLAct 50;
BA_ "GenSigTimeoutTime_ALL" SG_ 555 ADCU_EPS_StrWhe_TOLAct 50;
BA_ "GenSigTimeoutTime_ALL" SG_ 555 ADCU_EPS_Torq_Fact_Req 50;
BA_ "GenSigTimeoutTime_ALL" SG_ 555 ADCU_LSS_Activation 50;
BA_ "GenSigTimeoutTime_ALL" SG_ 555 ADCU_LSS_Activation_2 50;
BA_ "GenSigTimeoutTime_ALL" SG_ 555 ADCU_NOP_state 50;
BA_ "GenSigTimeoutTime_ALL" SG_ 678 ALIVE_ADCU_FCAM_MM_Info 100;
BA_ "GenSigTimeoutTime_ALL" SG_ 678 CRC_ADCU_FCAM_MM_Info 100;
BA_ "InvalidValue" SG_ 678 CRC_ADCU_FCAM_MM_Info "Fh";
BA_ "GenSigTimeoutTime_ALL" SG_ 678 ADCU_FCAM_MM_State 100;
BA_ "InvalidValue" SG_ 678 ADCU_FCAM_MM_State "0h";
BA_ "GenSigTimeoutTime_ALL" SG_ 678 ADCU_FCAM_MM_Status 100;
BA_ "InvalidValue" SG_ 678 ADCU_FCAM_MM_Status "0h";
BA_ "GenSigTimeoutTime_ALL" SG_ 678 ADCU_FCAM_MM_ODD 100;
BA_ "InvalidValue" SG_ 678 ADCU_FCAM_MM_ODD "0h";
BA_ "GenSigTimeoutTime_ALL" SG_ 678 ADCU_FCAM_MM_VAP_State 100;
BA_ "InvalidValue" SG_ 678 ADCU_FCAM_MM_VAP_State "0h";
BA_ "GenSigTimeoutTime_ALL" SG_ 678 ADCU_FCAM_MM_NOP_State 100;
BA_ "InvalidValue" SG_ 678 ADCU_FCAM_MM_NOP_State "0h";
BA_ "GenSigTimeoutTime_ALL" SG_ 678 ADCU_FCAM_MM_HWA_State 100;
BA_ "InvalidValue" SG_ 678 ADCU_FCAM_MM_HWA_State "0h";
BA_ "GenSigTimeoutTime_ALL" SG_ 678 ADCU_FCAM_MM_ACC_State 100;
BA_ "InvalidValue" SG_ 678 ADCU_FCAM_MM_ACC_State "0h";
BA_ "GenSigTimeoutTime_ALL" SG_ 678 ADCU_FCAM_MM_OnChanging 100;
BA_ "InvalidValue" SG_ 678 ADCU_FCAM_MM_OnChanging "0h";
BA_ "GenSigTimeoutTime_ALL" SG_ 678 ADCU_NOP_Ctrl 100;
BA_ "InvalidValue" SG_ 678 ADCU_NOP_Ctrl "0h";
BA_ "GenSigTimeoutTime_ALL" SG_ 693 ALIVE_FCAM_ADCU_MM_Info 100;
BA_ "GenSigTimeoutTime_ALL" SG_ 693 CRC_FCAM_ADCU_MM_Info 100;
BA_ "InvalidValue" SG_ 693 CRC_FCAM_ADCU_MM_Info "Fh";
BA_ "GenSigTimeoutTime_ALL" SG_ 693 FCAM_ADCU_MM_State 100;
BA_ "InvalidValue" SG_ 693 FCAM_ADCU_MM_State "0h";
BA_ "GenSigTimeoutTime_ALL" SG_ 693 FCAM_ADCU_MM_Status 100;
BA_ "InvalidValue" SG_ 693 FCAM_ADCU_MM_Status "0h";
BA_ "GenSigTimeoutTime_ALL" SG_ 693 FCAM_ADCU_MM_ODD 100;
BA_ "InvalidValue" SG_ 693 FCAM_ADCU_MM_ODD "0h";
BA_ "GenSigTimeoutTime_ALL" SG_ 693 FCAM_ADCU_MM_VAP_State 100;
BA_ "InvalidValue" SG_ 693 FCAM_ADCU_MM_VAP_State "0h";
BA_ "GenSigTimeoutTime_ALL" SG_ 693 FCAM_ADCU_MM_NOP_State 100;
BA_ "InvalidValue" SG_ 693 FCAM_ADCU_MM_NOP_State "0h";
BA_ "GenSigTimeoutTime_ALL" SG_ 693 FCAM_ADCU_MM_HWA_State 100;
BA_ "InvalidValue" SG_ 693 FCAM_ADCU_MM_HWA_State "0h";
BA_ "GenSigTimeoutTime_ALL" SG_ 693 FCAM_ADCU_MM_ACC_State 100;
BA_ "InvalidValue" SG_ 693 FCAM_ADCU_MM_ACC_State "0h";
BA_ "GenSigTimeoutTime_ALL" SG_ 693 FCAM_ADCU_MM_OnChanging 100;
BA_ "InvalidValue" SG_ 693 FCAM_ADCU_MM_OnChanging "0h";
BA_ "GenSigTimeoutTime_ALL" SG_ 821 CRC_ADCU_AEB_Status 200;
BA_ "GenSigTimeoutTime_ALL" SG_ 821 ALIVE_ADCU_AEB_Status 200;
BA_ "InvalidValue" SG_ 821 ALIVE_ADCU_AEB_Status "Fh";
BA_ "GenSigTimeoutTime_ALL" SG_ 821 ADCU_AEB_Prefill 200;
BA_ "GenSigTimeoutTime_ALL" SG_ 821 ADCU_AEB_HBA_Level 200;
BA_ "GenSigTimeoutTime_ALL" SG_ 821 ADCU_AEB_Target_Deceleration 200;
BA_ "GenSigTimeoutTime_ALL" SG_ 821 ADCU_AEB_HBA_Req 200;
BA_ "GenSigTimeoutTime_ALL" SG_ 821 ADCU_AEB_Braking_Progress 200;
BA_ "GenSigTimeoutTime_ALL" SG_ 821 ADCU_AEB_Hold 200;
BA_ "GenSigTimeoutTime_ALL" SG_ 821 ADCU_AEB_DBS_Active 200;
BA_ "GenSigTimeoutTime_ALL" SG_ 470 ADCU_TSR_SLWSwtResp 100;
BA_ "GenSigTimeoutTime_ALL" SG_ 470 ADCU_FC_CalibrationSts 100;
BA_ "GenSigTimeoutTime_ALL" SG_ 470 ADCU_BlockageSts 100;
BA_ "GenSigTimeoutTime_ALL" SG_ 470 ADCU_AEB_ABA_Req 100;
BA_ "GenSigTimeoutTime_ALL" SG_ 470 ADCU_AEB_AWB_Req 100;
BA_ "GenSigTimeoutTime_ALL" SG_ 470 ADCU_AEB_TgtDecel_Req 100;
BA_ "GenSigTimeoutTime_ALL" SG_ 470 ADCU_AEB_VehHldReq 100;
BA_ "GenSigTimeoutTime_ALL" SG_ 470 ADCU_AEB_AWB_Level 100;
BA_ "GenSigTimeoutTime_ALL" SG_ 470 ADCU_ACC_AdtUpperJerkLimit 100;
BA_ "GenSigTimeoutTime_ALL" SG_ 470 ADCU_ACC_AdtLowerJerkLimit 100;
BA_ "GenSigTimeoutTime_ALL" SG_ 472 CRC_ADCU_FCAM_Handshake 100;
BA_ "GenSigTimeoutTime_ALL" SG_ 472 ALIVE_ADCU_FCAM_Handshake 100;
BA_ "InvalidValue" SG_ 472 ALIVE_ADCU_FCAM_Handshake "Fh";
BA_ "GenSigTimeoutTime_ALL" SG_ 472 ADCU_FCAM_Alive_Distinguish 100;
BA_ "GenSigTimeoutTime_ALL" SG_ 472 ADCU_FCAM_CONTROL_SOURCE 100;
BA_ "InvalidValue" SG_ 472 ADCU_FCAM_CONTROL_SOURCE "3h";
BA_ "GenSigTimeoutTime_ALL" SG_ 313 CRC_ADCU_LSS_EPS_REQUEST 200;
BA_ "GenSigTimeoutTime_ALL" SG_ 313 ALIVE_ADCU_LSS_EPS_REQUEST 200;
BA_ "InvalidValue" SG_ 313 ALIVE_ADCU_LSS_EPS_REQUEST "Fh";
BA_ "GenSigTimeoutTime_ALL" SG_ 313 ADCU_LSS_Activation_3 200;
BA_ "InvalidValue" SG_ 313 ADCU_LSS_Activation_3 "7h";
BA_ "GenSigTimeoutTime_ALL" SG_ 313 ADCU_LSS_Activation_4 200;
BA_ "InvalidValue" SG_ 313 ADCU_LSS_Activation_4 "7h";
BA_ "GenSigTimeoutTime_ALL" SG_ 589 CRC_ADCU_BRAKE_CMD 100;
BA_ "GenSigTimeoutTime_ALL" SG_ 589 ALIVE_ADCU_BRAKE_CMD 100;
BA_ "InvalidValue" SG_ 589 ALIVE_ADCU_BRAKE_CMD "Fh";
BA_ "GenSigTimeoutTime_ALL" SG_ 589 ADCU_RAEB_BrakeCommand 100;
BA_ "InvalidValue" SG_ 589 ADCU_RAEB_BrakeCommand "3h";
BA_ "GenSigTimeoutTime_ALL" SG_ 589 ADCU_RAEB_Available 100;
BA_ "GenSigStartValue" SG_ 589 ADCU_RAEB_Available 3;
BA_ "InvalidValue" SG_ 589 ADCU_RAEB_Available "3h";
BA_ "GenSigTimeoutTime_ALL" SG_ 589 ADCU_RAEB_FuncActive 100;
BA_ "GenSigTimeoutTime_ALL" SG_ 589 ADCU_RAEB_BrakeType 100;
BA_ "GenSigTimeoutTime_ALL" SG_ 589 ADCU_RAEB_PullEPBOpt 100;
BA_ "GenSigTimeoutTime_ALL" SG_ 640 CRC_ADCU_VAP_Status 200;
BA_ "GenSigTimeoutTime_ALL" SG_ 640 ALIVE_ADCU_VAP_Status 200;
BA_ "InvalidValue" SG_ 640 ALIVE_ADCU_VAP_Status "Fh";
BA_ "GenSigTimeoutTime_ALL" SG_ 640 ADCU_VAP_Status_Mode 200;
BA_ "InvalidValue" SG_ 640 ADCU_VAP_Status_Mode "Fh";
BA_ "GenSigTimeoutTime_ALL" SG_ 640 ADCU_VAP_Status_ModeExt 200;
BA_ "InvalidValue" SG_ 640 ADCU_VAP_Status_ModeExt "Fh";
BA_ "GenSigTimeoutTime_ALL" SG_ 640 ADCU_VAP_Status_State 200;
BA_ "InvalidValue" SG_ 640 ADCU_VAP_Status_State "Dh";
BA_ "GenSigTimeoutTime_ALL" SG_ 640 ADCU_VAP_Status_Status 200;
BA_ "InvalidValue" SG_ 640 ADCU_VAP_Status_Status "Fh";
BA_ "GenSigTimeoutTime_ALL" SG_ 640 ADCU_VAP_Status_StatusExt 200;
BA_ "InvalidValue" SG_ 640 ADCU_VAP_Status_StatusExt "Fh";
BA_ "GenSigTimeoutTime_ALL" SG_ 640 ADCU_VAP_Status_CVCStat 200;
BA_ "InvalidValue" SG_ 640 ADCU_VAP_Status_CVCStat "3h";
BA_ "GenSigTimeoutTime_ALL" SG_ 640 ADCU_VAP_Status_BCMStat 200;
BA_ "InvalidValue" SG_ 640 ADCU_VAP_Status_BCMStat "3h";
BA_ "GenSigTimeoutTime_ALL" SG_ 640 ADCU_VAP_Status_EPSStat 200;
BA_ "InvalidValue" SG_ 640 ADCU_VAP_Status_EPSStat "3h";
BA_ "GenSigTimeoutTime_ALL" SG_ 640 ADCU_VAP_Status_WCBSStat 200;
BA_ "InvalidValue" SG_ 640 ADCU_VAP_Status_WCBSStat "3h";
BA_ "GenSigTimeoutTime_ALL" SG_ 640 ADCU_VAP_Status_MHUStat 200;
BA_ "InvalidValue" SG_ 640 ADCU_VAP_Status_MHUStat "3h";
BA_ "GenSigTimeoutTime_ALL" SG_ 640 ADCU_VAP_Status_TboxStat 200;
BA_ "InvalidValue" SG_ 640 ADCU_VAP_Status_TboxStat "3h";
BA_ "GenSigTimeoutTime_ALL" SG_ 640 ADCU_VAP_Status_DKCUStat 200;
BA_ "InvalidValue" SG_ 640 ADCU_VAP_Status_DKCUStat "3h";
BA_ "GenSigTimeoutTime_ALL" SG_ 640 ADCU_VAP_Status_CappStat 200;
BA_ "InvalidValue" SG_ 640 ADCU_VAP_Status_CappStat "3h";
BA_ "GenSigTimeoutTime_ALL" SG_ 641 CRC_ADCU_WCBS_VAP_Control 100;
BA_ "GenSigTimeoutTime_ALL" SG_ 641 ALIVE_ADCU_WCBS_VAP_Control 100;
BA_ "InvalidValue" SG_ 641 ALIVE_ADCU_WCBS_VAP_Control "Fh";
BA_ "GenSigTimeoutTime_ALL" SG_ 641 ADCU_WCBS_VAP_Mode 100;
BA_ "InvalidValue" SG_ 641 ADCU_WCBS_VAP_Mode "Fh";
BA_ "GenSigTimeoutTime_ALL" SG_ 641 ADCU_WCBS_VAP_State 100;
BA_ "InvalidValue" SG_ 641 ADCU_WCBS_VAP_State "Dh";
BA_ "GenSigTimeoutTime_ALL" SG_ 641 ADCU_WCBS_VAP_ControlReq 100;
BA_ "InvalidValue" SG_ 641 ADCU_WCBS_VAP_ControlReq "0h";
BA_ "GenSigTimeoutTime_ALL" SG_ 641 ADCU_WCBS_VAP_BrakeModeReq 100;
BA_ "InvalidValue" SG_ 641 ADCU_WCBS_VAP_BrakeModeReq "3h";
BA_ "GenSigTimeoutTime_ALL" SG_ 641 ADCU_WCBS_VAP_StopReq 100;
BA_ "InvalidValue" SG_ 641 ADCU_WCBS_VAP_StopReq "0h";
BA_ "GenSigTimeoutTime_ALL" SG_ 641 ADCU_WCBS_VAP_EPBReq 100;
BA_ "InvalidValue" SG_ 641 ADCU_WCBS_VAP_EPBReq "0h";
BA_ "GenSigTimeoutTime_ALL" SG_ 641 ADCU_WCBS_VAP_TarAccDecReq 100;
BA_ "InvalidValue" SG_ 641 ADCU_WCBS_VAP_TarAccDecReq "3FFh";
BA_ "GenSigTimeoutTime_ALL" SG_ 642 CRC_ADCU_CVC_VAP_Control 100;
BA_ "GenSigTimeoutTime_ALL" SG_ 642 ALIVE_ADCU_CVC_VAP_Control 100;
BA_ "InvalidValue" SG_ 642 ALIVE_ADCU_CVC_VAP_Control "Fh";
BA_ "GenSigTimeoutTime_ALL" SG_ 642 ADCU_CVC_VAP_Mode 100;
BA_ "InvalidValue" SG_ 642 ADCU_CVC_VAP_Mode "Fh";
BA_ "GenSigTimeoutTime_ALL" SG_ 642 ADCU_CVC_VAP_State 100;
BA_ "InvalidValue" SG_ 642 ADCU_CVC_VAP_State "Dh";
BA_ "GenSigTimeoutTime_ALL" SG_ 642 ADCU_CVC_VAP_ControlReq 100;
BA_ "InvalidValue" SG_ 642 ADCU_CVC_VAP_ControlReq "0h";
BA_ "GenSigTimeoutTime_ALL" SG_ 642 ADCU_CVC_VAP_GearReq 100;
BA_ "InvalidValue" SG_ 642 ADCU_CVC_VAP_GearReq "0h";
BA_ "GenSigTimeoutTime_ALL" SG_ 642 ADCU_BCM_VAP_ControlReq 100;
BA_ "InvalidValue" SG_ 642 ADCU_BCM_VAP_ControlReq "0h";
BA_ "GenSigTimeoutTime_ALL" SG_ 642 ADCU_BCM_VAP_LightReq 100;
BA_ "InvalidValue" SG_ 642 ADCU_BCM_VAP_LightReq "0h";
BA_ "GenSigTimeoutTime_ALL" SG_ 642 ADCU_BCM_VAP_Lights 100;
BA_ "InvalidValue" SG_ 642 ADCU_BCM_VAP_Lights "3h";
BA_ "GenSigTimeoutTime_ALL" SG_ 642 ADCU_BCM_VAP_IndicatorLightReq 100;
BA_ "InvalidValue" SG_ 642 ADCU_BCM_VAP_IndicatorLightReq "0h";
BA_ "GenSigTimeoutTime_ALL" SG_ 642 ADCU_BCM_VAP_IndicatorLights 100;
BA_ "InvalidValue" SG_ 642 ADCU_BCM_VAP_IndicatorLights "3h";
BA_ "GenSigTimeoutTime_ALL" SG_ 642 ADCU_BCM_VAP_MirrorReq 100;
BA_ "InvalidValue" SG_ 642 ADCU_BCM_VAP_MirrorReq "0h";
BA_ "GenSigTimeoutTime_ALL" SG_ 642 ADCU_BCM_VAP_Mirrors 100;
BA_ "InvalidValue" SG_ 642 ADCU_BCM_VAP_Mirrors "3h";
BA_ "GenSigTimeoutTime_ALL" SG_ 642 ADCU_BCM_VAP_WindowReq 100;
BA_ "InvalidValue" SG_ 642 ADCU_BCM_VAP_WindowReq "0h";
BA_ "GenSigTimeoutTime_ALL" SG_ 642 ADCU_BCM_VAP_Windows 100;
BA_ "InvalidValue" SG_ 642 ADCU_BCM_VAP_Windows "3h";
BA_ "GenSigTimeoutTime_ALL" SG_ 642 ADCU_BCM_VAP_DoorReq 100;
BA_ "InvalidValue" SG_ 642 ADCU_BCM_VAP_DoorReq "0h";
BA_ "GenSigTimeoutTime_ALL" SG_ 642 ADCU_BCM_VAP_Doors 100;
BA_ "InvalidValue" SG_ 642 ADCU_BCM_VAP_Doors "3h";
BA_ "GenSigTimeoutTime_ALL" SG_ 642 ADCU_BCM_VAP_TrunkReq 100;
BA_ "InvalidValue" SG_ 642 ADCU_BCM_VAP_TrunkReq "0h";
BA_ "GenSigTimeoutTime_ALL" SG_ 642 ADCU_BCM_VAP_HornReq 100;
BA_ "InvalidValue" SG_ 642 ADCU_BCM_VAP_HornReq "0h";
BA_ "GenSigTimeoutTime_ALL" SG_ 642 ADCU_CVC_VAP_GearPosReq 100;
BA_ "InvalidValue" SG_ 642 ADCU_CVC_VAP_GearPosReq "7h";
BA_ "GenSigTimeoutTime_ALL" SG_ 643 CRC_ADCU_EPS_VAP_Control 100;
BA_ "GenSigTimeoutTime_ALL" SG_ 643 ALIVE_ADCU_EPS_VAP_Control 100;
BA_ "InvalidValue" SG_ 643 ALIVE_ADCU_EPS_VAP_Control "Fh";
BA_ "GenSigTimeoutTime_ALL" SG_ 643 ADCU_EPS_VAP_Mode 100;
BA_ "InvalidValue" SG_ 643 ADCU_EPS_VAP_Mode "Fh";
BA_ "GenSigTimeoutTime_ALL" SG_ 643 ADCU_EPS_VAP_State 100;
BA_ "InvalidValue" SG_ 643 ADCU_EPS_VAP_State "Dh";
BA_ "GenSigTimeoutTime_ALL" SG_ 643 ADCU_EPS_VAP_ControlReq 100;
BA_ "InvalidValue" SG_ 643 ADCU_EPS_VAP_ControlReq "0h";
BA_ "GenSigTimeoutTime_ALL" SG_ 643 ADCU_EPS_VAP_SteeringTorqueReq 100;
BA_ "InvalidValue" SG_ 643 ADCU_EPS_VAP_SteeringTorqueReq "0h";
BA_ "GenSigTimeoutTime_ALL" SG_ 643 ADCU_EPS_VAP_SteeringAngleReq 100;
BA_ "InvalidValue" SG_ 643 ADCU_EPS_VAP_SteeringAngleReq "0h";
BA_ "GenSigTimeoutTime_ALL" SG_ 1282 CVC_srcNodeID 2000;
BA_ "InvalidValue" SG_ 1282 CVC_srcNodeID "FFh";
BA_ "GenSigTimeoutTime_ALL" SG_ 1282 CVC_CtrlBitVector 2000;
BA_ "GenSigTimeoutTime_ALL" SG_ 1282 CVC_usrData0 2000;
BA_ "GenSigStartValue" SG_ 1282 CVC_usrData0 255;
BA_ "GenSigTimeoutTime_ALL" SG_ 1282 CVC_usrData1 2000;
BA_ "GenSigStartValue" SG_ 1282 CVC_usrData1 255;
BA_ "GenSigTimeoutTime_ALL" SG_ 1282 CVC_usrData2 2000;
BA_ "GenSigStartValue" SG_ 1282 CVC_usrData2 255;
BA_ "GenSigTimeoutTime_ALL" SG_ 1282 CVC_usrData3 2000;
BA_ "GenSigStartValue" SG_ 1282 CVC_usrData3 255;
BA_ "GenSigTimeoutTime_ALL" SG_ 1282 CVC_usrData4 2000;
BA_ "GenSigStartValue" SG_ 1282 CVC_usrData4 255;
BA_ "GenSigTimeoutTime_ALL" SG_ 1282 CVC_usrData5 2000;
BA_ "GenSigStartValue" SG_ 1282 CVC_usrData5 255;
BA_ "GenSigTimeoutTime_ALL" SG_ 1320 EPS_srcNodeID 2000;
BA_ "InvalidValue" SG_ 1320 EPS_srcNodeID "FFh";
BA_ "GenSigTimeoutTime_ALL" SG_ 1320 EPS_CtrlBitVector 2000;
BA_ "GenSigTimeoutTime_ALL" SG_ 1320 EPS_usrData0 2000;
BA_ "GenSigStartValue" SG_ 1320 EPS_usrData0 255;
BA_ "GenSigTimeoutTime_ALL" SG_ 1320 EPS_usrData1 2000;
BA_ "GenSigStartValue" SG_ 1320 EPS_usrData1 255;
BA_ "GenSigTimeoutTime_ALL" SG_ 1320 EPS_usrData2 2000;
BA_ "GenSigStartValue" SG_ 1320 EPS_usrData2 255;
BA_ "GenSigTimeoutTime_ALL" SG_ 1320 EPS_usrData3 2000;
BA_ "GenSigStartValue" SG_ 1320 EPS_usrData3 255;
BA_ "GenSigTimeoutTime_ALL" SG_ 1320 EPS_usrData4 2000;
BA_ "GenSigStartValue" SG_ 1320 EPS_usrData4 255;
BA_ "GenSigTimeoutTime_ALL" SG_ 1320 EPS_usrData5 2000;
BA_ "GenSigStartValue" SG_ 1320 EPS_usrData5 255;
BA_ "GenSigTimeoutTime_ALL" SG_ 1321 WCBS_srcNodeID 2000;
BA_ "InvalidValue" SG_ 1321 WCBS_srcNodeID "FFh";
BA_ "GenSigTimeoutTime_ALL" SG_ 1321 WCBS_CtrlBitVector 2000;
BA_ "GenSigTimeoutTime_ALL" SG_ 1321 WCBS_usrData0 2000;
BA_ "GenSigStartValue" SG_ 1321 WCBS_usrData0 255;
BA_ "GenSigTimeoutTime_ALL" SG_ 1321 WCBS_usrData1 2000;
BA_ "GenSigStartValue" SG_ 1321 WCBS_usrData1 255;
BA_ "GenSigTimeoutTime_ALL" SG_ 1321 WCBS_usrData2 2000;
BA_ "GenSigStartValue" SG_ 1321 WCBS_usrData2 255;
BA_ "GenSigTimeoutTime_ALL" SG_ 1321 WCBS_usrData3 2000;
BA_ "GenSigStartValue" SG_ 1321 WCBS_usrData3 255;
BA_ "GenSigTimeoutTime_ALL" SG_ 1321 WCBS_usrData4 2000;
BA_ "GenSigStartValue" SG_ 1321 WCBS_usrData4 255;
BA_ "GenSigTimeoutTime_ALL" SG_ 1321 WCBS_usrData5 2000;
BA_ "GenSigStartValue" SG_ 1321 WCBS_usrData5 255;
BA_ "GenSigTimeoutTime_ALL" SG_ 1302 FCAM_srcNodeID 2000;
BA_ "InvalidValue" SG_ 1302 FCAM_srcNodeID "FFh";
BA_ "GenSigTimeoutTime_ALL" SG_ 1302 FCAM_CtrlBitVector 2000;
BA_ "GenSigTimeoutTime_ALL" SG_ 1302 FCAM_usrData0 2000;
BA_ "GenSigStartValue" SG_ 1302 FCAM_usrData0 255;
BA_ "GenSigTimeoutTime_ALL" SG_ 1302 FCAM_usrData1 2000;
BA_ "GenSigStartValue" SG_ 1302 FCAM_usrData1 255;
BA_ "GenSigTimeoutTime_ALL" SG_ 1302 FCAM_usrData2 2000;
BA_ "GenSigStartValue" SG_ 1302 FCAM_usrData2 255;
BA_ "GenSigTimeoutTime_ALL" SG_ 1302 FCAM_usrData3 2000;
BA_ "GenSigStartValue" SG_ 1302 FCAM_usrData3 255;
BA_ "GenSigTimeoutTime_ALL" SG_ 1302 FCAM_usrData4 2000;
BA_ "GenSigStartValue" SG_ 1302 FCAM_usrData4 255;
BA_ "GenSigTimeoutTime_ALL" SG_ 1302 FCAM_usrData5 2000;
BA_ "GenSigStartValue" SG_ 1302 FCAM_usrData5 255;
BA_ "GenSigTimeoutTime_ALL" SG_ 1344 ADCU_srcNodeID 2000;
BA_ "InvalidValue" SG_ 1344 ADCU_srcNodeID "FFh";
BA_ "GenSigTimeoutTime_ALL" SG_ 1344 ADCU_CtrlBitVector 2000;
BA_ "GenSigTimeoutTime_ALL" SG_ 1344 ADCU_usrData0 2000;
BA_ "GenSigTimeoutTime_ALL" SG_ 1344 ADCU_usrData1 2000;
BA_ "GenSigTimeoutTime_ALL" SG_ 1344 ADCU_usrData2 2000;
BA_ "GenSigTimeoutTime_ALL" SG_ 1344 ADCU_usrData3 2000;
BA_ "GenSigTimeoutTime_ALL" SG_ 1344 ADCU_usrData4 2000;
BA_ "GenSigTimeoutTime_ALL" SG_ 1344 ADCU_usrData5 2000;
BA_ "GenSigSendType" SG_ 1704 EPS_DiagReqData0 1;
BA_ "GenSigSendType" SG_ 1704 EPS_DiagReqData1 1;
BA_ "GenSigSendType" SG_ 1704 EPS_DiagReqData2 1;
BA_ "GenSigSendType" SG_ 1704 EPS_DiagReqData3 1;
BA_ "GenSigSendType" SG_ 1704 EPS_DiagReqData4 1;
BA_ "GenSigSendType" SG_ 1704 EPS_DiagReqData5 1;
BA_ "GenSigSendType" SG_ 1704 EPS_DiagReqData6 1;
BA_ "GenSigSendType" SG_ 1704 EPS_DiagReqData7 1;
BA_ "GenSigSendType" SG_ 1704 EPS_DiagReqData8 1;
BA_ "GenSigSendType" SG_ 1704 EPS_DiagReqData9 1;
BA_ "GenSigSendType" SG_ 1704 EPS_DiagReqData10 1;
BA_ "GenSigSendType" SG_ 1704 EPS_DiagReqData11 1;
BA_ "GenSigSendType" SG_ 1704 EPS_DiagReqData12 1;
BA_ "GenSigSendType" SG_ 1704 EPS_DiagReqData13 1;
BA_ "GenSigSendType" SG_ 1704 EPS_DiagReqData14 1;
BA_ "GenSigSendType" SG_ 1704 EPS_DiagReqData15 1;
BA_ "GenSigSendType" SG_ 1704 EPS_DiagReqData16 1;
BA_ "GenSigSendType" SG_ 1704 EPS_DiagReqData17 1;
BA_ "GenSigSendType" SG_ 1704 EPS_DiagReqData18 1;
BA_ "GenSigSendType" SG_ 1704 EPS_DiagReqData19 1;
BA_ "GenSigSendType" SG_ 1704 EPS_DiagReqData20 1;
BA_ "GenSigSendType" SG_ 1704 EPS_DiagReqData21 1;
BA_ "GenSigSendType" SG_ 1704 EPS_DiagReqData22 1;
BA_ "GenSigSendType" SG_ 1704 EPS_DiagReqData23 1;
BA_ "GenSigSendType" SG_ 1704 EPS_DiagReqData24 1;
BA_ "GenSigSendType" SG_ 1704 EPS_DiagReqData25 1;
BA_ "GenSigSendType" SG_ 1704 EPS_DiagReqData26 1;
BA_ "GenSigSendType" SG_ 1704 EPS_DiagReqData27 1;
BA_ "GenSigSendType" SG_ 1704 EPS_DiagReqData28 1;
BA_ "GenSigSendType" SG_ 1704 EPS_DiagReqData29 1;
BA_ "GenSigSendType" SG_ 1704 EPS_DiagReqData30 1;
BA_ "GenSigSendType" SG_ 1704 EPS_DiagReqData31 1;
BA_ "GenSigSendType" SG_ 1704 EPS_DiagReqData32 1;
BA_ "GenSigSendType" SG_ 1704 EPS_DiagReqData33 1;
BA_ "GenSigSendType" SG_ 1704 EPS_DiagReqData34 1;
BA_ "GenSigSendType" SG_ 1704 EPS_DiagReqData35 1;
BA_ "GenSigSendType" SG_ 1704 EPS_DiagReqData36 1;
BA_ "GenSigSendType" SG_ 1704 EPS_DiagReqData37 1;
BA_ "GenSigSendType" SG_ 1704 EPS_DiagReqData38 1;
BA_ "GenSigSendType" SG_ 1704 EPS_DiagReqData39 1;
BA_ "GenSigSendType" SG_ 1704 EPS_DiagReqData40 1;
BA_ "GenSigSendType" SG_ 1704 EPS_DiagReqData41 1;
BA_ "GenSigSendType" SG_ 1704 EPS_DiagReqData42 1;
BA_ "GenSigSendType" SG_ 1704 EPS_DiagReqData43 1;
BA_ "GenSigSendType" SG_ 1704 EPS_DiagReqData44 1;
BA_ "GenSigSendType" SG_ 1704 EPS_DiagReqData45 1;
BA_ "GenSigSendType" SG_ 1704 EPS_DiagReqData46 1;
BA_ "GenSigSendType" SG_ 1704 EPS_DiagReqData47 1;
BA_ "GenSigSendType" SG_ 1704 EPS_DiagReqData48 1;
BA_ "GenSigSendType" SG_ 1704 EPS_DiagReqData49 1;
BA_ "GenSigSendType" SG_ 1704 EPS_DiagReqData50 1;
BA_ "GenSigSendType" SG_ 1704 EPS_DiagReqData51 1;
BA_ "GenSigSendType" SG_ 1704 EPS_DiagReqData52 1;
BA_ "GenSigSendType" SG_ 1704 EPS_DiagReqData53 1;
BA_ "GenSigSendType" SG_ 1704 EPS_DiagReqData54 1;
BA_ "GenSigSendType" SG_ 1704 EPS_DiagReqData55 1;
BA_ "GenSigSendType" SG_ 1704 EPS_DiagReqData56 1;
BA_ "GenSigSendType" SG_ 1704 EPS_DiagReqData57 1;
BA_ "GenSigSendType" SG_ 1704 EPS_DiagReqData58 1;
BA_ "GenSigSendType" SG_ 1704 EPS_DiagReqData59 1;
BA_ "GenSigSendType" SG_ 1704 EPS_DiagReqData60 1;
BA_ "GenSigSendType" SG_ 1704 EPS_DiagReqData61 1;
BA_ "GenSigSendType" SG_ 1704 EPS_DiagReqData62 1;
BA_ "GenSigSendType" SG_ 1704 EPS_DiagReqData63 1;
BA_ "GenSigSendType" SG_ 1576 EPS_DiagRespData0 1;
BA_ "GenSigSendType" SG_ 1576 EPS_DiagRespData1 1;
BA_ "GenSigSendType" SG_ 1576 EPS_DiagRespData2 1;
BA_ "GenSigSendType" SG_ 1576 EPS_DiagRespData3 1;
BA_ "GenSigSendType" SG_ 1576 EPS_DiagRespData4 1;
BA_ "GenSigSendType" SG_ 1576 EPS_DiagRespData5 1;
BA_ "GenSigSendType" SG_ 1576 EPS_DiagRespData6 1;
BA_ "GenSigSendType" SG_ 1576 EPS_DiagRespData7 1;
BA_ "GenSigSendType" SG_ 1576 EPS_DiagRespData8 1;
BA_ "GenSigSendType" SG_ 1576 EPS_DiagRespData9 1;
BA_ "GenSigSendType" SG_ 1576 EPS_DiagRespData10 1;
BA_ "GenSigSendType" SG_ 1576 EPS_DiagRespData11 1;
BA_ "GenSigSendType" SG_ 1576 EPS_DiagRespData12 1;
BA_ "GenSigSendType" SG_ 1576 EPS_DiagRespData13 1;
BA_ "GenSigSendType" SG_ 1576 EPS_DiagRespData14 1;
BA_ "GenSigSendType" SG_ 1576 EPS_DiagRespData15 1;
BA_ "GenSigSendType" SG_ 1576 EPS_DiagRespData16 1;
BA_ "GenSigSendType" SG_ 1576 EPS_DiagRespData17 1;
BA_ "GenSigSendType" SG_ 1576 EPS_DiagRespData18 1;
BA_ "GenSigSendType" SG_ 1576 EPS_DiagRespData19 1;
BA_ "GenSigSendType" SG_ 1576 EPS_DiagRespData20 1;
BA_ "GenSigSendType" SG_ 1576 EPS_DiagRespData21 1;
BA_ "GenSigSendType" SG_ 1576 EPS_DiagRespData22 1;
BA_ "GenSigSendType" SG_ 1576 EPS_DiagRespData23 1;
BA_ "GenSigSendType" SG_ 1576 EPS_DiagRespData24 1;
BA_ "GenSigSendType" SG_ 1576 EPS_DiagRespData25 1;
BA_ "GenSigSendType" SG_ 1576 EPS_DiagRespData26 1;
BA_ "GenSigSendType" SG_ 1576 EPS_DiagRespData27 1;
BA_ "GenSigSendType" SG_ 1576 EPS_DiagRespData28 1;
BA_ "GenSigSendType" SG_ 1576 EPS_DiagRespData29 1;
BA_ "GenSigSendType" SG_ 1576 EPS_DiagRespData30 1;
BA_ "GenSigSendType" SG_ 1576 EPS_DiagRespData31 1;
BA_ "GenSigSendType" SG_ 1576 EPS_DiagRespData32 1;
BA_ "GenSigSendType" SG_ 1576 EPS_DiagRespData33 1;
BA_ "GenSigSendType" SG_ 1576 EPS_DiagRespData34 1;
BA_ "GenSigSendType" SG_ 1576 EPS_DiagRespData35 1;
BA_ "GenSigSendType" SG_ 1576 EPS_DiagRespData36 1;
BA_ "GenSigSendType" SG_ 1576 EPS_DiagRespData37 1;
BA_ "GenSigSendType" SG_ 1576 EPS_DiagRespData38 1;
BA_ "GenSigSendType" SG_ 1576 EPS_DiagRespData39 1;
BA_ "GenSigSendType" SG_ 1576 EPS_DiagRespData40 1;
BA_ "GenSigSendType" SG_ 1576 EPS_DiagRespData41 1;
BA_ "GenSigSendType" SG_ 1576 EPS_DiagRespData42 1;
BA_ "GenSigSendType" SG_ 1576 EPS_DiagRespData43 1;
BA_ "GenSigSendType" SG_ 1576 EPS_DiagRespData44 1;
BA_ "GenSigSendType" SG_ 1576 EPS_DiagRespData45 1;
BA_ "GenSigSendType" SG_ 1576 EPS_DiagRespData46 1;
BA_ "GenSigSendType" SG_ 1576 EPS_DiagRespData47 1;
BA_ "GenSigSendType" SG_ 1576 EPS_DiagRespData48 1;
BA_ "GenSigSendType" SG_ 1576 EPS_DiagRespData49 1;
BA_ "GenSigSendType" SG_ 1576 EPS_DiagRespData50 1;
BA_ "GenSigSendType" SG_ 1576 EPS_DiagRespData51 1;
BA_ "GenSigSendType" SG_ 1576 EPS_DiagRespData52 1;
BA_ "GenSigSendType" SG_ 1576 EPS_DiagRespData53 1;
BA_ "GenSigSendType" SG_ 1576 EPS_DiagRespData54 1;
BA_ "GenSigSendType" SG_ 1576 EPS_DiagRespData55 1;
BA_ "GenSigSendType" SG_ 1576 EPS_DiagRespData56 1;
BA_ "GenSigSendType" SG_ 1576 EPS_DiagRespData57 1;
BA_ "GenSigSendType" SG_ 1576 EPS_DiagRespData58 1;
BA_ "GenSigSendType" SG_ 1576 EPS_DiagRespData59 1;
BA_ "GenSigSendType" SG_ 1576 EPS_DiagRespData60 1;
BA_ "GenSigSendType" SG_ 1576 EPS_DiagRespData61 1;
BA_ "GenSigSendType" SG_ 1576 EPS_DiagRespData62 1;
BA_ "GenSigSendType" SG_ 1576 EPS_DiagRespData63 1;
BA_ "GenSigSendType" SG_ 1705 WCBS_DiagReqData0 1;
BA_ "GenSigSendType" SG_ 1705 WCBS_DiagReqData1 1;
BA_ "GenSigSendType" SG_ 1705 WCBS_DiagReqData2 1;
BA_ "GenSigSendType" SG_ 1705 WCBS_DiagReqData3 1;
BA_ "GenSigSendType" SG_ 1705 WCBS_DiagReqData4 1;
BA_ "GenSigSendType" SG_ 1705 WCBS_DiagReqData5 1;
BA_ "GenSigSendType" SG_ 1705 WCBS_DiagReqData6 1;
BA_ "GenSigSendType" SG_ 1705 WCBS_DiagReqData7 1;
BA_ "GenSigSendType" SG_ 1705 WCBS_DiagReqData8 1;
BA_ "GenSigSendType" SG_ 1705 WCBS_DiagReqData9 1;
BA_ "GenSigSendType" SG_ 1705 WCBS_DiagReqData10 1;
BA_ "GenSigSendType" SG_ 1705 WCBS_DiagReqData11 1;
BA_ "GenSigSendType" SG_ 1705 WCBS_DiagReqData12 1;
BA_ "GenSigSendType" SG_ 1705 WCBS_DiagReqData13 1;
BA_ "GenSigSendType" SG_ 1705 WCBS_DiagReqData14 1;
BA_ "GenSigSendType" SG_ 1705 WCBS_DiagReqData15 1;
BA_ "GenSigSendType" SG_ 1705 WCBS_DiagReqData16 1;
BA_ "GenSigSendType" SG_ 1705 WCBS_DiagReqData17 1;
BA_ "GenSigSendType" SG_ 1705 WCBS_DiagReqData18 1;
BA_ "GenSigSendType" SG_ 1705 WCBS_DiagReqData19 1;
BA_ "GenSigSendType" SG_ 1705 WCBS_DiagReqData20 1;
BA_ "GenSigSendType" SG_ 1705 WCBS_DiagReqData21 1;
BA_ "GenSigSendType" SG_ 1705 WCBS_DiagReqData22 1;
BA_ "GenSigSendType" SG_ 1705 WCBS_DiagReqData23 1;
BA_ "GenSigSendType" SG_ 1705 WCBS_DiagReqData24 1;
BA_ "GenSigSendType" SG_ 1705 WCBS_DiagReqData25 1;
BA_ "GenSigSendType" SG_ 1705 WCBS_DiagReqData26 1;
BA_ "GenSigSendType" SG_ 1705 WCBS_DiagReqData27 1;
BA_ "GenSigSendType" SG_ 1705 WCBS_DiagReqData28 1;
BA_ "GenSigSendType" SG_ 1705 WCBS_DiagReqData29 1;
BA_ "GenSigSendType" SG_ 1705 WCBS_DiagReqData30 1;
BA_ "GenSigSendType" SG_ 1705 WCBS_DiagReqData31 1;
BA_ "GenSigSendType" SG_ 1705 WCBS_DiagReqData32 1;
BA_ "GenSigSendType" SG_ 1705 WCBS_DiagReqData33 1;
BA_ "GenSigSendType" SG_ 1705 WCBS_DiagReqData34 1;
BA_ "GenSigSendType" SG_ 1705 WCBS_DiagReqData35 1;
BA_ "GenSigSendType" SG_ 1705 WCBS_DiagReqData36 1;
BA_ "GenSigSendType" SG_ 1705 WCBS_DiagReqData37 1;
BA_ "GenSigSendType" SG_ 1705 WCBS_DiagReqData38 1;
BA_ "GenSigSendType" SG_ 1705 WCBS_DiagReqData39 1;
BA_ "GenSigSendType" SG_ 1705 WCBS_DiagReqData40 1;
BA_ "GenSigSendType" SG_ 1705 WCBS_DiagReqData41 1;
BA_ "GenSigSendType" SG_ 1705 WCBS_DiagReqData42 1;
BA_ "GenSigSendType" SG_ 1705 WCBS_DiagReqData43 1;
BA_ "GenSigSendType" SG_ 1705 WCBS_DiagReqData44 1;
BA_ "GenSigSendType" SG_ 1705 WCBS_DiagReqData45 1;
BA_ "GenSigSendType" SG_ 1705 WCBS_DiagReqData46 1;
BA_ "GenSigSendType" SG_ 1705 WCBS_DiagReqData47 1;
BA_ "GenSigSendType" SG_ 1705 WCBS_DiagReqData48 1;
BA_ "GenSigSendType" SG_ 1705 WCBS_DiagReqData49 1;
BA_ "GenSigSendType" SG_ 1705 WCBS_DiagReqData50 1;
BA_ "GenSigSendType" SG_ 1705 WCBS_DiagReqData51 1;
BA_ "GenSigSendType" SG_ 1705 WCBS_DiagReqData52 1;
BA_ "GenSigSendType" SG_ 1705 WCBS_DiagReqData53 1;
BA_ "GenSigSendType" SG_ 1705 WCBS_DiagReqData54 1;
BA_ "GenSigSendType" SG_ 1705 WCBS_DiagReqData55 1;
BA_ "GenSigSendType" SG_ 1705 WCBS_DiagReqData56 1;
BA_ "GenSigSendType" SG_ 1705 WCBS_DiagReqData57 1;
BA_ "GenSigSendType" SG_ 1705 WCBS_DiagReqData58 1;
BA_ "GenSigSendType" SG_ 1705 WCBS_DiagReqData59 1;
BA_ "GenSigSendType" SG_ 1705 WCBS_DiagReqData60 1;
BA_ "GenSigSendType" SG_ 1705 WCBS_DiagReqData61 1;
BA_ "GenSigSendType" SG_ 1705 WCBS_DiagReqData62 1;
BA_ "GenSigSendType" SG_ 1705 WCBS_DiagReqData63 1;
BA_ "GenSigSendType" SG_ 1577 WCBS_DiagRespData0 1;
BA_ "GenSigSendType" SG_ 1577 WCBS_DiagRespData1 1;
BA_ "GenSigSendType" SG_ 1577 WCBS_DiagRespData2 1;
BA_ "GenSigSendType" SG_ 1577 WCBS_DiagRespData3 1;
BA_ "GenSigSendType" SG_ 1577 WCBS_DiagRespData4 1;
BA_ "GenSigSendType" SG_ 1577 WCBS_DiagRespData5 1;
BA_ "GenSigSendType" SG_ 1577 WCBS_DiagRespData6 1;
BA_ "GenSigSendType" SG_ 1577 WCBS_DiagRespData7 1;
BA_ "GenSigSendType" SG_ 1577 WCBS_DiagRespData8 1;
BA_ "GenSigSendType" SG_ 1577 WCBS_DiagRespData9 1;
BA_ "GenSigSendType" SG_ 1577 WCBS_DiagRespData10 1;
BA_ "GenSigSendType" SG_ 1577 WCBS_DiagRespData11 1;
BA_ "GenSigSendType" SG_ 1577 WCBS_DiagRespData12 1;
BA_ "GenSigSendType" SG_ 1577 WCBS_DiagRespData13 1;
BA_ "GenSigSendType" SG_ 1577 WCBS_DiagRespData14 1;
BA_ "GenSigSendType" SG_ 1577 WCBS_DiagRespData15 1;
BA_ "GenSigSendType" SG_ 1577 WCBS_DiagRespData16 1;
BA_ "GenSigSendType" SG_ 1577 WCBS_DiagRespData17 1;
BA_ "GenSigSendType" SG_ 1577 WCBS_DiagRespData18 1;
BA_ "GenSigSendType" SG_ 1577 WCBS_DiagRespData19 1;
BA_ "GenSigSendType" SG_ 1577 WCBS_DiagRespData20 1;
BA_ "GenSigSendType" SG_ 1577 WCBS_DiagRespData21 1;
BA_ "GenSigSendType" SG_ 1577 WCBS_DiagRespData22 1;
BA_ "GenSigSendType" SG_ 1577 WCBS_DiagRespData23 1;
BA_ "GenSigSendType" SG_ 1577 WCBS_DiagRespData24 1;
BA_ "GenSigSendType" SG_ 1577 WCBS_DiagRespData25 1;
BA_ "GenSigSendType" SG_ 1577 WCBS_DiagRespData26 1;
BA_ "GenSigSendType" SG_ 1577 WCBS_DiagRespData27 1;
BA_ "GenSigSendType" SG_ 1577 WCBS_DiagRespData28 1;
BA_ "GenSigSendType" SG_ 1577 WCBS_DiagRespData29 1;
BA_ "GenSigSendType" SG_ 1577 WCBS_DiagRespData30 1;
BA_ "GenSigSendType" SG_ 1577 WCBS_DiagRespData31 1;
BA_ "GenSigSendType" SG_ 1577 WCBS_DiagRespData32 1;
BA_ "GenSigSendType" SG_ 1577 WCBS_DiagRespData33 1;
BA_ "GenSigSendType" SG_ 1577 WCBS_DiagRespData34 1;
BA_ "GenSigSendType" SG_ 1577 WCBS_DiagRespData35 1;
BA_ "GenSigSendType" SG_ 1577 WCBS_DiagRespData36 1;
BA_ "GenSigSendType" SG_ 1577 WCBS_DiagRespData37 1;
BA_ "GenSigSendType" SG_ 1577 WCBS_DiagRespData38 1;
BA_ "GenSigSendType" SG_ 1577 WCBS_DiagRespData39 1;
BA_ "GenSigSendType" SG_ 1577 WCBS_DiagRespData40 1;
BA_ "GenSigSendType" SG_ 1577 WCBS_DiagRespData41 1;
BA_ "GenSigSendType" SG_ 1577 WCBS_DiagRespData42 1;
BA_ "GenSigSendType" SG_ 1577 WCBS_DiagRespData43 1;
BA_ "GenSigSendType" SG_ 1577 WCBS_DiagRespData44 1;
BA_ "GenSigSendType" SG_ 1577 WCBS_DiagRespData45 1;
BA_ "GenSigSendType" SG_ 1577 WCBS_DiagRespData46 1;
BA_ "GenSigSendType" SG_ 1577 WCBS_DiagRespData47 1;
BA_ "GenSigSendType" SG_ 1577 WCBS_DiagRespData48 1;
BA_ "GenSigSendType" SG_ 1577 WCBS_DiagRespData49 1;
BA_ "GenSigSendType" SG_ 1577 WCBS_DiagRespData50 1;
BA_ "GenSigSendType" SG_ 1577 WCBS_DiagRespData51 1;
BA_ "GenSigSendType" SG_ 1577 WCBS_DiagRespData52 1;
BA_ "GenSigSendType" SG_ 1577 WCBS_DiagRespData53 1;
BA_ "GenSigSendType" SG_ 1577 WCBS_DiagRespData54 1;
BA_ "GenSigSendType" SG_ 1577 WCBS_DiagRespData55 1;
BA_ "GenSigSendType" SG_ 1577 WCBS_DiagRespData56 1;
BA_ "GenSigSendType" SG_ 1577 WCBS_DiagRespData57 1;
BA_ "GenSigSendType" SG_ 1577 WCBS_DiagRespData58 1;
BA_ "GenSigSendType" SG_ 1577 WCBS_DiagRespData59 1;
BA_ "GenSigSendType" SG_ 1577 WCBS_DiagRespData60 1;
BA_ "GenSigSendType" SG_ 1577 WCBS_DiagRespData61 1;
BA_ "GenSigSendType" SG_ 1577 WCBS_DiagRespData62 1;
BA_ "GenSigSendType" SG_ 1577 WCBS_DiagRespData63 1;
BA_ "GenSigSendType" SG_ 1686 FCAM_DiagReqData0 1;
BA_ "GenSigSendType" SG_ 1686 FCAM_DiagReqData1 1;
BA_ "GenSigSendType" SG_ 1686 FCAM_DiagReqData2 1;
BA_ "GenSigSendType" SG_ 1686 FCAM_DiagReqData3 1;
BA_ "GenSigSendType" SG_ 1686 FCAM_DiagReqData4 1;
BA_ "GenSigSendType" SG_ 1686 FCAM_DiagReqData5 1;
BA_ "GenSigSendType" SG_ 1686 FCAM_DiagReqData6 1;
BA_ "GenSigSendType" SG_ 1686 FCAM_DiagReqData7 1;
BA_ "GenSigSendType" SG_ 1686 FCAM_DiagReqData8 1;
BA_ "GenSigSendType" SG_ 1686 FCAM_DiagReqData9 1;
BA_ "GenSigSendType" SG_ 1686 FCAM_DiagReqData10 1;
BA_ "GenSigSendType" SG_ 1686 FCAM_DiagReqData11 1;
BA_ "GenSigSendType" SG_ 1686 FCAM_DiagReqData12 1;
BA_ "GenSigSendType" SG_ 1686 FCAM_DiagReqData13 1;
BA_ "GenSigSendType" SG_ 1686 FCAM_DiagReqData14 1;
BA_ "GenSigSendType" SG_ 1686 FCAM_DiagReqData15 1;
BA_ "GenSigSendType" SG_ 1686 FCAM_DiagReqData16 1;
BA_ "GenSigSendType" SG_ 1686 FCAM_DiagReqData17 1;
BA_ "GenSigSendType" SG_ 1686 FCAM_DiagReqData18 1;
BA_ "GenSigSendType" SG_ 1686 FCAM_DiagReqData19 1;
BA_ "GenSigSendType" SG_ 1686 FCAM_DiagReqData20 1;
BA_ "GenSigSendType" SG_ 1686 FCAM_DiagReqData21 1;
BA_ "GenSigSendType" SG_ 1686 FCAM_DiagReqData22 1;
BA_ "GenSigSendType" SG_ 1686 FCAM_DiagReqData23 1;
BA_ "GenSigSendType" SG_ 1686 FCAM_DiagReqData24 1;
BA_ "GenSigSendType" SG_ 1686 FCAM_DiagReqData25 1;
BA_ "GenSigSendType" SG_ 1686 FCAM_DiagReqData26 1;
BA_ "GenSigSendType" SG_ 1686 FCAM_DiagReqData27 1;
BA_ "GenSigSendType" SG_ 1686 FCAM_DiagReqData28 1;
BA_ "GenSigSendType" SG_ 1686 FCAM_DiagReqData29 1;
BA_ "GenSigSendType" SG_ 1686 FCAM_DiagReqData30 1;
BA_ "GenSigSendType" SG_ 1686 FCAM_DiagReqData31 1;
BA_ "GenSigSendType" SG_ 1686 FCAM_DiagReqData32 1;
BA_ "GenSigSendType" SG_ 1686 FCAM_DiagReqData33 1;
BA_ "GenSigSendType" SG_ 1686 FCAM_DiagReqData34 1;
BA_ "GenSigSendType" SG_ 1686 FCAM_DiagReqData35 1;
BA_ "GenSigSendType" SG_ 1686 FCAM_DiagReqData36 1;
BA_ "GenSigSendType" SG_ 1686 FCAM_DiagReqData37 1;
BA_ "GenSigSendType" SG_ 1686 FCAM_DiagReqData38 1;
BA_ "GenSigSendType" SG_ 1686 FCAM_DiagReqData39 1;
BA_ "GenSigSendType" SG_ 1686 FCAM_DiagReqData40 1;
BA_ "GenSigSendType" SG_ 1686 FCAM_DiagReqData41 1;
BA_ "GenSigSendType" SG_ 1686 FCAM_DiagReqData42 1;
BA_ "GenSigSendType" SG_ 1686 FCAM_DiagReqData43 1;
BA_ "GenSigSendType" SG_ 1686 FCAM_DiagReqData44 1;
BA_ "GenSigSendType" SG_ 1686 FCAM_DiagReqData45 1;
BA_ "GenSigSendType" SG_ 1686 FCAM_DiagReqData46 1;
BA_ "GenSigSendType" SG_ 1686 FCAM_DiagReqData47 1;
BA_ "GenSigSendType" SG_ 1686 FCAM_DiagReqData48 1;
BA_ "GenSigSendType" SG_ 1686 FCAM_DiagReqData49 1;
BA_ "GenSigSendType" SG_ 1686 FCAM_DiagReqData50 1;
BA_ "GenSigSendType" SG_ 1686 FCAM_DiagReqData51 1;
BA_ "GenSigSendType" SG_ 1686 FCAM_DiagReqData52 1;
BA_ "GenSigSendType" SG_ 1686 FCAM_DiagReqData53 1;
BA_ "GenSigSendType" SG_ 1686 FCAM_DiagReqData54 1;
BA_ "GenSigSendType" SG_ 1686 FCAM_DiagReqData55 1;
BA_ "GenSigSendType" SG_ 1686 FCAM_DiagReqData56 1;
BA_ "GenSigSendType" SG_ 1686 FCAM_DiagReqData57 1;
BA_ "GenSigSendType" SG_ 1686 FCAM_DiagReqData58 1;
BA_ "GenSigSendType" SG_ 1686 FCAM_DiagReqData59 1;
BA_ "GenSigSendType" SG_ 1686 FCAM_DiagReqData60 1;
BA_ "GenSigSendType" SG_ 1686 FCAM_DiagReqData61 1;
BA_ "GenSigSendType" SG_ 1686 FCAM_DiagReqData62 1;
BA_ "GenSigSendType" SG_ 1686 FCAM_DiagReqData63 1;
BA_ "GenSigSendType" SG_ 1558 FCAM_DiagRespData0 1;
BA_ "GenSigSendType" SG_ 1558 FCAM_DiagRespData1 1;
BA_ "GenSigSendType" SG_ 1558 FCAM_DiagRespData2 1;
BA_ "GenSigSendType" SG_ 1558 FCAM_DiagRespData3 1;
BA_ "GenSigSendType" SG_ 1558 FCAM_DiagRespData4 1;
BA_ "GenSigSendType" SG_ 1558 FCAM_DiagRespData5 1;
BA_ "GenSigSendType" SG_ 1558 FCAM_DiagRespData6 1;
BA_ "GenSigSendType" SG_ 1558 FCAM_DiagRespData7 1;
BA_ "GenSigSendType" SG_ 1558 FCAM_DiagRespData8 1;
BA_ "GenSigSendType" SG_ 1558 FCAM_DiagRespData9 1;
BA_ "GenSigSendType" SG_ 1558 FCAM_DiagRespData10 1;
BA_ "GenSigSendType" SG_ 1558 FCAM_DiagRespData11 1;
BA_ "GenSigSendType" SG_ 1558 FCAM_DiagRespData12 1;
BA_ "GenSigSendType" SG_ 1558 FCAM_DiagRespData13 1;
BA_ "GenSigSendType" SG_ 1558 FCAM_DiagRespData14 1;
BA_ "GenSigSendType" SG_ 1558 FCAM_DiagRespData15 1;
BA_ "GenSigSendType" SG_ 1558 FCAM_DiagRespData16 1;
BA_ "GenSigSendType" SG_ 1558 FCAM_DiagRespData17 1;
BA_ "GenSigSendType" SG_ 1558 FCAM_DiagRespData18 1;
BA_ "GenSigSendType" SG_ 1558 FCAM_DiagRespData19 1;
BA_ "GenSigSendType" SG_ 1558 FCAM_DiagRespData20 1;
BA_ "GenSigSendType" SG_ 1558 FCAM_DiagRespData21 1;
BA_ "GenSigSendType" SG_ 1558 FCAM_DiagRespData22 1;
BA_ "GenSigSendType" SG_ 1558 FCAM_DiagRespData23 1;
BA_ "GenSigSendType" SG_ 1558 FCAM_DiagRespData24 1;
BA_ "GenSigSendType" SG_ 1558 FCAM_DiagRespData25 1;
BA_ "GenSigSendType" SG_ 1558 FCAM_DiagRespData26 1;
BA_ "GenSigSendType" SG_ 1558 FCAM_DiagRespData27 1;
BA_ "GenSigSendType" SG_ 1558 FCAM_DiagRespData28 1;
BA_ "GenSigSendType" SG_ 1558 FCAM_DiagRespData29 1;
BA_ "GenSigSendType" SG_ 1558 FCAM_DiagRespData30 1;
BA_ "GenSigSendType" SG_ 1558 FCAM_DiagRespData31 1;
BA_ "GenSigSendType" SG_ 1558 FCAM_DiagRespData32 1;
BA_ "GenSigSendType" SG_ 1558 FCAM_DiagRespData33 1;
BA_ "GenSigSendType" SG_ 1558 FCAM_DiagRespData34 1;
BA_ "GenSigSendType" SG_ 1558 FCAM_DiagRespData35 1;
BA_ "GenSigSendType" SG_ 1558 FCAM_DiagRespData36 1;
BA_ "GenSigSendType" SG_ 1558 FCAM_DiagRespData37 1;
BA_ "GenSigSendType" SG_ 1558 FCAM_DiagRespData38 1;
BA_ "GenSigSendType" SG_ 1558 FCAM_DiagRespData39 1;
BA_ "GenSigSendType" SG_ 1558 FCAM_DiagRespData40 1;
BA_ "GenSigSendType" SG_ 1558 FCAM_DiagRespData41 1;
BA_ "GenSigSendType" SG_ 1558 FCAM_DiagRespData42 1;
BA_ "GenSigSendType" SG_ 1558 FCAM_DiagRespData43 1;
BA_ "GenSigSendType" SG_ 1558 FCAM_DiagRespData44 1;
BA_ "GenSigSendType" SG_ 1558 FCAM_DiagRespData45 1;
BA_ "GenSigSendType" SG_ 1558 FCAM_DiagRespData46 1;
BA_ "GenSigSendType" SG_ 1558 FCAM_DiagRespData47 1;
BA_ "GenSigSendType" SG_ 1558 FCAM_DiagRespData48 1;
BA_ "GenSigSendType" SG_ 1558 FCAM_DiagRespData49 1;
BA_ "GenSigSendType" SG_ 1558 FCAM_DiagRespData50 1;
BA_ "GenSigSendType" SG_ 1558 FCAM_DiagRespData51 1;
BA_ "GenSigSendType" SG_ 1558 FCAM_DiagRespData52 1;
BA_ "GenSigSendType" SG_ 1558 FCAM_DiagRespData53 1;
BA_ "GenSigSendType" SG_ 1558 FCAM_DiagRespData54 1;
BA_ "GenSigSendType" SG_ 1558 FCAM_DiagRespData55 1;
BA_ "GenSigSendType" SG_ 1558 FCAM_DiagRespData56 1;
BA_ "GenSigSendType" SG_ 1558 FCAM_DiagRespData57 1;
BA_ "GenSigSendType" SG_ 1558 FCAM_DiagRespData58 1;
BA_ "GenSigSendType" SG_ 1558 FCAM_DiagRespData59 1;
BA_ "GenSigSendType" SG_ 1558 FCAM_DiagRespData60 1;
BA_ "GenSigSendType" SG_ 1558 FCAM_DiagRespData61 1;
BA_ "GenSigSendType" SG_ 1558 FCAM_DiagRespData62 1;
BA_ "GenSigSendType" SG_ 1558 FCAM_DiagRespData63 1;
BA_ "GenSigSendType" SG_ 1728 ADCU_DiagReqData0 1;
BA_ "GenSigSendType" SG_ 1728 ADCU_DiagReqData1 1;
BA_ "GenSigSendType" SG_ 1728 ADCU_DiagReqData2 1;
BA_ "GenSigSendType" SG_ 1728 ADCU_DiagReqData3 1;
BA_ "GenSigSendType" SG_ 1728 ADCU_DiagReqData4 1;
BA_ "GenSigSendType" SG_ 1728 ADCU_DiagReqData5 1;
BA_ "GenSigSendType" SG_ 1728 ADCU_DiagReqData6 1;
BA_ "GenSigSendType" SG_ 1728 ADCU_DiagReqData7 1;
BA_ "GenSigSendType" SG_ 1728 ADCU_DiagReqData8 1;
BA_ "GenSigSendType" SG_ 1728 ADCU_DiagReqData9 1;
BA_ "GenSigSendType" SG_ 1728 ADCU_DiagReqData10 1;
BA_ "GenSigSendType" SG_ 1728 ADCU_DiagReqData11 1;
BA_ "GenSigSendType" SG_ 1728 ADCU_DiagReqData12 1;
BA_ "GenSigSendType" SG_ 1728 ADCU_DiagReqData13 1;
BA_ "GenSigSendType" SG_ 1728 ADCU_DiagReqData14 1;
BA_ "GenSigSendType" SG_ 1728 ADCU_DiagReqData15 1;
BA_ "GenSigSendType" SG_ 1728 ADCU_DiagReqData16 1;
BA_ "GenSigSendType" SG_ 1728 ADCU_DiagReqData17 1;
BA_ "GenSigSendType" SG_ 1728 ADCU_DiagReqData18 1;
BA_ "GenSigSendType" SG_ 1728 ADCU_DiagReqData19 1;
BA_ "GenSigSendType" SG_ 1728 ADCU_DiagReqData20 1;
BA_ "GenSigSendType" SG_ 1728 ADCU_DiagReqData21 1;
BA_ "GenSigSendType" SG_ 1728 ADCU_DiagReqData22 1;
BA_ "GenSigSendType" SG_ 1728 ADCU_DiagReqData23 1;
BA_ "GenSigSendType" SG_ 1728 ADCU_DiagReqData24 1;
BA_ "GenSigSendType" SG_ 1728 ADCU_DiagReqData25 1;
BA_ "GenSigSendType" SG_ 1728 ADCU_DiagReqData26 1;
BA_ "GenSigSendType" SG_ 1728 ADCU_DiagReqData27 1;
BA_ "GenSigSendType" SG_ 1728 ADCU_DiagReqData28 1;
BA_ "GenSigSendType" SG_ 1728 ADCU_DiagReqData29 1;
BA_ "GenSigSendType" SG_ 1728 ADCU_DiagReqData30 1;
BA_ "GenSigSendType" SG_ 1728 ADCU_DiagReqData31 1;
BA_ "GenSigSendType" SG_ 1728 ADCU_DiagReqData32 1;
BA_ "GenSigSendType" SG_ 1728 ADCU_DiagReqData33 1;
BA_ "GenSigSendType" SG_ 1728 ADCU_DiagReqData34 1;
BA_ "GenSigSendType" SG_ 1728 ADCU_DiagReqData35 1;
BA_ "GenSigSendType" SG_ 1728 ADCU_DiagReqData36 1;
BA_ "GenSigSendType" SG_ 1728 ADCU_DiagReqData37 1;
BA_ "GenSigSendType" SG_ 1728 ADCU_DiagReqData38 1;
BA_ "GenSigSendType" SG_ 1728 ADCU_DiagReqData39 1;
BA_ "GenSigSendType" SG_ 1728 ADCU_DiagReqData40 1;
BA_ "GenSigSendType" SG_ 1728 ADCU_DiagReqData41 1;
BA_ "GenSigSendType" SG_ 1728 ADCU_DiagReqData42 1;
BA_ "GenSigSendType" SG_ 1728 ADCU_DiagReqData43 1;
BA_ "GenSigSendType" SG_ 1728 ADCU_DiagReqData44 1;
BA_ "GenSigSendType" SG_ 1728 ADCU_DiagReqData45 1;
BA_ "GenSigSendType" SG_ 1728 ADCU_DiagReqData46 1;
BA_ "GenSigSendType" SG_ 1728 ADCU_DiagReqData47 1;
BA_ "GenSigSendType" SG_ 1728 ADCU_DiagReqData48 1;
BA_ "GenSigSendType" SG_ 1728 ADCU_DiagReqData49 1;
BA_ "GenSigSendType" SG_ 1728 ADCU_DiagReqData50 1;
BA_ "GenSigSendType" SG_ 1728 ADCU_DiagReqData51 1;
BA_ "GenSigSendType" SG_ 1728 ADCU_DiagReqData52 1;
BA_ "GenSigSendType" SG_ 1728 ADCU_DiagReqData53 1;
BA_ "GenSigSendType" SG_ 1728 ADCU_DiagReqData54 1;
BA_ "GenSigSendType" SG_ 1728 ADCU_DiagReqData55 1;
BA_ "GenSigSendType" SG_ 1728 ADCU_DiagReqData56 1;
BA_ "GenSigSendType" SG_ 1728 ADCU_DiagReqData57 1;
BA_ "GenSigSendType" SG_ 1728 ADCU_DiagReqData58 1;
BA_ "GenSigSendType" SG_ 1728 ADCU_DiagReqData59 1;
BA_ "GenSigSendType" SG_ 1728 ADCU_DiagReqData60 1;
BA_ "GenSigSendType" SG_ 1728 ADCU_DiagReqData61 1;
BA_ "GenSigSendType" SG_ 1728 ADCU_DiagReqData62 1;
BA_ "GenSigSendType" SG_ 1728 ADCU_DiagReqData63 1;
BA_ "GenSigSendType" SG_ 1600 ADCU_DiagRespData0 1;
BA_ "GenSigSendType" SG_ 1600 ADCU_DiagRespData1 1;
BA_ "GenSigSendType" SG_ 1600 ADCU_DiagRespData2 1;
BA_ "GenSigSendType" SG_ 1600 ADCU_DiagRespData3 1;
BA_ "GenSigSendType" SG_ 1600 ADCU_DiagRespData4 1;
BA_ "GenSigSendType" SG_ 1600 ADCU_DiagRespData5 1;
BA_ "GenSigSendType" SG_ 1600 ADCU_DiagRespData6 1;
BA_ "GenSigSendType" SG_ 1600 ADCU_DiagRespData7 1;
BA_ "GenSigSendType" SG_ 1600 ADCU_DiagRespData8 1;
BA_ "GenSigSendType" SG_ 1600 ADCU_DiagRespData9 1;
BA_ "GenSigSendType" SG_ 1600 ADCU_DiagRespData10 1;
BA_ "GenSigSendType" SG_ 1600 ADCU_DiagRespData11 1;
BA_ "GenSigSendType" SG_ 1600 ADCU_DiagRespData12 1;
BA_ "GenSigSendType" SG_ 1600 ADCU_DiagRespData13 1;
BA_ "GenSigSendType" SG_ 1600 ADCU_DiagRespData14 1;
BA_ "GenSigSendType" SG_ 1600 ADCU_DiagRespData15 1;
BA_ "GenSigSendType" SG_ 1600 ADCU_DiagRespData16 1;
BA_ "GenSigSendType" SG_ 1600 ADCU_DiagRespData17 1;
BA_ "GenSigSendType" SG_ 1600 ADCU_DiagRespData18 1;
BA_ "GenSigSendType" SG_ 1600 ADCU_DiagRespData19 1;
BA_ "GenSigSendType" SG_ 1600 ADCU_DiagRespData20 1;
BA_ "GenSigSendType" SG_ 1600 ADCU_DiagRespData21 1;
BA_ "GenSigSendType" SG_ 1600 ADCU_DiagRespData22 1;
BA_ "GenSigSendType" SG_ 1600 ADCU_DiagRespData23 1;
BA_ "GenSigSendType" SG_ 1600 ADCU_DiagRespData24 1;
BA_ "GenSigSendType" SG_ 1600 ADCU_DiagRespData25 1;
BA_ "GenSigSendType" SG_ 1600 ADCU_DiagRespData26 1;
BA_ "GenSigSendType" SG_ 1600 ADCU_DiagRespData27 1;
BA_ "GenSigSendType" SG_ 1600 ADCU_DiagRespData28 1;
BA_ "GenSigSendType" SG_ 1600 ADCU_DiagRespData29 1;
BA_ "GenSigSendType" SG_ 1600 ADCU_DiagRespData30 1;
BA_ "GenSigSendType" SG_ 1600 ADCU_DiagRespData31 1;
BA_ "GenSigSendType" SG_ 1600 ADCU_DiagRespData32 1;
BA_ "GenSigSendType" SG_ 1600 ADCU_DiagRespData33 1;
BA_ "GenSigSendType" SG_ 1600 ADCU_DiagRespData34 1;
BA_ "GenSigSendType" SG_ 1600 ADCU_DiagRespData35 1;
BA_ "GenSigSendType" SG_ 1600 ADCU_DiagRespData36 1;
BA_ "GenSigSendType" SG_ 1600 ADCU_DiagRespData37 1;
BA_ "GenSigSendType" SG_ 1600 ADCU_DiagRespData38 1;
BA_ "GenSigSendType" SG_ 1600 ADCU_DiagRespData39 1;
BA_ "GenSigSendType" SG_ 1600 ADCU_DiagRespData40 1;
BA_ "GenSigSendType" SG_ 1600 ADCU_DiagRespData41 1;
BA_ "GenSigSendType" SG_ 1600 ADCU_DiagRespData42 1;
BA_ "GenSigSendType" SG_ 1600 ADCU_DiagRespData43 1;
BA_ "GenSigSendType" SG_ 1600 ADCU_DiagRespData44 1;
BA_ "GenSigSendType" SG_ 1600 ADCU_DiagRespData45 1;
BA_ "GenSigSendType" SG_ 1600 ADCU_DiagRespData46 1;
BA_ "GenSigSendType" SG_ 1600 ADCU_DiagRespData47 1;
BA_ "GenSigSendType" SG_ 1600 ADCU_DiagRespData48 1;
BA_ "GenSigSendType" SG_ 1600 ADCU_DiagRespData49 1;
BA_ "GenSigSendType" SG_ 1600 ADCU_DiagRespData50 1;
BA_ "GenSigSendType" SG_ 1600 ADCU_DiagRespData51 1;
BA_ "GenSigSendType" SG_ 1600 ADCU_DiagRespData52 1;
BA_ "GenSigSendType" SG_ 1600 ADCU_DiagRespData53 1;
BA_ "GenSigSendType" SG_ 1600 ADCU_DiagRespData54 1;
BA_ "GenSigSendType" SG_ 1600 ADCU_DiagRespData55 1;
BA_ "GenSigSendType" SG_ 1600 ADCU_DiagRespData56 1;
BA_ "GenSigSendType" SG_ 1600 ADCU_DiagRespData57 1;
BA_ "GenSigSendType" SG_ 1600 ADCU_DiagRespData58 1;
BA_ "GenSigSendType" SG_ 1600 ADCU_DiagRespData59 1;
BA_ "GenSigSendType" SG_ 1600 ADCU_DiagRespData60 1;
BA_ "GenSigSendType" SG_ 1600 ADCU_DiagRespData61 1;
BA_ "GenSigSendType" SG_ 1600 ADCU_DiagRespData62 1;
BA_ "GenSigSendType" SG_ 1600 ADCU_DiagRespData63 1;
BA_ "GenSigSendType" SG_ 1791 OBD_Func_DiagReqData0 1;
BA_ "GenSigSendType" SG_ 1791 OBD_Func_DiagReqData1 1;
BA_ "GenSigSendType" SG_ 1791 OBD_Func_DiagReqData2 1;
BA_ "GenSigSendType" SG_ 1791 OBD_Func_DiagReqData3 1;
BA_ "GenSigSendType" SG_ 1791 OBD_Func_DiagReqData4 1;
BA_ "GenSigSendType" SG_ 1791 OBD_Func_DiagReqData5 1;
BA_ "GenSigSendType" SG_ 1791 OBD_Func_DiagReqData6 1;
BA_ "GenSigSendType" SG_ 1791 OBD_Func_DiagReqData7 1;
BA_ "GenSigSendType" SG_ 1872 WCBS_Calibration_Req_M0 1;
BA_ "GenSigSendType" SG_ 1872 WCBS_Calibration_Req_M1 1;
BA_ "GenSigSendType" SG_ 1872 WCBS_Calibration_Req_M2 1;
BA_ "GenSigSendType" SG_ 1872 WCBS_Calibration_Req_M3 1;
BA_ "GenSigSendType" SG_ 1872 WCBS_Calibration_Req_M4 1;
BA_ "GenSigSendType" SG_ 1872 WCBS_Calibration_Req_M5 1;
BA_ "GenSigSendType" SG_ 1872 WCBS_Calibration_Req_M6 1;
BA_ "GenSigSendType" SG_ 1872 WCBS_Calibration_Req_M7 1;
BA_ "GenSigSendType" SG_ 1872 WCBS_Calibration_Req_M8 1;
BA_ "GenSigSendType" SG_ 1872 WCBS_Calibration_Req_M9 1;
BA_ "GenSigSendType" SG_ 1872 WCBS_Calibration_Req_M10 1;
BA_ "GenSigSendType" SG_ 1872 WCBS_Calibration_Req_M11 1;
BA_ "GenSigSendType" SG_ 1872 WCBS_Calibration_Req_M12 1;
BA_ "GenSigSendType" SG_ 1872 WCBS_Calibration_Req_M13 1;
BA_ "GenSigSendType" SG_ 1872 WCBS_Calibration_Req_M14 1;
BA_ "GenSigSendType" SG_ 1872 WCBS_Calibration_Req_M15 1;
BA_ "GenSigSendType" SG_ 1872 WCBS_Calibration_Req_M16 1;
BA_ "GenSigSendType" SG_ 1872 WCBS_Calibration_Req_M17 1;
BA_ "GenSigSendType" SG_ 1872 WCBS_Calibration_Req_M18 1;
BA_ "GenSigSendType" SG_ 1872 WCBS_Calibration_Req_M19 1;
BA_ "GenSigSendType" SG_ 1872 WCBS_Calibration_Req_M20 1;
BA_ "GenSigSendType" SG_ 1872 WCBS_Calibration_Req_M21 1;
BA_ "GenSigSendType" SG_ 1872 WCBS_Calibration_Req_M22 1;
BA_ "GenSigSendType" SG_ 1872 WCBS_Calibration_Req_M23 1;
BA_ "GenSigSendType" SG_ 1872 WCBS_Calibration_Req_M24 1;
BA_ "GenSigSendType" SG_ 1872 WCBS_Calibration_Req_M25 1;
BA_ "GenSigSendType" SG_ 1872 WCBS_Calibration_Req_M26 1;
BA_ "GenSigSendType" SG_ 1872 WCBS_Calibration_Req_M27 1;
BA_ "GenSigSendType" SG_ 1872 WCBS_Calibration_Req_M28 1;
BA_ "GenSigSendType" SG_ 1872 WCBS_Calibration_Req_M29 1;
BA_ "GenSigSendType" SG_ 1872 WCBS_Calibration_Req_M30 1;
BA_ "GenSigSendType" SG_ 1872 WCBS_Calibration_Req_M31 1;
BA_ "GenSigSendType" SG_ 1872 WCBS_Calibration_Req_M32 1;
BA_ "GenSigSendType" SG_ 1872 WCBS_Calibration_Req_M33 1;
BA_ "GenSigSendType" SG_ 1872 WCBS_Calibration_Req_M34 1;
BA_ "GenSigSendType" SG_ 1872 WCBS_Calibration_Req_M35 1;
BA_ "GenSigSendType" SG_ 1872 WCBS_Calibration_Req_M36 1;
BA_ "GenSigSendType" SG_ 1872 WCBS_Calibration_Req_M37 1;
BA_ "GenSigSendType" SG_ 1872 WCBS_Calibration_Req_M38 1;
BA_ "GenSigSendType" SG_ 1872 WCBS_Calibration_Req_M39 1;
BA_ "GenSigSendType" SG_ 1872 WCBS_Calibration_Req_M40 1;
BA_ "GenSigSendType" SG_ 1872 WCBS_Calibration_Req_M41 1;
BA_ "GenSigSendType" SG_ 1872 WCBS_Calibration_Req_M42 1;
BA_ "GenSigSendType" SG_ 1872 WCBS_Calibration_Req_M43 1;
BA_ "GenSigSendType" SG_ 1872 WCBS_Calibration_Req_M44 1;
BA_ "GenSigSendType" SG_ 1872 WCBS_Calibration_Req_M45 1;
BA_ "GenSigSendType" SG_ 1872 WCBS_Calibration_Req_M46 1;
BA_ "GenSigSendType" SG_ 1872 WCBS_Calibration_Req_M47 1;
BA_ "GenSigSendType" SG_ 1872 WCBS_Calibration_Req_M48 1;
BA_ "GenSigSendType" SG_ 1872 WCBS_Calibration_Req_M49 1;
BA_ "GenSigSendType" SG_ 1872 WCBS_Calibration_Req_M50 1;
BA_ "GenSigSendType" SG_ 1872 WCBS_Calibration_Req_M51 1;
BA_ "GenSigSendType" SG_ 1872 WCBS_Calibration_Req_M52 1;
BA_ "GenSigSendType" SG_ 1872 WCBS_Calibration_Req_M53 1;
BA_ "GenSigSendType" SG_ 1872 WCBS_Calibration_Req_M54 1;
BA_ "GenSigSendType" SG_ 1872 WCBS_Calibration_Req_M55 1;
BA_ "GenSigSendType" SG_ 1872 WCBS_Calibration_Req_M56 1;
BA_ "GenSigSendType" SG_ 1872 WCBS_Calibration_Req_M57 1;
BA_ "GenSigSendType" SG_ 1872 WCBS_Calibration_Req_M58 1;
BA_ "GenSigSendType" SG_ 1872 WCBS_Calibration_Req_M59 1;
BA_ "GenSigSendType" SG_ 1872 WCBS_Calibration_Req_M60 1;
BA_ "GenSigSendType" SG_ 1872 WCBS_Calibration_Req_M61 1;
BA_ "GenSigSendType" SG_ 1872 WCBS_Calibration_Req_M62 1;
BA_ "GenSigSendType" SG_ 1872 WCBS_Calibration_Req_M63 1;
BA_ "GenSigSendType" SG_ 1888 WCBS_Calibration_Resp_M0 1;
BA_ "GenSigSendType" SG_ 1888 WCBS_Calibration_Resp_M1 1;
BA_ "GenSigSendType" SG_ 1888 WCBS_Calibration_Resp_M2 1;
BA_ "GenSigSendType" SG_ 1888 WCBS_Calibration_Resp_M3 1;
BA_ "GenSigSendType" SG_ 1888 WCBS_Calibration_Resp_M4 1;
BA_ "GenSigSendType" SG_ 1888 WCBS_Calibration_Resp_M5 1;
BA_ "GenSigSendType" SG_ 1888 WCBS_Calibration_Resp_M6 1;
BA_ "GenSigSendType" SG_ 1888 WCBS_Calibration_Resp_M7 1;
BA_ "GenSigSendType" SG_ 1888 WCBS_Calibration_Resp_M8 1;
BA_ "GenSigSendType" SG_ 1888 WCBS_Calibration_Resp_M9 1;
BA_ "GenSigSendType" SG_ 1888 WCBS_Calibration_Resp_M10 1;
BA_ "GenSigSendType" SG_ 1888 WCBS_Calibration_Resp_M11 1;
BA_ "GenSigSendType" SG_ 1888 WCBS_Calibration_Resp_M12 1;
BA_ "GenSigSendType" SG_ 1888 WCBS_Calibration_Resp_M13 1;
BA_ "GenSigSendType" SG_ 1888 WCBS_Calibration_Resp_M14 1;
BA_ "GenSigSendType" SG_ 1888 WCBS_Calibration_Resp_M15 1;
BA_ "GenSigSendType" SG_ 1888 WCBS_Calibration_Resp_M16 1;
BA_ "GenSigSendType" SG_ 1888 WCBS_Calibration_Resp_M17 1;
BA_ "GenSigSendType" SG_ 1888 WCBS_Calibration_Resp_M18 1;
BA_ "GenSigSendType" SG_ 1888 WCBS_Calibration_Resp_M19 1;
BA_ "GenSigSendType" SG_ 1888 WCBS_Calibration_Resp_M20 1;
BA_ "GenSigSendType" SG_ 1888 WCBS_Calibration_Resp_M21 1;
BA_ "GenSigSendType" SG_ 1888 WCBS_Calibration_Resp_M22 1;
BA_ "GenSigSendType" SG_ 1888 WCBS_Calibration_Resp_M23 1;
BA_ "GenSigSendType" SG_ 1888 WCBS_Calibration_Resp_M24 1;
BA_ "GenSigSendType" SG_ 1888 WCBS_Calibration_Resp_M25 1;
BA_ "GenSigSendType" SG_ 1888 WCBS_Calibration_Resp_M26 1;
BA_ "GenSigSendType" SG_ 1888 WCBS_Calibration_Resp_M27 1;
BA_ "GenSigSendType" SG_ 1888 WCBS_Calibration_Resp_M28 1;
BA_ "GenSigSendType" SG_ 1888 WCBS_Calibration_Resp_M29 1;
BA_ "GenSigSendType" SG_ 1888 WCBS_Calibration_Resp_M30 1;
BA_ "GenSigSendType" SG_ 1888 WCBS_Calibration_Resp_M31 1;
BA_ "GenSigSendType" SG_ 1888 WCBS_Calibration_Resp_M32 1;
BA_ "GenSigSendType" SG_ 1888 WCBS_Calibration_Resp_M33 1;
BA_ "GenSigSendType" SG_ 1888 WCBS_Calibration_Resp_M34 1;
BA_ "GenSigSendType" SG_ 1888 WCBS_Calibration_Resp_M35 1;
BA_ "GenSigSendType" SG_ 1888 WCBS_Calibration_Resp_M36 1;
BA_ "GenSigSendType" SG_ 1888 WCBS_Calibration_Resp_M37 1;
BA_ "GenSigSendType" SG_ 1888 WCBS_Calibration_Resp_M38 1;
BA_ "GenSigSendType" SG_ 1888 WCBS_Calibration_Resp_M39 1;
BA_ "GenSigSendType" SG_ 1888 WCBS_Calibration_Resp_M40 1;
BA_ "GenSigSendType" SG_ 1888 WCBS_Calibration_Resp_M41 1;
BA_ "GenSigSendType" SG_ 1888 WCBS_Calibration_Resp_M42 1;
BA_ "GenSigSendType" SG_ 1888 WCBS_Calibration_Resp_M43 1;
BA_ "GenSigSendType" SG_ 1888 WCBS_Calibration_Resp_M44 1;
BA_ "GenSigSendType" SG_ 1888 WCBS_Calibration_Resp_M45 1;
BA_ "GenSigSendType" SG_ 1888 WCBS_Calibration_Resp_M46 1;
BA_ "GenSigSendType" SG_ 1888 WCBS_Calibration_Resp_M47 1;
BA_ "GenSigSendType" SG_ 1888 WCBS_Calibration_Resp_M48 1;
BA_ "GenSigSendType" SG_ 1888 WCBS_Calibration_Resp_M49 1;
BA_ "GenSigSendType" SG_ 1888 WCBS_Calibration_Resp_M50 1;
BA_ "GenSigSendType" SG_ 1888 WCBS_Calibration_Resp_M51 1;
BA_ "GenSigSendType" SG_ 1888 WCBS_Calibration_Resp_M52 1;
BA_ "GenSigSendType" SG_ 1888 WCBS_Calibration_Resp_M53 1;
BA_ "GenSigSendType" SG_ 1888 WCBS_Calibration_Resp_M54 1;
BA_ "GenSigSendType" SG_ 1888 WCBS_Calibration_Resp_M55 1;
BA_ "GenSigSendType" SG_ 1888 WCBS_Calibration_Resp_M56 1;
BA_ "GenSigSendType" SG_ 1888 WCBS_Calibration_Resp_M57 1;
BA_ "GenSigSendType" SG_ 1888 WCBS_Calibration_Resp_M58 1;
BA_ "GenSigSendType" SG_ 1888 WCBS_Calibration_Resp_M59 1;
BA_ "GenSigSendType" SG_ 1888 WCBS_Calibration_Resp_M60 1;
BA_ "GenSigSendType" SG_ 1888 WCBS_Calibration_Resp_M61 1;
BA_ "GenSigSendType" SG_ 1888 WCBS_Calibration_Resp_M62 1;
BA_ "GenSigSendType" SG_ 1888 WCBS_Calibration_Resp_M63 1;
BA_ "GenSigSendType" SG_ 1873 WCBS_Calibration_Req_A0 1;
BA_ "GenSigSendType" SG_ 1873 WCBS_Calibration_Req_A1 1;
BA_ "GenSigSendType" SG_ 1873 WCBS_Calibration_Req_A2 1;
BA_ "GenSigSendType" SG_ 1873 WCBS_Calibration_Req_A3 1;
BA_ "GenSigSendType" SG_ 1873 WCBS_Calibration_Req_A4 1;
BA_ "GenSigSendType" SG_ 1873 WCBS_Calibration_Req_A5 1;
BA_ "GenSigSendType" SG_ 1873 WCBS_Calibration_Req_A6 1;
BA_ "GenSigSendType" SG_ 1873 WCBS_Calibration_Req_A7 1;
BA_ "GenSigSendType" SG_ 1873 WCBS_Calibration_Req_A8 1;
BA_ "GenSigSendType" SG_ 1873 WCBS_Calibration_Req_A9 1;
BA_ "GenSigSendType" SG_ 1873 WCBS_Calibration_Req_A10 1;
BA_ "GenSigSendType" SG_ 1873 WCBS_Calibration_Req_A11 1;
BA_ "GenSigSendType" SG_ 1873 WCBS_Calibration_Req_A12 1;
BA_ "GenSigSendType" SG_ 1873 WCBS_Calibration_Req_A13 1;
BA_ "GenSigSendType" SG_ 1873 WCBS_Calibration_Req_A14 1;
BA_ "GenSigSendType" SG_ 1873 WCBS_Calibration_Req_A15 1;
BA_ "GenSigSendType" SG_ 1873 WCBS_Calibration_Req_A16 1;
BA_ "GenSigSendType" SG_ 1873 WCBS_Calibration_Req_A17 1;
BA_ "GenSigSendType" SG_ 1873 WCBS_Calibration_Req_A18 1;
BA_ "GenSigSendType" SG_ 1873 WCBS_Calibration_Req_A19 1;
BA_ "GenSigSendType" SG_ 1873 WCBS_Calibration_Req_A20 1;
BA_ "GenSigSendType" SG_ 1873 WCBS_Calibration_Req_A21 1;
BA_ "GenSigSendType" SG_ 1873 WCBS_Calibration_Req_A22 1;
BA_ "GenSigSendType" SG_ 1873 WCBS_Calibration_Req_A23 1;
BA_ "GenSigSendType" SG_ 1873 WCBS_Calibration_Req_A24 1;
BA_ "GenSigSendType" SG_ 1873 WCBS_Calibration_Req_A25 1;
BA_ "GenSigSendType" SG_ 1873 WCBS_Calibration_Req_A26 1;
BA_ "GenSigSendType" SG_ 1873 WCBS_Calibration_Req_A27 1;
BA_ "GenSigSendType" SG_ 1873 WCBS_Calibration_Req_A28 1;
BA_ "GenSigSendType" SG_ 1873 WCBS_Calibration_Req_A29 1;
BA_ "GenSigSendType" SG_ 1873 WCBS_Calibration_Req_A30 1;
BA_ "GenSigSendType" SG_ 1873 WCBS_Calibration_Req_A31 1;
BA_ "GenSigSendType" SG_ 1873 WCBS_Calibration_Req_A32 1;
BA_ "GenSigSendType" SG_ 1873 WCBS_Calibration_Req_A33 1;
BA_ "GenSigSendType" SG_ 1873 WCBS_Calibration_Req_A34 1;
BA_ "GenSigSendType" SG_ 1873 WCBS_Calibration_Req_A35 1;
BA_ "GenSigSendType" SG_ 1873 WCBS_Calibration_Req_A36 1;
BA_ "GenSigSendType" SG_ 1873 WCBS_Calibration_Req_A37 1;
BA_ "GenSigSendType" SG_ 1873 WCBS_Calibration_Req_A38 1;
BA_ "GenSigSendType" SG_ 1873 WCBS_Calibration_Req_A39 1;
BA_ "GenSigSendType" SG_ 1873 WCBS_Calibration_Req_A40 1;
BA_ "GenSigSendType" SG_ 1873 WCBS_Calibration_Req_A41 1;
BA_ "GenSigSendType" SG_ 1873 WCBS_Calibration_Req_A42 1;
BA_ "GenSigSendType" SG_ 1873 WCBS_Calibration_Req_A43 1;
BA_ "GenSigSendType" SG_ 1873 WCBS_Calibration_Req_A44 1;
BA_ "GenSigSendType" SG_ 1873 WCBS_Calibration_Req_A45 1;
BA_ "GenSigSendType" SG_ 1873 WCBS_Calibration_Req_A46 1;
BA_ "GenSigSendType" SG_ 1873 WCBS_Calibration_Req_A47 1;
BA_ "GenSigSendType" SG_ 1873 WCBS_Calibration_Req_A48 1;
BA_ "GenSigSendType" SG_ 1873 WCBS_Calibration_Req_A49 1;
BA_ "GenSigSendType" SG_ 1873 WCBS_Calibration_Req_A50 1;
BA_ "GenSigSendType" SG_ 1873 WCBS_Calibration_Req_A51 1;
BA_ "GenSigSendType" SG_ 1873 WCBS_Calibration_Req_A52 1;
BA_ "GenSigSendType" SG_ 1873 WCBS_Calibration_Req_A53 1;
BA_ "GenSigSendType" SG_ 1873 WCBS_Calibration_Req_A54 1;
BA_ "GenSigSendType" SG_ 1873 WCBS_Calibration_Req_A55 1;
BA_ "GenSigSendType" SG_ 1873 WCBS_Calibration_Req_A56 1;
BA_ "GenSigSendType" SG_ 1873 WCBS_Calibration_Req_A57 1;
BA_ "GenSigSendType" SG_ 1873 WCBS_Calibration_Req_A58 1;
BA_ "GenSigSendType" SG_ 1873 WCBS_Calibration_Req_A59 1;
BA_ "GenSigSendType" SG_ 1873 WCBS_Calibration_Req_A60 1;
BA_ "GenSigSendType" SG_ 1873 WCBS_Calibration_Req_A61 1;
BA_ "GenSigSendType" SG_ 1873 WCBS_Calibration_Req_A62 1;
BA_ "GenSigSendType" SG_ 1873 WCBS_Calibration_Req_A63 1;
BA_ "GenSigSendType" SG_ 1889 WCBS_Calibration_Resp_A0 1;
BA_ "GenSigSendType" SG_ 1889 WCBS_Calibration_Resp_A1 1;
BA_ "GenSigSendType" SG_ 1889 WCBS_Calibration_Resp_A2 1;
BA_ "GenSigSendType" SG_ 1889 WCBS_Calibration_Resp_A3 1;
BA_ "GenSigSendType" SG_ 1889 WCBS_Calibration_Resp_A4 1;
BA_ "GenSigSendType" SG_ 1889 WCBS_Calibration_Resp_A5 1;
BA_ "GenSigSendType" SG_ 1889 WCBS_Calibration_Resp_A6 1;
BA_ "GenSigSendType" SG_ 1889 WCBS_Calibration_Resp_A7 1;
BA_ "GenSigSendType" SG_ 1889 WCBS_Calibration_Resp_A8 1;
BA_ "GenSigSendType" SG_ 1889 WCBS_Calibration_Resp_A9 1;
BA_ "GenSigSendType" SG_ 1889 WCBS_Calibration_Resp_A10 1;
BA_ "GenSigSendType" SG_ 1889 WCBS_Calibration_Resp_A11 1;
BA_ "GenSigSendType" SG_ 1889 WCBS_Calibration_Resp_A12 1;
BA_ "GenSigSendType" SG_ 1889 WCBS_Calibration_Resp_A13 1;
BA_ "GenSigSendType" SG_ 1889 WCBS_Calibration_Resp_A14 1;
BA_ "GenSigSendType" SG_ 1889 WCBS_Calibration_Resp_A15 1;
BA_ "GenSigSendType" SG_ 1889 WCBS_Calibration_Resp_A16 1;
BA_ "GenSigSendType" SG_ 1889 WCBS_Calibration_Resp_A17 1;
BA_ "GenSigSendType" SG_ 1889 WCBS_Calibration_Resp_A18 1;
BA_ "GenSigSendType" SG_ 1889 WCBS_Calibration_Resp_A19 1;
BA_ "GenSigSendType" SG_ 1889 WCBS_Calibration_Resp_A20 1;
BA_ "GenSigSendType" SG_ 1889 WCBS_Calibration_Resp_A21 1;
BA_ "GenSigSendType" SG_ 1889 WCBS_Calibration_Resp_A22 1;
BA_ "GenSigSendType" SG_ 1889 WCBS_Calibration_Resp_A23 1;
BA_ "GenSigSendType" SG_ 1889 WCBS_Calibration_Resp_A24 1;
BA_ "GenSigSendType" SG_ 1889 WCBS_Calibration_Resp_A25 1;
BA_ "GenSigSendType" SG_ 1889 WCBS_Calibration_Resp_A26 1;
BA_ "GenSigSendType" SG_ 1889 WCBS_Calibration_Resp_A27 1;
BA_ "GenSigSendType" SG_ 1889 WCBS_Calibration_Resp_A28 1;
BA_ "GenSigSendType" SG_ 1889 WCBS_Calibration_Resp_A29 1;
BA_ "GenSigSendType" SG_ 1889 WCBS_Calibration_Resp_A30 1;
BA_ "GenSigSendType" SG_ 1889 WCBS_Calibration_Resp_A31 1;
BA_ "GenSigSendType" SG_ 1889 WCBS_Calibration_Resp_A32 1;
BA_ "GenSigSendType" SG_ 1889 WCBS_Calibration_Resp_A33 1;
BA_ "GenSigSendType" SG_ 1889 WCBS_Calibration_Resp_A34 1;
BA_ "GenSigSendType" SG_ 1889 WCBS_Calibration_Resp_A35 1;
BA_ "GenSigSendType" SG_ 1889 WCBS_Calibration_Resp_A36 1;
BA_ "GenSigSendType" SG_ 1889 WCBS_Calibration_Resp_A37 1;
BA_ "GenSigSendType" SG_ 1889 WCBS_Calibration_Resp_A38 1;
BA_ "GenSigSendType" SG_ 1889 WCBS_Calibration_Resp_A39 1;
BA_ "GenSigSendType" SG_ 1889 WCBS_Calibration_Resp_A40 1;
BA_ "GenSigSendType" SG_ 1889 WCBS_Calibration_Resp_A41 1;
BA_ "GenSigSendType" SG_ 1889 WCBS_Calibration_Resp_A42 1;
BA_ "GenSigSendType" SG_ 1889 WCBS_Calibration_Resp_A43 1;
BA_ "GenSigSendType" SG_ 1889 WCBS_Calibration_Resp_A44 1;
BA_ "GenSigSendType" SG_ 1889 WCBS_Calibration_Resp_A45 1;
BA_ "GenSigSendType" SG_ 1889 WCBS_Calibration_Resp_A46 1;
BA_ "GenSigSendType" SG_ 1889 WCBS_Calibration_Resp_A47 1;
BA_ "GenSigSendType" SG_ 1889 WCBS_Calibration_Resp_A48 1;
BA_ "GenSigSendType" SG_ 1889 WCBS_Calibration_Resp_A49 1;
BA_ "GenSigSendType" SG_ 1889 WCBS_Calibration_Resp_A50 1;
BA_ "GenSigSendType" SG_ 1889 WCBS_Calibration_Resp_A51 1;
BA_ "GenSigSendType" SG_ 1889 WCBS_Calibration_Resp_A52 1;
BA_ "GenSigSendType" SG_ 1889 WCBS_Calibration_Resp_A53 1;
BA_ "GenSigSendType" SG_ 1889 WCBS_Calibration_Resp_A54 1;
BA_ "GenSigSendType" SG_ 1889 WCBS_Calibration_Resp_A55 1;
BA_ "GenSigSendType" SG_ 1889 WCBS_Calibration_Resp_A56 1;
BA_ "GenSigSendType" SG_ 1889 WCBS_Calibration_Resp_A57 1;
BA_ "GenSigSendType" SG_ 1889 WCBS_Calibration_Resp_A58 1;
BA_ "GenSigSendType" SG_ 1889 WCBS_Calibration_Resp_A59 1;
BA_ "GenSigSendType" SG_ 1889 WCBS_Calibration_Resp_A60 1;
BA_ "GenSigSendType" SG_ 1889 WCBS_Calibration_Resp_A61 1;
BA_ "GenSigSendType" SG_ 1889 WCBS_Calibration_Resp_A62 1;
BA_ "GenSigSendType" SG_ 1889 WCBS_Calibration_Resp_A63 1;
VAL_ 314 FCAM_ESA_Sts 0 "FctaOn1_StrtUpOn (Not_enabled)" 1 "FctaOn1_On (Active)" 2 "FctaOn1_Off (Inactive)" 3 "FctaOn1_Error (Denied)" ;
VAL_ 314 FCAM_ESA_Execution_Side 0 "To the right side" 1 "To the left side" ;
VAL_ 314 FCAM_ESA_Popup_Sts 0 "None" 1 "Post ESA triggered" 2 "Post AEB + ESA triggered" 3 "ESA assisting" ;
VAL_ 314 FCAM_ESA_Mode 0 "OFF" 1 "ON" ;
VAL_ 314 FCAM_ESA_check 0 "Available" 1 "Temporary fault" 2 "Permanent Fault" 3 "Invalid" ;
VAL_ 466 FCAM_TSR_SLWSwtResp 0 "Off" 1 "On" ;
VAL_ 466 FCAM_FC_CalibrationSts 0 "Calibration Success" 1 "Calibration In Process" 2 "Calibration Failed" 3 "Reserved" ;
VAL_ 466 FCAM_BlockageSts 0 "Front Camera Not Blockage" 1 "Front Camera Blockage" ;
VAL_ 466 FCAM_AEB_ABA_Req 0 "No Request" 1 "Request" ;
VAL_ 466 FCAM_AEB_AWB_Req 0 "No Request" 1 "Request" ;
VAL_ 466 FCAM_AEB_TgtDecel_Req 0 "No Request" 1 "Request" ;
VAL_ 466 FCAM_AEB_VehHldReq 0 "No Request" 1 "Request" ;
VAL_ 466 FCAM_AEB_AWB_Level 0 "No level" 1 "Level 1" 2 "Level 2" 3 "Level 3" 4 "Level 4" 5 "Reserved" 6 "Reserved" 7 "Reserved" 8 "Reserved" 9 "Reserved" 10 "Reserved" 11 "Reserved" 12 "Reserved" 13 "Reserved" 14 "Reserved" 15 "Reserved" ;
VAL_ 471 FCAM_ADCU_Alive_Distinguish 0 "FCAM Alive" 1 "FCAM not Alive" ;
VAL_ 471 FCAM_ADCU_CONTROL_SOURCE 0 "FCAM in Control" 1 "ADCU in Control" 2 "Reserved" 3 "Invalid" ;
VAL_ 813 FCAM_ACC_Information 0 "System without error" 1 "Performance Degraded" 2 "Temporary unavailable" 3 "ACC Service Required" ;
VAL_ 813 FCAM_ACC_Main_Mode 0 "ACC Switch Off" 1 "ACC Switch On" ;
VAL_ 813 FCAM_ACC_StandstillReq 0 "No request" 1 "Stop control is required" ;
VAL_ 813 FCAM_ACC_Mode 0 "OFF State or Passive" 1 "Stand by state" 2 "Active" 3 "Override" 4 "Brake Only" 5 "Standstill Active" 6 "Standstill Wait" 7 "Fault" ;
VAL_ 813 FCAM_ACC_IDB_DecCmdAct 0 "No Deceleration" 1 "Deceleration" ;
VAL_ 814 FCAM_AEB_Prefill 0 "No demand" 1 "Demand" ;
VAL_ 814 FCAM_AEB_HBA_Level 0 "Standard threshold" 1 "Lowered threshold 1" 2 "Lowered threshold 2" 3 "Lowered threshold 3" ;
VAL_ 814 FCAM_AEB_HBA_Req 0 "No request" 1 "Request" ;
VAL_ 814 FCAM_AEB_Braking_Progress 0 "No demand" 1 "Demand" ;
VAL_ 814 FCAM_AEB_Hold 0 "No hold" 1 "Hold" ;
VAL_ 814 FCAM_AEB_DBS_Active 0 "DBS Not Activated" 1 "DBS Activated" ;
VAL_ 851 FCAM_ACC_ObjDetec 0 "Lead Object Not detected" 1 "Lead Object detected" ;
VAL_ 851 FCAM_ISA_check 0 "Available" 1 "Temporarily not available" 2 "Permanently not available" ;
VAL_ 851 FCAM_ISA_Mode_SW_Feed 0 "OFF" 1 "ON" 2 "Auto" 3 "Reserved" ;
VAL_ 851 FCAM_TagSpeed_ICON_Feed 0 "Off" 1 "Gray ICON" 2 "Green ICON" 3 "White ICON" 4 "Yellow ICON" 5 "Red ICON" ;
VAL_ 851 FCAM_ISA_PopUp_Feed 0 "-" 1 "Accelerating to match speed limit" 2 "Decelerating to match speed limit" 3 "Press steering wheel button to match speed limit" 4 "Intelligent Speed Assist Unavailable" 5 "Reserved" 6 "Reserved" 7 "Reserved" 8 "Reserved" 9 "Reserved" 10 "Reserved" 11 "Reserved" 12 "Reserved" 13 "Reserved" 14 "Reserved" 15 "Invalid" ;
VAL_ 851 FCAM_ISA_Btn_Feed 0 "Off" 1 "On" ;
VAL_ 851 FCAM_ACC_DistSet_upper_Feed 0 "-" 1 "Up_Feed" ;
VAL_ 851 FCAM_ACC_TimeGapSet 0 "No time gap" 1 "1st level distance" 2 "2nd level distance" 3 "3rd level distance" 4 "4th level distance" 5 "Reserved" 6 "Reserved" ;
VAL_ 851 FCAM_ACC_State 0 "Passive" 1 "Stand by state" 2 "Active" 3 "Override" 4 "Brake Only" 5 "Standstill Active" 6 "Standstill Wait" 7 "Fault" 8 "OFF State" ;
VAL_ 851 FCAM_ACC_PopUp_Feed 0 "-" 1 "None (Feature On)" 2 "None (Feature Off)" 3 "Press gas pedal to re-engage the function" 4 "Speed Assist is unavailable Conditions not met" 5 "Resume not available Please activate Speed Assist button" 6 "Speed Assist is unavailable See Fault Details for more ingo" 7 "Speed Assist will off below 20kph. Issue with vehicle sensors" 8 "Take over driving now!" 9 "Take over driving now!Speed Assist Off" 10 "Take Over Driving , ACC Overspeed Occur!" 11 "Take over driving! Curvature max reached" 12 "Reserved" 13 "Reserved" 14 "Reserved" 15 "Reserved" ;
VAL_ 851 FCAM_ACC_check 0 "Available" 1 "Temporarily not available" 2 "Permanently not available" ;
VAL_ 851 FCAM_ISA_ICON_Feed 0 "Off" 1 "Gray ICON" 2 "Green ICON" 3 "White ICON" 4 "Yellow ICON" 5 "Red ICON" ;
VAL_ 851 FCAM_ACC_DistSet_lower_Feed 0 "-" 1 "Down_Feed" ;
VAL_ 851 FCAM_ACC_SpdSet_upper_Feed 0 "-" 1 "Up_Feed" ;
VAL_ 851 FCAM_ACC_SpdSet_lower_Feed 0 "-" 1 "Down_Feed" ;
VAL_ 851 FCAM_ACC_On_Feed 0 "Off" 1 "On" ;
VAL_ 851 FCAM_ACC_Set_Feed 0 "-" 1 "Set_Feed" ;
VAL_ 851 FCAM_ACC_CnlBtn_Feed 0 "-" 1 "Cancel_Feed" ;
VAL_ 851 FCAM_ACC_Res_Feed 0 "-" 1 "Res_Feed" ;
VAL_ 851 FCAM_ACC_ICON_Feed 0 "Off" 1 "Gray ICON" 2 "Green ICON" 3 "White ICON" 4 "Yellow ICON" 5 "Red ICON" ;
VAL_ 851 FCAM_ISA_Status 0 "OFF State" 1 "Passive" 2 "Standby" 3 "Active" 4 "Fault" ;
VAL_ 851 FCAM_ACC_DriveOff 0 "No request" 1 "DriveOff Request" ;
VAL_ 890 FCAM_EPS_StrWhe_TOLAct 0 "Deactivate Torque Overlay" 1 "Activate Torque Overlay" 2 " Reserve" 3 "Reserve" ;
VAL_ 890 FCAM_EPS_StrWhe_AOLAct 0 "Deactivate Angle Overlay" 1 "Activate Angle Overlay" 2 " Reserve" 3 "Reserve" ;
VAL_ 1117 FCAM_HeaterActivation_Req 0 "false" 1 "true" ;
VAL_ 853 FCAM_ADAS_CDSMaster_BasicCruise 0 "Unsupported" 1 "Without" 2 " With" 3 "Invalid" ;
VAL_ 853 FCAM_ADAS_CDSMaster_ALCA 0 "Unsupported" 1 "Without" 2 " With" 3 "Invalid" ;
VAL_ 853 FCAM_ADAS_CDSMaster_AESA 0 "Unsupported" 1 "Without" 2 " With" 3 "Invalid" ;
VAL_ 853 FCAM_ADAS_CDSMaster_HWA 0 "Unsupported" 1 "Without" 2 " With" 3 "Invalid" ;
VAL_ 853 FCAM_ADAS_CDSMaster_NOP 0 "Unsupported" 1 "Without" 2 " With" 3 "Invalid" ;
VAL_ 853 FCAM_ADAS_CDSMaster_ISA 0 "Unsupported" 1 "Without" 2 " With" 3 "Invalid" ;
VAL_ 853 FCAM_ADAS_CDSMaster_TSR 0 "Unsupported" 1 "Without" 2 " With" 3 "Invalid" ;
VAL_ 853 FCAM_ADAS_CDSMaster_ACC 0 "Unsupported" 1 "Without" 2 " With" 3 "Invalid" ;
VAL_ 853 FCAM_ADAS_CDSMaster_TLD 0 "Unsupported" 1 "Without" 2 " With" 3 "Invalid" ;
VAL_ 853 FCAM_ADAS_CDSMaster_AACC 0 "Unsupported" 1 "Without" 2 " With" 3 "Invalid" ;
VAL_ 853 FCAM_ADAS_CDSMaster_ALCM 0 "Unsupported" 1 "Without" 2 " With" 3 "Invalid" ;
VAL_ 853 FCAM_ADAS_CDSMaster_AAESA 0 "Unsupported" 1 "Without" 2 " With" 3 "Invalid" ;
VAL_ 853 FCAM_ADAS_CDSMaster_ELK 0 "Unsupported" 1 "Without" 2 " With" 3 "Invalid" ;
VAL_ 853 FCAM_ADAS_CDSMaster_LKA 0 "Unsupported" 1 "Without" 2 " With" 3 "Invalid" ;
VAL_ 853 FCAM_ADAS_CDSMaster_LDW 0 "Unsupported" 1 "Without" 2 " With" 3 "Invalid" ;
VAL_ 853 FCAM_ADAS_CDSMaster_DNS 0 "Unsupported" 1 "Without" 2 " With" 3 "Invalid" ;
VAL_ 853 FCAM_ADAS_CDSMaster_FCW 0 "Unsupported" 1 "Without" 2 " With" 3 "Invalid" ;
VAL_ 853 FCAM_ADAS_CDSMaster_RAEB 0 "Unsupported" 1 "Without" 2 " With" 3 "Invalid" ;
VAL_ 853 FCAM_ADAS_CDSMaster_ESA 0 "Unsupported" 1 "Without" 2 " With" 3 "Invalid" ;
VAL_ 853 FCAM_ADAS_CDSMaster_FAEB 0 "Unsupported" 1 "Without" 2 " With" 3 "Invalid" ;
VAL_ 853 FCAM_ADAS_CDSMaster_RPA 0 "Unsupported" 1 "Without" 2 " With" 3 "Invalid" ;
VAL_ 853 FCAM_ADAS_CDSMaster_FPA 0 "Unsupported" 1 "Without" 2 " With" 3 "Invalid" ;
VAL_ 853 FCAM_ADAS_CDSMaster_RVC 0 "Unsupported" 1 "Without" 2 " With" 3 "Invalid" ;
VAL_ 853 FCAM_ADAS_CDSMaster_SVM 0 "Unsupported" 1 "Without" 2 " With" 3 "Invalid" ;
VAL_ 853 FCAM_ADAS_CDSMaster_VParkingComf 0 "Unsupported" 1 "Without" 2 " With" 3 "Invalid" ;
VAL_ 853 FCAM_ADAS_CDSMaster_VParkingSele 0 "Unsupported" 1 "Without" 2 " With" 3 "Invalid" ;
VAL_ 853 FCAM_ADAS_CDSMaster_RP 0 "Unsupported" 1 "Without" 2 " With" 3 "Invalid" ;
VAL_ 853 FCAM_ADAS_CDSMaster_SpaFAPA 0 "Unsupported" 1 "Without" 2 " With" 3 "Invalid" ;
VAL_ 853 FCAM_ADAS_CDSMaster_ADB 0 "Unsupported" 1 "Without" 2 " With" 3 "Invalid" ;
VAL_ 853 FCAM_ADAS_CDSMaster_AHB 0 "Unsupported" 1 "Without" 2 " With" 3 "Invalid" ;
VAL_ 853 FCAM_ADAS_CDSMaster_VParkingAuto 0 "Unsupported" 1 "Without" 2 " With" 3 "Invalid" ;
VAL_ 853 FCAM_ADAS_CDSMaster_VParkingSumm 0 "Unsupported" 1 "Without" 2 " With" 3 "Invalid" ;
VAL_ 853 FCAM_ADAS_CDSMaster_AdasEDR 0 "Unsupported" 1 "Without" 2 " With" 3 "Invalid" ;
VAL_ 853 FCAM_ADAS_CDSMaster_DCM 0 "Unsupported" 1 "Without" 2 " With" 3 "Invalid" ;
VAL_ 853 FCAM_ADAS_CDSMaster_DMSFaceID 0 "Unsupported" 1 "Without" 2 " With" 3 "Invalid" ;
VAL_ 853 FCAM_ADAS_CDSMaster_DMS 0 "Unsupported" 1 "Without" 2 " With" 3 "Invalid" ;
VAL_ 853 FCAM_ADAS_CDSMaster_L2_L2PLUS 0 "L2 Variant (without ADCU)" 1 "L2+ Variant (with ADCU)" 2 " Reserved" 3 "Invalid" ;
VAL_ 853 FCAM_ADAS_CDSMaster_SentryMode 0 "Unsupported" 1 "Without" 2 " With" 3 "Invalid" ;
VAL_ 853 FCAM_ADAS_CDSMaster_ACPE 0 "Unsupported" 1 "Without" 2 " With" 3 "Invalid" ;
VAL_ 311 EAS_StiffStsFL 0 "soft" 1 "hard" ;
VAL_ 311 EAS_StiffStsFR 0 "soft" 1 "hard" ;
VAL_ 311 EAS_StiffStsRL 0 "soft" 1 "hard" ;
VAL_ 311 EAS_StiffStsRR 0 "soft" 1 "hard" ;
VAL_ 311 EAS_WorkSts 0 "Normal" 1 "warning" 2 "Limited" 3 "Stop" ;
VAL_ 311 CDC_WorkSts 0 "Normal" 1 "warning" 2 "Limited" 3 "Stop" ;
VAL_ 311 EAS_CDC_SystemWorkMode 0 "Normal" 1 "Transportation mode" 2 "Maintenance mode" 3 "Reserved" ;
VAL_ 311 EAS_SuspensionMode 0 "Low" 1 "Standard" 2 "High" 3 "Auto" ;
VAL_ 311 EAS_EasyAccessSts 0 "ON" 1 "OFF" 2 "Invalid" 3 "Invalid" ;
VAL_ 311 CDC_DamperMode 0 "Comfort" 1 "Standard" 2 "Sport" 3 "Reserved" ;
VAL_ 311 EAS_ValveValue_FL 0 "close" 1 "insufflation" 2 "deflate" 3 "PreCheck" 4 "error" 7 "invalid" ;
VAL_ 311 EAS_ValveValue_FR 0 "close" 1 "insufflation" 2 "deflate" 3 "PreCheck" 4 "error" 7 "invalid" ;
VAL_ 311 EAS_ValveValue_RL 0 "close" 1 "insufflation" 2 "deflate" 3 "PreCheck" 4 "error" 7 "invalid" ;
VAL_ 311 EAS_ValveValue_RR 0 "close" 1 "insufflation" 2 "deflate" 3 "PreCheck" 4 "error" 7 "invalid" ;
VAL_ 311 EAS_EnableSts 0 "Enable" 1 "Disable" ;
VAL_ 311 CDC_ValveValue_FL 0 "Normal" 1 "Error" ;
VAL_ 311 CDC_ValveValue_FR 0 "Normal" 1 "Error" ;
VAL_ 311 CDC_ValveValue_RL 0 "Normal" 1 "Error" ;
VAL_ 311 CDC_ValveValue_RR 0 "Normal" 1 "Error" ;
VAL_ 311 EAS_MntnSts 0 "Normal Status" 1 "maintenance Status" ;
VAL_ 311 EAS_EasyLoadingSetFb 0 "Initializing" 1 "OFF" 2 "ON" 3 "Reserved" ;
VAL_ 311 EAS_LiftModFb 0 "No Lift and Jack" 1 "AutoLift Mode" 2 "AutoJack Mode" 3 "invalid" ;
VAL_ 311 EAS_VehicleUpDownState 0 "stangby" 1 "up" 2 "down" 3 "Reserved" ;
VAL_ 311 EAS_Overheat_Warning 0 "No failure" 1 "Warnig for overheat" ;
VAL_ 311 EAS_VehiclePositionState 0 "Initializing" 1 "High" 2 "Middle" 3 "Low" 4 "easy Entry level" 5 "easy Loading level" 6 "Reserved" ;
VAL_ 311 EAS_VehicleTargetPositionState 0 "Initializing" 1 "High" 2 "Middle" 3 "Low" 4 "easy Entry level" 5 "easy Loading level" 6 "Reserved" ;
VAL_ 555 ADCU_ACC_IDB_DecCmdAct 0 "No Deceleration" 1 "Deceleration" ;
VAL_ 555 ADCU_ACC_StandstillReq 0 "No request" 1 "Stop control is required" ;
VAL_ 555 ADCU_ACC_Information 0 "System without error" 1 "Performance Degraded" 2 "Temporary unavailable" 3 "ACC Service Required" ;
VAL_ 555 ADCU_ACC_DriveOff 0 "No request" 1 "DriveOff Request" ;
VAL_ 555 ADCU_EPS_StrWhe_AOLAct 0 "'Deactivate Angle Overlay" 1 "Activate Angle Overlay" 2 "Reserved" 3 "Reserved" ;
VAL_ 555 ADCU_EPS_StrWhe_TOLAct 0 "'Deactivate Torque Overlay" 1 "Activate Torque Overlay" 2 "Reserved" 3 "Reserved" ;
VAL_ 555 ADCU_LSS_Activation 0 "No activation" 1 "LKA activation" 2 "ELK activation" 3 "TJA activation" 4 "Reserved" 5 "Reserved" 6 "Reserved" ;
VAL_ 555 ADCU_LSS_Activation_2 0 "No activation" 1 "ESA activation" 2 "HWA activation" 3 "NOP activation" 4 "Reserved" 5 "Reserved" 6 "Reserved" ;
VAL_ 555 ADCU_NOP_state 0 "Off" 1 "Standby" 2 "Active" 3 "Override" 4 "Passive" 5 "Downgrade to HWA_ALCA" 6 "MRM" 7 "Fault" 8 "Downgrade to ACC" 9 "Reserved" 10 "Reserved" 11 "Reserved" 12 "Reserved" 13 "Reserved" 14 "Reserved" 15 "Reserved" ;
VAL_ 678 ADCU_FCAM_MM_State 0 "state 0" 1 "state 1" 2 "state 2" 3 "state 3" 4 "state 4" 5 "state 5" 6 "state 6" 7 "state 7" 8 "state 8" 9 "state 9" 10 "state 10" 11 "state 11" 12 "state 12" 13 "state 13" 14 "state 14" 15 "state 15" ;
VAL_ 678 ADCU_FCAM_MM_Status 0 "value 0" 1 "value 1" 2 "value 2" 3 "value 3" ;
VAL_ 678 ADCU_FCAM_MM_ODD 0 "value 0" 1 "value 1" 2 "value 2" 3 "value 3" ;
VAL_ 678 ADCU_FCAM_MM_VAP_State 0 "state 0" 1 "state 1" 2 "state 2" 3 "state 3" 4 "state 4" 5 "state 5" 6 "state 6" 7 "state 7" 8 "state 8" 9 "state 9" 10 "state 10" 11 "state 11" 12 "state 12" 13 "state 13" 14 "state 14" 15 "state 15" ;
VAL_ 678 ADCU_FCAM_MM_NOP_State 0 "state 0" 1 "state 1" 2 "state 2" 3 "state 3" 4 "state 4" 5 "state 5" 6 "state 6" 7 "state 7" 8 "state 8" 9 "state 9" 10 "state 10" 11 "state 11" 12 "state 12" 13 "state 13" 14 "state 14" 15 "state 15" ;
VAL_ 678 ADCU_FCAM_MM_HWA_State 0 "state 0" 1 "state 1" 2 "state 2" 3 "state 3" 4 "state 4" 5 "state 5" 6 "state 6" 7 "state 7" 8 "state 8" 9 "state 9" 10 "state 10" 11 "state 11" 12 "state 12" 13 "state 13" 14 "state 14" 15 "state 15" ;
VAL_ 678 ADCU_FCAM_MM_ACC_State 0 "state 0" 1 "state 1" 2 "state 2" 3 "state 3" 4 "state 4" 5 "state 5" 6 "state 6" 7 "state 7" 8 "state 8" 9 "state 9" 10 "state 10" 11 "state 11" 12 "state 12" 13 "state 13" 14 "state 14" 15 "state 15" ;
VAL_ 678 ADCU_FCAM_MM_OnChanging 0 "value 0" 1 "value 1" ;
VAL_ 678 ADCU_NOP_Ctrl 0 "state 0" 1 "state 1" 2 "state 2" 3 "state 3" 4 "state 4" 5 "state 5" 6 "state 6" 7 "state 7" 8 "state 8" 9 "state 9" 10 "state 10" 11 "state 11" 12 "state 12" 13 "state 13" 14 "state 14" 15 "state 15" ;
VAL_ 693 FCAM_ADCU_MM_State 0 "state 0" 1 "state 1" 2 "state 2" 3 "state 3" 4 "state 4" 5 "state 5" 6 "state 6" 7 "state 7" 8 "state 8" 9 "state 9" 10 "state 10" 11 "state 11" 12 "state 12" 13 "state 13" 14 "state 14" 15 "state 15" ;
VAL_ 693 FCAM_ADCU_MM_Status 0 "value 0" 1 "value 1" 2 "value 2" 3 "value 3" ;
VAL_ 693 FCAM_ADCU_MM_ODD 0 "value 0" 1 "value 1" 2 "value 2" 3 "value 3" ;
VAL_ 693 FCAM_ADCU_MM_VAP_State 0 "state 0" 1 "state 1" 2 "state 2" 3 "state 3" 4 "state 4" 5 "state 5" 6 "state 6" 7 "state 7" 8 "state 8" 9 "state 9" 10 "state 10" 11 "state 11" 12 "state 12" 13 "state 13" 14 "state 14" 15 "state 15" ;
VAL_ 693 FCAM_ADCU_MM_NOP_State 0 "state 0" 1 "state 1" 2 "state 2" 3 "state 3" 4 "state 4" 5 "state 5" 6 "state 6" 7 "state 7" 8 "state 8" 9 "state 9" 10 "state 10" 11 "state 11" 12 "state 12" 13 "state 13" 14 "state 14" 15 "state 15" ;
VAL_ 693 FCAM_ADCU_MM_HWA_State 0 "state 0" 1 "state 1" 2 "state 2" 3 "state 3" 4 "state 4" 5 "state 5" 6 "state 6" 7 "state 7" 8 "state 8" 9 "state 9" 10 "state 10" 11 "state 11" 12 "state 12" 13 "state 13" 14 "state 14" 15 "state 15" ;
VAL_ 693 FCAM_ADCU_MM_ACC_State 0 "state 0" 1 "state 1" 2 "state 2" 3 "state 3" 4 "state 4" 5 "state 5" 6 "state 6" 7 "state 7" 8 "state 8" 9 "state 9" 10 "state 10" 11 "state 11" 12 "state 12" 13 "state 13" 14 "state 14" 15 "state 15" ;
VAL_ 693 FCAM_ADCU_MM_OnChanging 0 "value 0" 1 "value 1" ;
VAL_ 821 ADCU_AEB_Prefill 0 "No demand" 1 "Demand" ;
VAL_ 821 ADCU_AEB_HBA_Level 0 "Standard threshold" 1 "Lowered threshold 1" 2 "Lowered threshold 2" 3 "Lowered threshold 3" ;
VAL_ 821 ADCU_AEB_HBA_Req 0 "No request" 1 "Request" ;
VAL_ 821 ADCU_AEB_Braking_Progress 0 "No demand" 1 "Demand" ;
VAL_ 821 ADCU_AEB_Hold 0 "No hold" 1 "Hold" ;
VAL_ 821 ADCU_AEB_DBS_Active 0 "DBS Not Activated" 1 "DBS Activated" ;
VAL_ 470 ADCU_TSR_SLWSwtResp 0 "Off" 1 "On" ;
VAL_ 470 ADCU_FC_CalibrationSts 0 "Calibration Success" 1 "Calibration In Process" 2 "Calibration Failed" 3 "Reserved" ;
VAL_ 470 ADCU_BlockageSts 0 "Front Camera Not Blockage" 1 "Front Camera Blockage" ;
VAL_ 470 ADCU_AEB_ABA_Req 0 "No Request" 1 "Request" ;
VAL_ 470 ADCU_AEB_AWB_Req 0 "No Request" 1 "Request" ;
VAL_ 470 ADCU_AEB_TgtDecel_Req 0 "No Request" 1 "Request" ;
VAL_ 470 ADCU_AEB_VehHldReq 0 "No Request" 1 "Request" ;
VAL_ 470 ADCU_AEB_AWB_Level 0 "No level" 1 "Level 1" 2 "Level 2" 3 "Level 3" 4 "Level 4" 5 "Reserved" 6 "Reserved" 7 "Reserved" 8 "Reserved" 9 "Reserved" 10 "Reserved" 11 "Reserved" 12 "Reserved" 13 "Reserved" 14 "Reserved" 15 "Reserved" ;
VAL_ 472 ADCU_FCAM_Alive_Distinguish 0 "ADCU Alive" 1 "ADCU not Alive" ;
VAL_ 472 ADCU_FCAM_CONTROL_SOURCE 0 "FCAM in Control" 1 "ADCU in Control" 2 "Reserved" 3 "Invalid" ;
VAL_ 313 ADCU_LSS_Activation_3 0 "No activation" 1 "LKA activation" 2 "ELK activation" 3 "TJA activation" 4 "Reserved" 5 "Reserved" 6 "Reserved" ;
VAL_ 313 ADCU_LSS_Activation_4 0 "No activation" 1 "ESA activation" 2 "HWA activation" 3 "NOP activation" 4 "Reserved" 5 "Reserved" 6 "Reserved" ;
VAL_ 589 ADCU_RAEB_BrakeCommand 0 "No Request" 1 "Prefill Brake Request" 2 "Emergency brake Request" 3 "Invalid" ;
VAL_ 589 ADCU_RAEB_Available 0 "Not Support'" 1 "Not Available" 2 "Available" 3 "Invalid" ;
VAL_ 589 ADCU_RAEB_FuncActive 0 "Not Active" 1 "Active" ;
VAL_ 589 ADCU_RAEB_BrakeType 0 "No Request" 1 "Comfort Brake" 2 "Normal Emergency Brake" 3 "Emergency Brake" ;
VAL_ 589 ADCU_RAEB_PullEPBOpt 0 "No Request" 1 "Request" ;
VAL_ 640 ADCU_VAP_Status_State 0 "OFF" 1 "Init" 2 "Disable" 3 "Load" 4 "Standby/Idle" 5 "Prepare" 6 "Handshake" 7 "Active" 8 "Completed/Finished" 9 "Suspend/Pause" 10 "Abort" 11 "Degraded" 12 "FailSafe" 13 "Error" 14 "Failure/Fata" 15 "Cancel" ;
VAL_ 640 ADCU_VAP_Status_CVCStat 0 "Idle'" 1 "Active" 2 "Abort" 3 "Error" ;
VAL_ 640 ADCU_VAP_Status_BCMStat 0 "Idle'" 1 "Active" 2 "Abort" 3 "Error" ;
VAL_ 640 ADCU_VAP_Status_EPSStat 0 "Idle'" 1 "Active" 2 "Abort" 3 "Error" ;
VAL_ 640 ADCU_VAP_Status_WCBSStat 0 "Idle'" 1 "Active" 2 "Abort" 3 "Error" ;
VAL_ 640 ADCU_VAP_Status_MHUStat 0 "Idle'" 1 "Active" 2 "Abort" 3 "Error" ;
VAL_ 640 ADCU_VAP_Status_TboxStat 0 "Idle'" 1 "Active" 2 "Abort" 3 "Error" ;
VAL_ 640 ADCU_VAP_Status_DKCUStat 0 "Idle'" 1 "Active" 2 "Abort" 3 "Error" ;
VAL_ 640 ADCU_VAP_Status_CappStat 0 "Idle'" 1 "Active" 2 "Abort" 3 "Error" ;
VAL_ 641 ADCU_WCBS_VAP_Mode 0 "Init'" 1 "Standby" 2 "Startup" 3 "Running" 12 "Stop" ;
VAL_ 641 ADCU_WCBS_VAP_State 0 "OFF" 1 "Init" 2 "Disable" 3 "Load" 4 "Standby/Idle" 5 "Prepare" 6 "Handshake" 7 "Active" 8 "Completed/Finished" 9 "Suspend/Pause" 10 "Abort" 11 "Degraded" 12 "FailSafe" 13 "Error" 14 "Failure/Fata" 15 "Cancel" ;
VAL_ 641 ADCU_WCBS_VAP_ControlReq 0 "No Request" 1 "Request" ;
VAL_ 641 ADCU_WCBS_VAP_BrakeModeReq 0 "No Request" 1 "Comfortable Brake" 2 "Emergency Brake" 3 "Invalid" ;
VAL_ 641 ADCU_WCBS_VAP_StopReq 0 "No Request" 1 "Request" ;
VAL_ 641 ADCU_WCBS_VAP_EPBReq 0 "No Request" 1 "Request" ;
VAL_ 642 ADCU_CVC_VAP_State 0 "OFF" 1 "Init" 2 "Disable" 3 "Load" 4 "Standby/Idle" 5 "Prepare" 6 "Handshake" 7 "Active" 8 "Completed/Finished" 9 "Suspend/Pause" 10 "Abort" 11 "Degraded" 12 "FailSafe" 13 "Error" 14 "Failure/Fata" 15 "Cancel" ;
VAL_ 642 ADCU_CVC_VAP_ControlReq 0 "No Request" 1 "Request" ;
VAL_ 642 ADCU_CVC_VAP_GearReq 0 "No Request" 1 "Request" ;
VAL_ 642 ADCU_BCM_VAP_ControlReq 0 "No Request" 1 "Request" ;
VAL_ 642 ADCU_BCM_VAP_LightReq 0 "No Request" 1 "Request" ;
VAL_ 642 ADCU_BCM_VAP_Lights 0 "OFF" 1 "ON" ;
VAL_ 642 ADCU_BCM_VAP_IndicatorLightReq 0 "No Request" 1 "Request" ;
VAL_ 642 ADCU_BCM_VAP_IndicatorLights 0 "OFF" 1 "TurnLeft" 2 "TurnRight" 3 "Emergency" ;
VAL_ 642 ADCU_BCM_VAP_MirrorReq 0 "No Request" 1 "Request" ;
VAL_ 642 ADCU_BCM_VAP_Mirrors 0 "OFF" 1 "Fold" 2 "Unfold" 3 "Invalid" ;
VAL_ 642 ADCU_BCM_VAP_WindowReq 0 "No Request" 1 "Request" ;
VAL_ 642 ADCU_BCM_VAP_Windows 0 "OFF" 1 "Close" 2 "Open" 3 "Invalid" ;
VAL_ 642 ADCU_BCM_VAP_DoorReq 0 "No Request" 1 "Request" ;
VAL_ 642 ADCU_BCM_VAP_Doors 0 "OFF" 1 "Lock" 2 "Unlock" 3 "Invalid" ;
VAL_ 642 ADCU_BCM_VAP_TrunkReq 0 "No Request" 1 "Request" ;
VAL_ 642 ADCU_BCM_VAP_HornReq 0 "No Request" 1 "Request" ;
VAL_ 642 ADCU_CVC_VAP_GearPosReq 0 "P" 1 "R" 2 "N" 3 "D" 4 "P/Termination" 5 "Reserved" 6 "Reserved" 7 "Invalid" ;
VAL_ 643 ADCU_EPS_VAP_State 0 "OFF" 1 "Init" 2 "Disable" 3 "Load" 4 "Standby/Idle" 5 "Prepare" 6 "Handshake" 7 "Active" 8 "Completed/Finished" 9 "Suspend/Pause" 10 "Abort" 11 "Degraded" 12 "FailSafe" 13 "Error" 14 "Failure/Fata" 15 "Cancel" ;
VAL_ 643 ADCU_EPS_VAP_ControlReq 0 "No Request" 1 "Request" ;
